VERSION "dbc-export 1 2026.26.6.5"

NS_ :

BS_:

BU_: APB APP APS DAS EPAS3S ESP GTW IBST PARK RADC RCM RCM2 RCM3 TPMS TRCM USM

BO_ 882 TRCM_alertMatrix: 8 TRCM
 SG_ TRCM_matrixIndex M : 0|4@1+ (1,0) [0|15] "" Vector__XXX
 SG_ TRCM_a001_airbagsDisabled m0 : 4|1@1+ (1,0) [0|1] "" Vector__XXX
 SG_ TRCM_a002_systemDisabled m0 : 5|1@1+ (1,0) [0|1] "" Vector__XXX
 SG_ TRCM_a003_SWAssertion m0 : 6|1@1+ (1,0) [0|1] "" Vector__XXX
 SG_ TRCM_a004_internalFailure m0 : 7|1@1+ (1,0) [0|1] "" Vector__XXX
 SG_ TRCM_a005_CANTXError m0 : 8|1@1+ (1,0) [0|1] "" Vector__XXX
 SG_ TRCM_a006_CANTX_cyclicError m0 : 9|1@1+ (1,0) [0|1] "" Vector__XXX
 SG_ TRCM_a007_chassisChecksumError m0 : 10|1@1+ (1,0) [0|1] "" Vector__XXX
 SG_ TRCM_a008_chassisCounterError m0 : 11|1@1+ (1,0) [0|1] "" Vector__XXX
 SG_ TRCM_a009_partyChecksumError m0 : 12|1@1+ (1,0) [0|1] "" Vector__XXX
 SG_ TRCM_a010_partyCounterError m0 : 13|1@1+ (1,0) [0|1] "" Vector__XXX
 SG_ TRCM_a011_edrDataLocked m0 : 14|1@1+ (1,0) [0|1] "" Vector__XXX
 SG_ TRCM_a012_asm5TemperatureOutside m0 : 15|1@1+ (1,0) [0|1] "" Vector__XXX
 SG_ TRCM_a013_AlertManagerFault m0 : 16|1@1+ (1,0) [0|1] "" Vector__XXX
 SG_ TRCM_a014_asm3TemperatureOutside m0 : 17|1@1+ (1,0) [0|1] "" Vector__XXX
 SG_ TRCM_a015_NVMMError m0 : 18|1@1+ (1,0) [0|1] "" Vector__XXX
 SG_ TRCM_a016_NVMMRecordError m0 : 19|1@1+ (1,0) [0|1] "" Vector__XXX
 SG_ TRCM_a017_asm5TemperatureOutside m0 : 20|1@1+ (1,0) [0|1] "" Vector__XXX
 SG_ TRCM_a018_asm3TemperatureOutside m0 : 21|1@1+ (1,0) [0|1] "" Vector__XXX
 SG_ TRCM_a019_Task500usError m0 : 22|1@1+ (1,0) [0|1] "" Vector__XXX
 SG_ TRCM_a020_asm3ComStatusError m0 : 23|1@1+ (1,0) [0|1] "" Vector__XXX
 SG_ TRCM_a021_TaskSchedulerError m0 : 24|1@1+ (1,0) [0|1] "" Vector__XXX
 SG_ TRCM_a022_TaskInitError m0 : 25|1@1+ (1,0) [0|1] "" Vector__XXX
 SG_ TRCM_a023_asm3ArsStatusXError m0 : 26|1@1+ (1,0) [0|1] "" Vector__XXX
 SG_ TRCM_a024_asm3AccStatusError m0 : 27|1@1+ (1,0) [0|1] "" Vector__XXX
 SG_ TRCM_a025_CHCANBusFaults m0 : 28|1@1+ (1,0) [0|1] "" Vector__XXX
 SG_ TRCM_a026_airbagAsicDiagnosticFa m0 : 29|1@1+ (1,0) [0|1] "" Vector__XXX
 SG_ TRCM_a027_airbagAsicDeploymentDi m0 : 30|1@1+ (1,0) [0|1] "" Vector__XXX
 SG_ TRCM_a028_chassisLengthError m0 : 31|1@1+ (1,0) [0|1] "" Vector__XXX
 SG_ TRCM_a030_ECULogUploadRequest m0 : 33|1@1+ (1,0) [0|1] "" Vector__XXX
 SG_ TRCM_a031_UDSActive m0 : 34|1@1+ (1,0) [0|1] "" Vector__XXX
 SG_ TRCM_a032_ScrollCreated m0 : 35|1@1+ (1,0) [0|1] "" Vector__XXX
 SG_ TRCM_a033_HercLogCreated m0 : 36|1@1+ (1,0) [0|1] "" Vector__XXX
 SG_ TRCM_a034_apClipTrigger m0 : 37|1@1+ (1,0) [0|1] "" Vector__XXX
 SG_ TRCM_a035_hvDisconnectCommanded m0 : 38|1@1+ (1,0) [0|1] "" Vector__XXX
 SG_ TRCM_a036_crashDetected m0 : 39|1@1+ (1,0) [0|1] "" Vector__XXX
 SG_ TRCM_a037_nearDeploy m0 : 40|1@1+ (1,0) [0|1] "" Vector__XXX
 SG_ TRCM_a038_ens1Degraded m0 : 41|1@1+ (1,0) [0|1] "" Vector__XXX
 SG_ TRCM_a039_ens2Degraded m0 : 42|1@1+ (1,0) [0|1] "" Vector__XXX
 SG_ TRCM_a040_task500usOverrunDebug m0 : 43|1@1+ (1,0) [0|1] "" Vector__XXX
 SG_ TRCM_a041_HighCPULoad m0 : 44|1@1+ (1,0) [0|1] "" Vector__XXX
 SG_ TRCM_a042_HighStackUsage m0 : 45|1@1+ (1,0) [0|1] "" Vector__XXX
 SG_ TRCM_a043_Task1msError m0 : 46|1@1+ (1,0) [0|1] "" Vector__XXX
 SG_ TRCM_a044_Task10msError m0 : 47|1@1+ (1,0) [0|1] "" Vector__XXX
 SG_ TRCM_a045_Task100msError m0 : 48|1@1+ (1,0) [0|1] "" Vector__XXX
 SG_ TRCM_a046_Task1000msError m0 : 49|1@1+ (1,0) [0|1] "" Vector__XXX
 SG_ TRCM_a047_vinNotLearned m0 : 50|1@1+ (1,0) [0|1] "" Vector__XXX
 SG_ TRCM_a048_vinMismatch m0 : 51|1@1+ (1,0) [0|1] "" Vector__XXX
 SG_ TRCM_a049_nvmDebugInfo m0 : 52|1@1+ (1,0) [0|1] "" Vector__XXX
 SG_ TRCM_a050_partyLengthError m0 : 53|1@1+ (1,0) [0|1] "" Vector__XXX
 SG_ TRCM_a051_systemSelfTestTimeout m0 : 54|1@1+ (1,0) [0|1] "" Vector__XXX
 SG_ TRCM_a057_HVP_MIA m0 : 60|1@1+ (1,0) [0|1] "" Vector__XXX
 SG_ TRCM_a058_inputRHighSyncDebug m0 : 61|1@1+ (1,0) [0|1] "" Vector__XXX
 SG_ TRCM_a059_inputResistanceHigh m0 : 62|1@1+ (1,0) [0|1] "" Vector__XXX
 SG_ TRCM_a060_engineeringBuild m0 : 63|1@1+ (1,0) [0|1] "" Vector__XXX
 SG_ TRCM_a061_XCPConnected m1 : 4|1@1+ (1,0) [0|1] "" Vector__XXX
 SG_ TRCM_a062_XCPWasConnected m1 : 5|1@1+ (1,0) [0|1] "" Vector__XXX
 SG_ TRCM_a063_SwitchFault m1 : 6|1@1+ (1,0) [0|1] "" Vector__XXX
 SG_ TRCM_a064_busSleepReqTimeout m1 : 7|1@1+ (1,0) [0|1] "" Vector__XXX
 SG_ TRCM_a065_vSafingFetUnderVoltage m1 : 8|1@1+ (1,0) [0|1] "" Vector__XXX
 SG_ TRCM_a066_leftPowerIssue m1 : 9|1@1+ (1,0) [0|1] "" Vector__XXX
 SG_ TRCM_a067_rightPowerIssue m1 : 10|1@1+ (1,0) [0|1] "" Vector__XXX
 SG_ TRCM_a068_vBusCUnderVoltage m1 : 11|1@1+ (1,0) [0|1] "" Vector__XXX
 SG_ TRCM_a069_swAppBoot m1 : 12|1@1+ (1,0) [0|1] "" Vector__XXX
 SG_ TRCM_a070_asm3StatusError m1 : 13|1@1+ (1,0) [0|1] "" Vector__XXX
 SG_ TRCM_a071_asm3DeviceFaulted m1 : 14|1@1+ (1,0) [0|1] "" Vector__XXX
 SG_ TRCM_a072_ais2120StatusError m1 : 15|1@1+ (1,0) [0|1] "" Vector__XXX
 SG_ TRCM_a073_ais2120DeviceFaulted m1 : 16|1@1+ (1,0) [0|1] "" Vector__XXX
 SG_ TRCM_a074_ais2120SelfTestXPositi m1 : 17|1@1+ (1,0) [0|1] "" Vector__XXX
 SG_ TRCM_a075_ais2120SelfTestXNegati m1 : 18|1@1+ (1,0) [0|1] "" Vector__XXX
 SG_ TRCM_a076_ais2120SelfTestYPositi m1 : 19|1@1+ (1,0) [0|1] "" Vector__XXX
 SG_ TRCM_a077_ais2120SelfTestYNegati m1 : 20|1@1+ (1,0) [0|1] "" Vector__XXX
 SG_ TRCM_a078_imuSensorSignalMonitor m1 : 21|1@1+ (1,0) [0|1] "" Vector__XXX
 SG_ TRCM_a081_powerLossDetected m1 : 24|1@1+ (1,0) [0|1] "" Vector__XXX
 SG_ TRCM_a082_VCRIGHT_IPC_MIA m1 : 25|1@1+ (1,0) [0|1] "" Vector__XXX
 SG_ TRCM_a083_VCLEFT_IPC_MIA m1 : 26|1@1+ (1,0) [0|1] "" Vector__XXX
 SG_ TRCM_a084_TPMS_MIA m1 : 27|1@1+ (1,0) [0|1] "" Vector__XXX
 SG_ TRCM_a085_CCCM_MIA m1 : 28|1@1+ (1,0) [0|1] "" Vector__XXX
 SG_ TRCM_a086_VCBATT_MIA m1 : 29|1@1+ (1,0) [0|1] "" Vector__XXX
 SG_ TRCM_a087_DIREL_MIA m1 : 30|1@1+ (1,0) [0|1] "" Vector__XXX
 SG_ TRCM_a088_DIRER_MIA m1 : 31|1@1+ (1,0) [0|1] "" Vector__XXX
 SG_ TRCM_a089_IBST_MIA m1 : 32|1@1+ (1,0) [0|1] "" Vector__XXX
 SG_ TRCM_a090_APS_MIA m1 : 33|1@1+ (1,0) [0|1] "" Vector__XXX
 SG_ TRCM_a091_CMPD_MIA m1 : 34|1@1+ (1,0) [0|1] "" Vector__XXX
 SG_ TRCM_a092_VCSEATD_MIA m1 : 35|1@1+ (1,0) [0|1] "" Vector__XXX
 SG_ TRCM_a093_VCSEATP_MIA m1 : 36|1@1+ (1,0) [0|1] "" Vector__XXX
 SG_ TRCM_a094_EPAS3P_MIA m1 : 37|1@1+ (1,0) [0|1] "" Vector__XXX
 SG_ TRCM_a095_CHG_MIA m1 : 38|1@1+ (1,0) [0|1] "" Vector__XXX
 SG_ TRCM_a096_OCS1P_MIA m1 : 39|1@1+ (1,0) [0|1] "" Vector__XXX
 SG_ TRCM_a097_CMP_MIA m1 : 40|1@1+ (1,0) [0|1] "" Vector__XXX
 SG_ TRCM_a098_DIR_MIA m1 : 41|1@1+ (1,0) [0|1] "" Vector__XXX
 SG_ TRCM_a099_PARK_MIA m1 : 42|1@1+ (1,0) [0|1] "" Vector__XXX
 SG_ TRCM_a100_CANbus_MIA m1 : 43|1@1+ (1,0) [0|1] "" Vector__XXX
 SG_ TRCM_a101_PM_MIA m1 : 44|1@1+ (1,0) [0|1] "" Vector__XXX
 SG_ TRCM_a102_PTC_MIA m1 : 45|1@1+ (1,0) [0|1] "" Vector__XXX
 SG_ TRCM_a103_CP_MIA m1 : 46|1@1+ (1,0) [0|1] "" Vector__XXX
 SG_ TRCM_a104_DAS_MIA m1 : 47|1@1+ (1,0) [0|1] "" Vector__XXX
 SG_ TRCM_a105_TAS_MIA m1 : 48|1@1+ (1,0) [0|1] "" Vector__XXX
 SG_ TRCM_a106_PCS_MIA m1 : 49|1@1+ (1,0) [0|1] "" Vector__XXX
 SG_ TRCM_a107_BMS_MIA m1 : 50|1@1+ (1,0) [0|1] "" Vector__XXX
 SG_ TRCM_a108_DIF_MIA m1 : 51|1@1+ (1,0) [0|1] "" Vector__XXX
 SG_ TRCM_a109_RCM_MIA m1 : 52|1@1+ (1,0) [0|1] "" Vector__XXX
 SG_ TRCM_a110_GTW_MIA m1 : 53|1@1+ (1,0) [0|1] "" Vector__XXX
 SG_ TRCM_a111_EPBR_MIA m1 : 54|1@1+ (1,0) [0|1] "" Vector__XXX
 SG_ TRCM_a112_EPBL_MIA m1 : 55|1@1+ (1,0) [0|1] "" Vector__XXX
 SG_ TRCM_a113_UI_MIA m1 : 56|1@1+ (1,0) [0|1] "" Vector__XXX
 SG_ TRCM_a114_ESP_MIA m1 : 57|1@1+ (1,0) [0|1] "" Vector__XXX
 SG_ TRCM_a115_VCSEC_MIA m1 : 58|1@1+ (1,0) [0|1] "" Vector__XXX
 SG_ TRCM_a116_VCRIGHT_MIA m1 : 59|1@1+ (1,0) [0|1] "" Vector__XXX
 SG_ TRCM_a117_VCLEFT_MIA m1 : 60|1@1+ (1,0) [0|1] "" Vector__XXX
 SG_ TRCM_a118_VCFRONT_MIA m1 : 61|1@1+ (1,0) [0|1] "" Vector__XXX
 SG_ TRCM_a119_SCCM_MIA m1 : 62|1@1+ (1,0) [0|1] "" Vector__XXX
 SG_ TRCM_a120_DI_DRIVE_MIA m1 : 63|1@1+ (1,0) [0|1] "" Vector__XXX
 SG_ TRCM_a121_buckleStatusFrontLeftS m2 : 4|1@1+ (1,0) [0|1] "" Vector__XXX
 SG_ TRCM_a122_buckleStatusFrontRight m2 : 5|1@1+ (1,0) [0|1] "" Vector__XXX
 SG_ TRCM_a123_buckleStatusRearLeftSi m2 : 6|1@1+ (1,0) [0|1] "" Vector__XXX
 SG_ TRCM_a124_buckleStatusRearRightS m2 : 7|1@1+ (1,0) [0|1] "" Vector__XXX
 SG_ TRCM_a125_occupantClassification m2 : 8|1@1+ (1,0) [0|1] "" Vector__XXX
 SG_ TRCM_a126_seatTrackPositionLeftS m2 : 9|1@1+ (1,0) [0|1] "" Vector__XXX
 SG_ TRCM_a127_seatTrackPositionRight m2 : 10|1@1+ (1,0) [0|1] "" Vector__XXX
 SG_ TRCM_a135_asm5StatusError m2 : 18|1@1+ (1,0) [0|1] "" Vector__XXX
 SG_ TRCM_a136_asm5DeviceFaulted m2 : 19|1@1+ (1,0) [0|1] "" Vector__XXX
 SG_ TRCM_a137_ext1AsicSnoopTestFaile m2 : 20|1@1+ (1,0) [0|1] "" Vector__XXX
 SG_ TRCM_a138_ext2AsicSnoopTestFaile m2 : 21|1@1+ (1,0) [0|1] "" Vector__XXX
 SG_ TRCM_a145_frontCenterAccelReport m2 : 28|1@1+ (1,0) [0|1] "" Vector__XXX
 SG_ TRCM_a146_frontCenterAccelGenera m2 : 29|1@1+ (1,0) [0|1] "" Vector__XXX
 SG_ TRCM_a147_frontCenterAccelElectr m2 : 30|1@1+ (1,0) [0|1] "" Vector__XXX
 SG_ TRCM_a148_frontCenterAccelConfig m2 : 31|1@1+ (1,0) [0|1] "" Vector__XXX
 SG_ TRCM_a149_frontCenterAccelSignal m2 : 32|1@1+ (1,0) [0|1] "" Vector__XXX
 SG_ TRCM_a150_frontLeftAccelReported m2 : 33|1@1+ (1,0) [0|1] "" Vector__XXX
 SG_ TRCM_a151_frontLeftAccelGeneralI m2 : 34|1@1+ (1,0) [0|1] "" Vector__XXX
 SG_ TRCM_a152_frontLeftAccelElectric m2 : 35|1@1+ (1,0) [0|1] "" Vector__XXX
 SG_ TRCM_a153_frontLeftAccelConfigEr m2 : 36|1@1+ (1,0) [0|1] "" Vector__XXX
 SG_ TRCM_a154_frontLeftAccelSignalMo m2 : 37|1@1+ (1,0) [0|1] "" Vector__XXX
 SG_ TRCM_a155_frontLeftDoorPressureR m2 : 38|1@1+ (1,0) [0|1] "" Vector__XXX
 SG_ TRCM_a156_frontLeftDoorPressureG m2 : 39|1@1+ (1,0) [0|1] "" Vector__XXX
 SG_ TRCM_a157_frontLeftDoorPressureE m2 : 40|1@1+ (1,0) [0|1] "" Vector__XXX
 SG_ TRCM_a158_frontLeftDoorPressureC m2 : 41|1@1+ (1,0) [0|1] "" Vector__XXX
 SG_ TRCM_a159_frontLeftDoorPressureS m2 : 42|1@1+ (1,0) [0|1] "" Vector__XXX
 SG_ TRCM_a160_frontRightAccelReporte m2 : 43|1@1+ (1,0) [0|1] "" Vector__XXX
 SG_ TRCM_a161_frontRightAccelGeneral m2 : 44|1@1+ (1,0) [0|1] "" Vector__XXX
 SG_ TRCM_a162_frontRightAccelElectri m2 : 45|1@1+ (1,0) [0|1] "" Vector__XXX
 SG_ TRCM_a163_frontRightAccelConfigE m2 : 46|1@1+ (1,0) [0|1] "" Vector__XXX
 SG_ TRCM_a164_frontRightAccelSignalM m2 : 47|1@1+ (1,0) [0|1] "" Vector__XXX
 SG_ TRCM_a165_frontRightDoorPressure m2 : 48|1@1+ (1,0) [0|1] "" Vector__XXX
 SG_ TRCM_a166_frontRightDoorPressure m2 : 49|1@1+ (1,0) [0|1] "" Vector__XXX
 SG_ TRCM_a167_frontRightDoorPressure m2 : 50|1@1+ (1,0) [0|1] "" Vector__XXX
 SG_ TRCM_a168_frontRightDoorPressure m2 : 51|1@1+ (1,0) [0|1] "" Vector__XXX
 SG_ TRCM_a169_frontRightDoorPressure m2 : 52|1@1+ (1,0) [0|1] "" Vector__XXX
 SG_ TRCM_a170_leftBPillarAccelReport m2 : 53|1@1+ (1,0) [0|1] "" Vector__XXX
 SG_ TRCM_a171_leftBPillarAccelGenera m2 : 54|1@1+ (1,0) [0|1] "" Vector__XXX
 SG_ TRCM_a172_leftBPillarAccelElectr m2 : 55|1@1+ (1,0) [0|1] "" Vector__XXX
 SG_ TRCM_a173_leftBPillarAccelConfig m2 : 56|1@1+ (1,0) [0|1] "" Vector__XXX
 SG_ TRCM_a174_leftBPillarAccelSignal m2 : 57|1@1+ (1,0) [0|1] "" Vector__XXX
 SG_ TRCM_a175_leftCPillarAccelReport m2 : 58|1@1+ (1,0) [0|1] "" Vector__XXX
 SG_ TRCM_a176_leftCPillarAccelGenera m2 : 59|1@1+ (1,0) [0|1] "" Vector__XXX
 SG_ TRCM_a177_leftCPillarAccelElectr m2 : 60|1@1+ (1,0) [0|1] "" Vector__XXX
 SG_ TRCM_a178_leftCPillarAccelConfig m2 : 61|1@1+ (1,0) [0|1] "" Vector__XXX
 SG_ TRCM_a179_leftCPillarAccelSignal m2 : 62|1@1+ (1,0) [0|1] "" Vector__XXX
 SG_ TRCM_a190_rearLeftDoorPressureRe m3 : 13|1@1+ (1,0) [0|1] "" Vector__XXX
 SG_ TRCM_a191_rearLeftDoorPressureGe m3 : 14|1@1+ (1,0) [0|1] "" Vector__XXX
 SG_ TRCM_a192_rearLeftDoorPressureEl m3 : 15|1@1+ (1,0) [0|1] "" Vector__XXX
 SG_ TRCM_a193_rearLeftDoorPressureCo m3 : 16|1@1+ (1,0) [0|1] "" Vector__XXX
 SG_ TRCM_a194_rearLeftDoorPressureSi m3 : 17|1@1+ (1,0) [0|1] "" Vector__XXX
 SG_ TRCM_a195_rearRightDoorPressureR m3 : 18|1@1+ (1,0) [0|1] "" Vector__XXX
 SG_ TRCM_a196_rearRightDoorPressureG m3 : 19|1@1+ (1,0) [0|1] "" Vector__XXX
 SG_ TRCM_a197_rearRightDoorPressureE m3 : 20|1@1+ (1,0) [0|1] "" Vector__XXX
 SG_ TRCM_a198_rearRightDoorPressureC m3 : 21|1@1+ (1,0) [0|1] "" Vector__XXX
 SG_ TRCM_a199_rearRightDoorPressureS m3 : 22|1@1+ (1,0) [0|1] "" Vector__XXX
 SG_ TRCM_a200_rightBPillarAccelRepor m3 : 23|1@1+ (1,0) [0|1] "" Vector__XXX
 SG_ TRCM_a201_rightBPillarAccelGener m3 : 24|1@1+ (1,0) [0|1] "" Vector__XXX
 SG_ TRCM_a202_rightBPillarAccelElect m3 : 25|1@1+ (1,0) [0|1] "" Vector__XXX
 SG_ TRCM_a203_rightBPillarAccelConfi m3 : 26|1@1+ (1,0) [0|1] "" Vector__XXX
 SG_ TRCM_a204_rightBPillarAccelSigna m3 : 27|1@1+ (1,0) [0|1] "" Vector__XXX
 SG_ TRCM_a205_rightCPillarAccelRepor m3 : 28|1@1+ (1,0) [0|1] "" Vector__XXX
 SG_ TRCM_a206_rightCPillarAccelGener m3 : 29|1@1+ (1,0) [0|1] "" Vector__XXX
 SG_ TRCM_a207_rightCPillarAccelElect m3 : 30|1@1+ (1,0) [0|1] "" Vector__XXX
 SG_ TRCM_a208_rightCPillarAccelConfi m3 : 31|1@1+ (1,0) [0|1] "" Vector__XXX
 SG_ TRCM_a209_rightCPillarAccelSigna m3 : 32|1@1+ (1,0) [0|1] "" Vector__XXX
 SG_ TRCM_a272_asm5ComStatusError m4 : 35|1@1+ (1,0) [0|1] "" Vector__XXX
 SG_ TRCM_a273_asm5ArsStatusXError m4 : 36|1@1+ (1,0) [0|1] "" Vector__XXX
 SG_ TRCM_a274_asm5ArsStatusZError m4 : 37|1@1+ (1,0) [0|1] "" Vector__XXX
 SG_ TRCM_a275_asm5AccStatusError m4 : 38|1@1+ (1,0) [0|1] "" Vector__XXX
 SG_ TRCM_a276_watchdogStatus m4 : 39|1@1+ (1,0) [0|1] "" Vector__XXX
 SG_ TRCM_a278_safingEngine0Armed m4 : 41|1@1+ (1,0) [0|1] "" Vector__XXX
 SG_ TRCM_a279_safingEngine1Armed m4 : 42|1@1+ (1,0) [0|1] "" Vector__XXX
 SG_ TRCM_a280_safingEngine2Armed m4 : 43|1@1+ (1,0) [0|1] "" Vector__XXX
 SG_ TRCM_a281_safingEngine3Armed m4 : 44|1@1+ (1,0) [0|1] "" Vector__XXX
 SG_ TRCM_a282_safingEngine4Armed m4 : 45|1@1+ (1,0) [0|1] "" Vector__XXX
 SG_ TRCM_a283_safingEngine5Armed m4 : 46|1@1+ (1,0) [0|1] "" Vector__XXX
 SG_ TRCM_a284_safingEngine6Armed m4 : 47|1@1+ (1,0) [0|1] "" Vector__XXX
 SG_ TRCM_a285_safingEngine7Armed m4 : 48|1@1+ (1,0) [0|1] "" Vector__XXX
 SG_ TRCM_a286_safingEngine8Armed m4 : 49|1@1+ (1,0) [0|1] "" Vector__XXX
 SG_ TRCM_a287_safingEngine9Armed m4 : 50|1@1+ (1,0) [0|1] "" Vector__XXX
 SG_ TRCM_a288_safingEngine10Armed m4 : 51|1@1+ (1,0) [0|1] "" Vector__XXX
 SG_ TRCM_a289_safingEngine11Armed m4 : 52|1@1+ (1,0) [0|1] "" Vector__XXX
 SG_ TRCM_a290_safingEngine12Armed m4 : 53|1@1+ (1,0) [0|1] "" Vector__XXX
 SG_ TRCM_a291_safingEngine13Armed m4 : 54|1@1+ (1,0) [0|1] "" Vector__XXX
 SG_ TRCM_a292_safingEngine14Armed m4 : 55|1@1+ (1,0) [0|1] "" Vector__XXX
 SG_ TRCM_a293_safingEngine15Armed m4 : 56|1@1+ (1,0) [0|1] "" Vector__XXX
 SG_ TRCM_a294_safingEngine16Armed m4 : 57|1@1+ (1,0) [0|1] "" Vector__XXX
 SG_ TRCM_a295_safingEngine17Armed m4 : 58|1@1+ (1,0) [0|1] "" Vector__XXX
 SG_ TRCM_a296_safingEngine18Armed m4 : 59|1@1+ (1,0) [0|1] "" Vector__XXX
 SG_ TRCM_a297_safingEngine19Armed m4 : 60|1@1+ (1,0) [0|1] "" Vector__XXX
 SG_ TRCM_a298_safingEngine20Armed m4 : 61|1@1+ (1,0) [0|1] "" Vector__XXX
 SG_ TRCM_a299_safingEngine21Armed m4 : 62|1@1+ (1,0) [0|1] "" Vector__XXX
 SG_ TRCM_a300_driverAirbagStage1Supp m4 : 63|1@1+ (1,0) [0|1] "" Vector__XXX
 SG_ TRCM_a301_passengerAirbagStage1S m5 : 4|1@1+ (1,0) [0|1] "" Vector__XXX
 SG_ TRCM_a302_driverAirbagStage2Supp m5 : 5|1@1+ (1,0) [0|1] "" Vector__XXX
 SG_ TRCM_a303_driverAirbagActiveVent m5 : 6|1@1+ (1,0) [0|1] "" Vector__XXX
 SG_ TRCM_a304_passengerAirbagStage2S m5 : 7|1@1+ (1,0) [0|1] "" Vector__XXX
 SG_ TRCM_a305_passengerAirbagActiveV m5 : 8|1@1+ (1,0) [0|1] "" Vector__XXX
 SG_ TRCM_a306_inboardSeatAirbagSuppr m5 : 9|1@1+ (1,0) [0|1] "" Vector__XXX
 SG_ TRCM_a308_kneeAirbagLeftSuppress m5 : 11|1@1+ (1,0) [0|1] "" Vector__XXX
 SG_ TRCM_a309_kneeAirbagRightSuppres m5 : 12|1@1+ (1,0) [0|1] "" Vector__XXX
 SG_ TRCM_a310_curtainAirbagLeftSuppr m5 : 13|1@1+ (1,0) [0|1] "" Vector__XXX
 SG_ TRCM_a311_curtainAirbagRightSupp m5 : 14|1@1+ (1,0) [0|1] "" Vector__XXX
 SG_ TRCM_a312_seatbeltLoadLimiterFro m5 : 15|1@1+ (1,0) [0|1] "" Vector__XXX
 SG_ TRCM_a313_seatbeltLoadLimiterFro m5 : 16|1@1+ (1,0) [0|1] "" Vector__XXX
 SG_ TRCM_a314_seatbeltShoulderPreten m5 : 17|1@1+ (1,0) [0|1] "" Vector__XXX
 SG_ TRCM_a315_seatbeltShoulderPreten m5 : 18|1@1+ (1,0) [0|1] "" Vector__XXX
 SG_ TRCM_a316_seatbeltLapPretensione m5 : 19|1@1+ (1,0) [0|1] "" Vector__XXX
 SG_ TRCM_a317_seatbeltLapPretensione m5 : 20|1@1+ (1,0) [0|1] "" Vector__XXX
 SG_ TRCM_a318_outboardSeatAirbagLeft m5 : 21|1@1+ (1,0) [0|1] "" Vector__XXX
 SG_ TRCM_a319_outboardSeatAirbagRigh m5 : 22|1@1+ (1,0) [0|1] "" Vector__XXX
 SG_ TRCM_a320_hoodLifterLeftSuppress m5 : 23|1@1+ (1,0) [0|1] "" Vector__XXX
 SG_ TRCM_a321_hoodLifterRightSuppres m5 : 24|1@1+ (1,0) [0|1] "" Vector__XXX
 SG_ TRCM_a322_seatbeltShoulderPreten m5 : 25|1@1+ (1,0) [0|1] "" Vector__XXX
 SG_ TRCM_a323_seatbeltShoulderPreten m5 : 26|1@1+ (1,0) [0|1] "" Vector__XXX
 SG_ TRCM_a332_driverAirbagStage1Depl m5 : 35|1@1+ (1,0) [0|1] "" Vector__XXX
 SG_ TRCM_a333_passengerAirbagStage1D m5 : 36|1@1+ (1,0) [0|1] "" Vector__XXX
 SG_ TRCM_a334_driverAirbagStage2Depl m5 : 37|1@1+ (1,0) [0|1] "" Vector__XXX
 SG_ TRCM_a335_driverAirbagActiveVent m5 : 38|1@1+ (1,0) [0|1] "" Vector__XXX
 SG_ TRCM_a336_passengerAirbagStage2D m5 : 39|1@1+ (1,0) [0|1] "" Vector__XXX
 SG_ TRCM_a337_passengerAirbagActiveV m5 : 40|1@1+ (1,0) [0|1] "" Vector__XXX
 SG_ TRCM_a338_inboardSeatAirbagDeplo m5 : 41|1@1+ (1,0) [0|1] "" Vector__XXX
 SG_ TRCM_a340_kneeAirbagLeftDeployed m5 : 43|1@1+ (1,0) [0|1] "" Vector__XXX
 SG_ TRCM_a341_kneeAirbagRightDeploye m5 : 44|1@1+ (1,0) [0|1] "" Vector__XXX
 SG_ TRCM_a342_curtainAirbagLeftDeplo m5 : 45|1@1+ (1,0) [0|1] "" Vector__XXX
 SG_ TRCM_a343_curtainAirbagRightDepl m5 : 46|1@1+ (1,0) [0|1] "" Vector__XXX
 SG_ TRCM_a344_seatbeltLoadLimiterFro m5 : 47|1@1+ (1,0) [0|1] "" Vector__XXX
 SG_ TRCM_a345_seatbeltLoadLimiterFro m5 : 48|1@1+ (1,0) [0|1] "" Vector__XXX
 SG_ TRCM_a346_seatbeltShoulderPreten m5 : 49|1@1+ (1,0) [0|1] "" Vector__XXX
 SG_ TRCM_a347_seatbeltShoulderPreten m5 : 50|1@1+ (1,0) [0|1] "" Vector__XXX
 SG_ TRCM_a348_seatbeltLapPretensione m5 : 51|1@1+ (1,0) [0|1] "" Vector__XXX
 SG_ TRCM_a349_seatbeltLapPretensione m5 : 52|1@1+ (1,0) [0|1] "" Vector__XXX
 SG_ TRCM_a350_outboardSeatAirbagLeft m5 : 53|1@1+ (1,0) [0|1] "" Vector__XXX
 SG_ TRCM_a351_outboardSeatAirbagRigh m5 : 54|1@1+ (1,0) [0|1] "" Vector__XXX
 SG_ TRCM_a352_hoodLifterLeftDeployed m5 : 55|1@1+ (1,0) [0|1] "" Vector__XXX
 SG_ TRCM_a353_hoodLifterRightDeploye m5 : 56|1@1+ (1,0) [0|1] "" Vector__XXX
 SG_ TRCM_a354_seatbeltShoulderPreten m5 : 57|1@1+ (1,0) [0|1] "" Vector__XXX
 SG_ TRCM_a355_seatbeltShoulderPreten m5 : 58|1@1+ (1,0) [0|1] "" Vector__XXX
 SG_ TRCM_a364_safingEngine0NoValidDa m6 : 7|1@1+ (1,0) [0|1] "" Vector__XXX
 SG_ TRCM_a365_safingEngine1NoValidDa m6 : 8|1@1+ (1,0) [0|1] "" Vector__XXX
 SG_ TRCM_a366_safingEngine2NoValidDa m6 : 9|1@1+ (1,0) [0|1] "" Vector__XXX
 SG_ TRCM_a367_safingEngine3NoValidDa m6 : 10|1@1+ (1,0) [0|1] "" Vector__XXX
 SG_ TRCM_a368_safingEngine4NoValidDa m6 : 11|1@1+ (1,0) [0|1] "" Vector__XXX
 SG_ TRCM_a369_safingEngine5NoValidDa m6 : 12|1@1+ (1,0) [0|1] "" Vector__XXX
 SG_ TRCM_a370_safingEngine6NoValidDa m6 : 13|1@1+ (1,0) [0|1] "" Vector__XXX
 SG_ TRCM_a371_safingEngine7NoValidDa m6 : 14|1@1+ (1,0) [0|1] "" Vector__XXX
 SG_ TRCM_a372_safingEngine8NoValidDa m6 : 15|1@1+ (1,0) [0|1] "" Vector__XXX
 SG_ TRCM_a373_safingEngine9NoValidDa m6 : 16|1@1+ (1,0) [0|1] "" Vector__XXX
 SG_ TRCM_a374_safingEngine10NoValidD m6 : 17|1@1+ (1,0) [0|1] "" Vector__XXX
 SG_ TRCM_a375_safingEngine11NoValidD m6 : 18|1@1+ (1,0) [0|1] "" Vector__XXX
 SG_ TRCM_a376_safingEngine12NoValidD m6 : 19|1@1+ (1,0) [0|1] "" Vector__XXX
 SG_ TRCM_a377_safingEngine13NoValidD m6 : 20|1@1+ (1,0) [0|1] "" Vector__XXX
 SG_ TRCM_a378_safingEngine14NoValidD m6 : 21|1@1+ (1,0) [0|1] "" Vector__XXX
 SG_ TRCM_a379_safingEngine15NoValidD m6 : 22|1@1+ (1,0) [0|1] "" Vector__XXX
 SG_ TRCM_a380_safingEngine16NoValidD m6 : 23|1@1+ (1,0) [0|1] "" Vector__XXX
 SG_ TRCM_a381_safingEngine17NoValidD m6 : 24|1@1+ (1,0) [0|1] "" Vector__XXX
 SG_ TRCM_a382_safingEngine18NoValidD m6 : 25|1@1+ (1,0) [0|1] "" Vector__XXX
 SG_ TRCM_a383_safingEngine19NoValidD m6 : 26|1@1+ (1,0) [0|1] "" Vector__XXX
 SG_ TRCM_a384_safingEngine20NoValidD m6 : 27|1@1+ (1,0) [0|1] "" Vector__XXX
 SG_ TRCM_a385_safingEngine21NoValidD m6 : 28|1@1+ (1,0) [0|1] "" Vector__XXX
 SG_ TRCM_a387_primaryAsicResetSource m6 : 30|1@1+ (1,0) [0|1] "" Vector__XXX
 SG_ TRCM_a388_cpuLoadHigh m6 : 31|1@1+ (1,0) [0|1] "" Vector__XXX
 SG_ TRCM_a389_asicPwrStatusError m6 : 32|1@1+ (1,0) [0|1] "" Vector__XXX
 SG_ TRCM_a390_systemAsicClockOrOpera m6 : 33|1@1+ (1,0) [0|1] "" Vector__XXX
 SG_ TRCM_a391_extAsic1ClockOrOperati m6 : 34|1@1+ (1,0) [0|1] "" Vector__XXX
 SG_ TRCM_a392_extAsic2ClockOrOperati m6 : 35|1@1+ (1,0) [0|1] "" Vector__XXX
 SG_ TRCM_a393_depAdcConvertRatioErro m6 : 36|1@1+ (1,0) [0|1] "" Vector__XXX
 SG_ TRCM_a394_gspiGlobalStatusWordEr m6 : 37|1@1+ (1,0) [0|1] "" Vector__XXX
 SG_ TRCM_a395_imuUncalibrated m6 : 38|1@1+ (1,0) [0|1] "" Vector__XXX
 SG_ TRCM_a396_spiCommunicationProgra m6 : 39|1@1+ (1,0) [0|1] "" Vector__XXX
 SG_ TRCM_a397_safingMonitorError m6 : 40|1@1+ (1,0) [0|1] "" Vector__XXX
 SG_ TRCM_a398_asicNvmReprogrammed m6 : 41|1@1+ (1,0) [0|1] "" Vector__XXX
 SG_ TRCM_a399_imuCalibrationComplete m6 : 42|1@1+ (1,0) [0|1] "" Vector__XXX
 SG_ TRCM_a400_driverAirbagStage1Issu m6 : 43|1@1+ (1,0) [0|1] "" Vector__XXX
 SG_ TRCM_a401_passengerAirbagStage1I m6 : 44|1@1+ (1,0) [0|1] "" Vector__XXX
 SG_ TRCM_a402_driverAirbagStage2Issu m6 : 45|1@1+ (1,0) [0|1] "" Vector__XXX
 SG_ TRCM_a403_driverAirbagActiveVent m6 : 46|1@1+ (1,0) [0|1] "" Vector__XXX
 SG_ TRCM_a404_passengerAirbagStage2I m6 : 47|1@1+ (1,0) [0|1] "" Vector__XXX
 SG_ TRCM_a405_passengerAirbagActiveV m6 : 48|1@1+ (1,0) [0|1] "" Vector__XXX
 SG_ TRCM_a406_inboardSeatAirbagIssue m6 : 49|1@1+ (1,0) [0|1] "" Vector__XXX
 SG_ TRCM_a408_kneeAirbagLeftIssue m6 : 51|1@1+ (1,0) [0|1] "" Vector__XXX
 SG_ TRCM_a409_kneeAirbagRightIssue m6 : 52|1@1+ (1,0) [0|1] "" Vector__XXX
 SG_ TRCM_a410_curtainAirbagLeftIssue m6 : 53|1@1+ (1,0) [0|1] "" Vector__XXX
 SG_ TRCM_a411_curtainAirbagRightIssu m6 : 54|1@1+ (1,0) [0|1] "" Vector__XXX
 SG_ TRCM_a412_seatbeltLoadLimiterFro m6 : 55|1@1+ (1,0) [0|1] "" Vector__XXX
 SG_ TRCM_a413_seatbeltLoadLimiterFro m6 : 56|1@1+ (1,0) [0|1] "" Vector__XXX
 SG_ TRCM_a414_seatbeltShoulderPreten m6 : 57|1@1+ (1,0) [0|1] "" Vector__XXX
 SG_ TRCM_a415_seatbeltShoulderPreten m6 : 58|1@1+ (1,0) [0|1] "" Vector__XXX
 SG_ TRCM_a416_seatbeltLapPretensione m6 : 59|1@1+ (1,0) [0|1] "" Vector__XXX
 SG_ TRCM_a417_seatbeltLapPretensione m6 : 60|1@1+ (1,0) [0|1] "" Vector__XXX
 SG_ TRCM_a418_outboardSeatAirbagLeft m6 : 61|1@1+ (1,0) [0|1] "" Vector__XXX
 SG_ TRCM_a419_outboardSeatAirbagRigh m6 : 62|1@1+ (1,0) [0|1] "" Vector__XXX
 SG_ TRCM_a420_hoodLifterLeftIssue m6 : 63|1@1+ (1,0) [0|1] "" Vector__XXX
 SG_ TRCM_a421_hoodLifterRightIssue m7 : 4|1@1+ (1,0) [0|1] "" Vector__XXX
 SG_ TRCM_a422_seatbeltShoulderPreten m7 : 5|1@1+ (1,0) [0|1] "" Vector__XXX
 SG_ TRCM_a423_seatbeltShoulderPreten m7 : 6|1@1+ (1,0) [0|1] "" Vector__XXX
 SG_ TRCM_a432_driverAirbagStage1Conf m7 : 15|1@1+ (1,0) [0|1] "" Vector__XXX
 SG_ TRCM_a433_passengerAirbagStage1C m7 : 16|1@1+ (1,0) [0|1] "" Vector__XXX
 SG_ TRCM_a434_driverAirbagStage2Conf m7 : 17|1@1+ (1,0) [0|1] "" Vector__XXX
 SG_ TRCM_a435_driverAirbagActiveVent m7 : 18|1@1+ (1,0) [0|1] "" Vector__XXX
 SG_ TRCM_a436_passengerAirbagStage2C m7 : 19|1@1+ (1,0) [0|1] "" Vector__XXX
 SG_ TRCM_a437_passengerAirbagActiveV m7 : 20|1@1+ (1,0) [0|1] "" Vector__XXX
 SG_ TRCM_a438_inboardSeatAirbagConfi m7 : 21|1@1+ (1,0) [0|1] "" Vector__XXX
 SG_ TRCM_a440_kneeAirbagLeftConfigEr m7 : 23|1@1+ (1,0) [0|1] "" Vector__XXX
 SG_ TRCM_a441_kneeAirbagRightConfigE m7 : 24|1@1+ (1,0) [0|1] "" Vector__XXX
 SG_ TRCM_a442_curtainAirbagLeftConfi m7 : 25|1@1+ (1,0) [0|1] "" Vector__XXX
 SG_ TRCM_a443_curtainAirbagRightConf m7 : 26|1@1+ (1,0) [0|1] "" Vector__XXX
 SG_ TRCM_a444_seatbeltLoadLimiterFro m7 : 27|1@1+ (1,0) [0|1] "" Vector__XXX
 SG_ TRCM_a445_seatbeltLoadLimiterFro m7 : 28|1@1+ (1,0) [0|1] "" Vector__XXX
 SG_ TRCM_a446_seatbeltShoulderPreten m7 : 29|1@1+ (1,0) [0|1] "" Vector__XXX
 SG_ TRCM_a447_seatbeltShoulderPreten m7 : 30|1@1+ (1,0) [0|1] "" Vector__XXX
 SG_ TRCM_a448_seatbeltLapPretensione m7 : 31|1@1+ (1,0) [0|1] "" Vector__XXX
 SG_ TRCM_a449_seatbeltLapPretensione m7 : 32|1@1+ (1,0) [0|1] "" Vector__XXX
 SG_ TRCM_a450_outboardSeatAirbagLeft m7 : 33|1@1+ (1,0) [0|1] "" Vector__XXX
 SG_ TRCM_a451_outboardSeatAirbagRigh m7 : 34|1@1+ (1,0) [0|1] "" Vector__XXX
 SG_ TRCM_a452_hoodLifterLeftConfigEr m7 : 35|1@1+ (1,0) [0|1] "" Vector__XXX
 SG_ TRCM_a453_hoodLifterRightConfigE m7 : 36|1@1+ (1,0) [0|1] "" Vector__XXX
 SG_ TRCM_a454_seatbeltShoulderPreten m7 : 37|1@1+ (1,0) [0|1] "" Vector__XXX
 SG_ TRCM_a455_seatbeltShoulderPreten m7 : 38|1@1+ (1,0) [0|1] "" Vector__XXX
 SG_ TRCM_a544_erCapDiagnosticsFailed m9 : 7|1@1+ (1,0) [0|1] "" Vector__XXX
 SG_ TRCM_a545_erCapBelowAutarkyThres m9 : 8|1@1+ (1,0) [0|1] "" Vector__XXX
 SG_ TRCM_a546_sensorValuesFaultedByS m9 : 9|1@1+ (1,0) [0|1] "" Vector__XXX
 SG_ TRCM_a550_AlgoWake_RCM_WAKE_FRON m9 : 13|1@1+ (1,0) [0|1] "" Vector__XXX
 SG_ TRCM_a551_AlgoWake_RCM_WAKE_REAR m9 : 14|1@1+ (1,0) [0|1] "" Vector__XXX
 SG_ TRCM_a552_AlgoWake_RCM_WAKE_LEFT m9 : 15|1@1+ (1,0) [0|1] "" Vector__XXX
 SG_ TRCM_a553_AlgoWake_RCM_WAKE_RIGH m9 : 16|1@1+ (1,0) [0|1] "" Vector__XXX
 SG_ TRCM_a554_AlgoWake_PAS_LH_PLAUSI m9 : 17|1@1+ (1,0) [0|1] "" Vector__XXX
 SG_ TRCM_a555_AlgoWake_PAS_LH_PLAUSI m9 : 18|1@1+ (1,0) [0|1] "" Vector__XXX
 SG_ TRCM_a557_AlgoWake_PAS_RH_PLAUSI m9 : 20|1@1+ (1,0) [0|1] "" Vector__XXX
 SG_ TRCM_a558_AlgoWake_PAS_RH_PLAUSI m9 : 21|1@1+ (1,0) [0|1] "" Vector__XXX
 SG_ TRCM_a560_AlgoWake_RCM_WAKE_ROLL m9 : 23|1@1+ (1,0) [0|1] "" Vector__XXX
 SG_ TRCM_a561_AlgoWake_RCM_WAKE_ROLL m9 : 24|1@1+ (1,0) [0|1] "" Vector__XXX
 SG_ TRCM_a562_AlgoWake_RCM_AWAKE_FRO m9 : 25|1@1+ (1,0) [0|1] "" Vector__XXX
 SG_ TRCM_a563_AlgoWake_RCM_AWAKE_REA m9 : 26|1@1+ (1,0) [0|1] "" Vector__XXX
 SG_ TRCM_a564_AlgoWake_RCM_AWAKE_LEF m9 : 27|1@1+ (1,0) [0|1] "" Vector__XXX
 SG_ TRCM_a565_AlgoWake_RCM_AWAKE_RIG m9 : 28|1@1+ (1,0) [0|1] "" Vector__XXX
 SG_ TRCM_a566_AlgoWake_RCM_AWAKE_ROL m9 : 29|1@1+ (1,0) [0|1] "" Vector__XXX
 SG_ TRCM_a567_AlgoWake_RCM_AWAKE_X m9 : 30|1@1+ (1,0) [0|1] "" Vector__XXX
 SG_ TRCM_a568_AlgoWake_RCM_AWAKE_Y m9 : 31|1@1+ (1,0) [0|1] "" Vector__XXX
 SG_ TRCM_a569_AlgoWake_PAS_WAKE_LEFT m9 : 32|1@1+ (1,0) [0|1] "" Vector__XXX
 SG_ TRCM_a570_AlgoWake_PAS_WAKE_RIGH m9 : 33|1@1+ (1,0) [0|1] "" Vector__XXX
 SG_ TRCM_a576_AlgoWake_IMPACT_FINISH m9 : 39|1@1+ (1,0) [0|1] "" Vector__XXX
 SG_ TRCM_a577_AlgoWake_IMPACT_FINISH m9 : 40|1@1+ (1,0) [0|1] "" Vector__XXX
 SG_ TRCM_a578_AlgoWake_IMPACT_FINISH m9 : 41|1@1+ (1,0) [0|1] "" Vector__XXX
 SG_ TRCM_a579_AlgoWake_RCM_ENABLED_X m9 : 42|1@1+ (1,0) [0|1] "" Vector__XXX
 SG_ TRCM_a580_AlgoWake_RCM_ENABLED_Y m9 : 43|1@1+ (1,0) [0|1] "" Vector__XXX
 SG_ TRCM_a581_AlgoWake_RCM_ENABLED_R m9 : 44|1@1+ (1,0) [0|1] "" Vector__XXX
 SG_ TRCM_a582_AlgoWake_RCM_AWAKE m9 : 45|1@1+ (1,0) [0|1] "" Vector__XXX
 SG_ TRCM_a588_yawRateOffsetPosLimit m9 : 51|1@1+ (1,0) [0|1] "" Vector__XXX
 SG_ TRCM_a589_yawRateOffsetNegLimit m9 : 52|1@1+ (1,0) [0|1] "" Vector__XXX
 SG_ TRCM_a590_pitchRateOffsetPosLimi m9 : 53|1@1+ (1,0) [0|1] "" Vector__XXX
 SG_ TRCM_a591_pitchRateOffsetNegLimi m9 : 54|1@1+ (1,0) [0|1] "" Vector__XXX
 SG_ TRCM_a592_rollRateOffsetPosLimit m9 : 55|1@1+ (1,0) [0|1] "" Vector__XXX
 SG_ TRCM_a593_rollRateOffsetNegLimit m9 : 56|1@1+ (1,0) [0|1] "" Vector__XXX
 SG_ TRCM_a594_longitudinalAccelOffse m9 : 57|1@1+ (1,0) [0|1] "" Vector__XXX
 SG_ TRCM_a595_longitudinalAccelOffse m9 : 58|1@1+ (1,0) [0|1] "" Vector__XXX
 SG_ TRCM_a596_lateralAccelOffsetPosL m9 : 59|1@1+ (1,0) [0|1] "" Vector__XXX
 SG_ TRCM_a597_lateralAccelOffsetNegL m9 : 60|1@1+ (1,0) [0|1] "" Vector__XXX
 SG_ TRCM_a598_verticalAccelOffsetPos m9 : 61|1@1+ (1,0) [0|1] "" Vector__XXX
 SG_ TRCM_a599_verticalAccelOffsetNeg m9 : 62|1@1+ (1,0) [0|1] "" Vector__XXX
 SG_ TRCM_a600_airbagAsicStartupFailu m9 : 63|1@1+ (1,0) [0|1] "" Vector__XXX
 SG_ TRCM_a601_loop0AsicStartupDiagno m10 : 4|1@1+ (1,0) [0|1] "" Vector__XXX
 SG_ TRCM_a602_loop1AsicStartupDiagno m10 : 5|1@1+ (1,0) [0|1] "" Vector__XXX
 SG_ TRCM_a603_loop2AsicStartupDiagno m10 : 6|1@1+ (1,0) [0|1] "" Vector__XXX
 SG_ TRCM_a604_loop3AsicStartupDiagno m10 : 7|1@1+ (1,0) [0|1] "" Vector__XXX
 SG_ TRCM_a605_loop4AsicStartupDiagno m10 : 8|1@1+ (1,0) [0|1] "" Vector__XXX
 SG_ TRCM_a606_loop5AsicStartupDiagno m10 : 9|1@1+ (1,0) [0|1] "" Vector__XXX
 SG_ TRCM_a607_loop6AsicStartupDiagno m10 : 10|1@1+ (1,0) [0|1] "" Vector__XXX
 SG_ TRCM_a608_loop7AsicStartupDiagno m10 : 11|1@1+ (1,0) [0|1] "" Vector__XXX
 SG_ TRCM_a609_loop8AsicStartupDiagno m10 : 12|1@1+ (1,0) [0|1] "" Vector__XXX
 SG_ TRCM_a610_loop9AsicStartupDiagno m10 : 13|1@1+ (1,0) [0|1] "" Vector__XXX
 SG_ TRCM_a611_loop10AsicStartupDiagn m10 : 14|1@1+ (1,0) [0|1] "" Vector__XXX
 SG_ TRCM_a612_loop11AsicStartupDiagn m10 : 15|1@1+ (1,0) [0|1] "" Vector__XXX
 SG_ TRCM_a613_loop12AsicStartupDiagn m10 : 16|1@1+ (1,0) [0|1] "" Vector__XXX
 SG_ TRCM_a614_loop13AsicStartupDiagn m10 : 17|1@1+ (1,0) [0|1] "" Vector__XXX
 SG_ TRCM_a615_loop14AsicStartupDiagn m10 : 18|1@1+ (1,0) [0|1] "" Vector__XXX
 SG_ TRCM_a616_loop15AsicStartupDiagn m10 : 19|1@1+ (1,0) [0|1] "" Vector__XXX
 SG_ TRCM_a617_loop16AsicStartupDiagn m10 : 20|1@1+ (1,0) [0|1] "" Vector__XXX
 SG_ TRCM_a618_loop17AsicStartupDiagn m10 : 21|1@1+ (1,0) [0|1] "" Vector__XXX
 SG_ TRCM_a619_loop18AsicStartupDiagn m10 : 22|1@1+ (1,0) [0|1] "" Vector__XXX
 SG_ TRCM_a620_loop19AsicStartupDiagn m10 : 23|1@1+ (1,0) [0|1] "" Vector__XXX
 SG_ TRCM_a621_loop20AsicStartupDiagn m10 : 24|1@1+ (1,0) [0|1] "" Vector__XXX
 SG_ TRCM_a622_loop21AsicStartupDiagn m10 : 25|1@1+ (1,0) [0|1] "" Vector__XXX
 SG_ TRCM_a623_loop22AsicStartupDiagn m10 : 26|1@1+ (1,0) [0|1] "" Vector__XXX
 SG_ TRCM_a624_loop23AsicStartupDiagn m10 : 27|1@1+ (1,0) [0|1] "" Vector__XXX
 SG_ TRCM_a625_loop24AsicStartupDiagn m10 : 28|1@1+ (1,0) [0|1] "" Vector__XXX
 SG_ TRCM_a626_loop25AsicStartupDiagn m10 : 29|1@1+ (1,0) [0|1] "" Vector__XXX
 SG_ TRCM_a627_loop26AsicStartupDiagn m10 : 30|1@1+ (1,0) [0|1] "" Vector__XXX
 SG_ TRCM_a628_loop27AsicStartupDiagn m10 : 31|1@1+ (1,0) [0|1] "" Vector__XXX
 SG_ TRCM_a629_loop28AsicStartupDiagn m10 : 32|1@1+ (1,0) [0|1] "" Vector__XXX
 SG_ TRCM_a630_loop29AsicStartupDiagn m10 : 33|1@1+ (1,0) [0|1] "" Vector__XXX
 SG_ TRCM_a631_loop30AsicStartupDiagn m10 : 34|1@1+ (1,0) [0|1] "" Vector__XXX
 SG_ TRCM_a632_loop31AsicStartupDiagn m10 : 35|1@1+ (1,0) [0|1] "" Vector__XXX
 SG_ TRCM_a633_glacierInitialStatusFa m10 : 36|1@1+ (1,0) [0|1] "" Vector__XXX
 SG_ TRCM_a634_glacierTraceabilityRea m10 : 37|1@1+ (1,0) [0|1] "" Vector__XXX
 SG_ TRCM_a635_glacierTraceabilityRea m10 : 38|1@1+ (1,0) [0|1] "" Vector__XXX
 SG_ TRCM_a636_glacierRegisterPattern m10 : 39|1@1+ (1,0) [0|1] "" Vector__XXX
 SG_ TRCM_a637_glacierFixedPatternSel m10 : 40|1@1+ (1,0) [0|1] "" Vector__XXX
 SG_ TRCM_a638_glacierSelfTestEFailur m10 : 41|1@1+ (1,0) [0|1] "" Vector__XXX
 SG_ TRCM_a639_glacierSelfTestFFailur m10 : 42|1@1+ (1,0) [0|1] "" Vector__XXX
 SG_ TRCM_a640_glacierAnalogSelfTestF m10 : 43|1@1+ (1,0) [0|1] "" Vector__XXX
 SG_ TRCM_a641_glacierOscillatorVerif m10 : 44|1@1+ (1,0) [0|1] "" Vector__XXX
 SG_ TRCM_a642_glacierFinalStatusFail m10 : 45|1@1+ (1,0) [0|1] "" Vector__XXX
 SG_ TRCM_a643_glacierOffsetVerificat m10 : 46|1@1+ (1,0) [0|1] "" Vector__XXX
 SG_ TRCM_a644_glacierNormalOperation m10 : 47|1@1+ (1,0) [0|1] "" Vector__XXX
 SG_ TRCM_a645_glacierDeviceReset m10 : 48|1@1+ (1,0) [0|1] "" Vector__XXX
 SG_ TRCM_a646_glacierDeviceFaulted m10 : 49|1@1+ (1,0) [0|1] "" Vector__XXX

BO_ 850 TRCM_info: 8 TRCM
 SG_ TRCM_infoIndex M : 0|8@1+ (1,0) [0|255] "" Vector__XXX
 SG_ TRCM_infoBuildType m10 : 8|8@1+ (1,0) [0|255] "" Vector__XXX
 SG_ TRCM_infoBuildConfigId m10 : 16|16@1+ (1,0) [0|65535] "" Vector__XXX
 SG_ TRCM_infoHardwareId m10 : 32|16@1+ (1,0) [0|65535] "" Vector__XXX
 SG_ TRCM_infoComponentId m10 : 48|16@1+ (1,0) [0|65535] "" Vector__XXX
 SG_ TRCM_infoPcbaId m11 : 8|8@1+ (1,0) [0|255] "" Vector__XXX
 SG_ TRCM_infoAssemblyId m11 : 16|8@1+ (1,0) [0|254] "" Vector__XXX
 SG_ TRCM_infoUsageId m11 : 24|16@1+ (1,0) [0|65535] "" Vector__XXX
 SG_ TRCM_infoSubUsageId m11 : 40|16@1+ (1,0) [0|65535] "" Vector__XXX
 SG_ TRCM_infoAppCrc m13 : 8|32@1+ (1,0) [0|4294967295] "" Vector__XXX
 SG_ TRCM_infoAppGitHash m17 : 8|56@1+ (1,0) [0|7.20575940379e+16] "" Vector__XXX
 SG_ TRCM_infoBootGitHash m18 : 8|56@1+ (1,0) [0|7.20575940379e+16] "" Vector__XXX
 SG_ TRCM_infoBootUdsProtoVersion m20 : 8|8@1+ (1,0) [0|255] "" Vector__XXX
 SG_ TRCM_infoBootCrc m20 : 24|32@1+ (1,0) [0|4294967295] "" Vector__XXX

BO_ 1021 UI_autopilotControl: 8 GTW
 SG_ UI_autopilotControlIndex M : 0|3@1+ (1,0) [0|7] "" Vector__XXX
 SG_ UI_hovEnabled m0 : 3|1@1+ (1,0) [0|1] "" Vector__XXX
 SG_ UI_donDisableAutoWiperDuration m0 : 4|3@1+ (1,0) [0|7] "" Vector__XXX
 SG_ UI_donDisableOnAutoWiperSpeed m0 : 7|4@1+ (1,0) [0|15] "" Vector__XXX
 SG_ UI_blindspotMinSpeed m0 : 11|4@1+ (1,0) [0|15] "" Vector__XXX
 SG_ UI_blindspotDistance m0 : 15|3@1+ (1,0) [0|7] "" Vector__XXX
 SG_ UI_blindspotTTC m0 : 18|3@1+ (1,0) [0|7] "" Vector__XXX
 SG_ UI_donStopEndOfRampBuffer m0 : 21|3@1+ (1,0) [0|7] "" Vector__XXX
 SG_ UI_donDisableCutin m0 : 24|1@1+ (1,0) [0|1] "" Vector__XXX
 SG_ UI_smartSetSpeedOffset m0 : 25|6@1+ (1,-30) [-30|33] "%" Vector__XXX
 SG_ UI_smartSetSpeedOffsetType m0 : 31|1@1+ (1,0) [0|1] "" Vector__XXX
 SG_ UI_autopilotMonarchBackup m0 : 32|1@1+ (1,0) [0|1] "" Vector__XXX
 SG_ UI_fsdVisualizationEnabled m0 : 37|1@1+ (1,0) [0|1] "" Vector__XXX
 SG_ UI_fsdStopsControlEnabled m0 : 38|1@1+ (1,0) [0|1] "" Vector__XXX
 SG_ UI_fsdContinueOnGreenWithCIPV m0 : 39|1@1+ (1,0) [0|1] "" Vector__XXX
 SG_ UI_smartSetSpeed m0 : 40|1@1+ (1,0) [0|1] "" Vector__XXX
 SG_ UI_automaticSetSpeedOffset m0 : 41|1@1+ (1,0) [0|1] "" Vector__XXX
 SG_ UI_apply2021_1958_ISA m0 : 42|1@1+ (1,0) [0|1] "" Vector__XXX
 SG_ UI_apply2021_646_ELKS m0 : 43|1@1+ (1,0) [0|1] "" Vector__XXX
 SG_ UI_apply2021_1341_DDAW m0 : 44|1@1+ (1,0) [0|1] "" Vector__XXX
 SG_ UI_homelinkNearby m0 : 45|1@1+ (1,0) [0|1] "" Vector__XXX
 SG_ UI_enableFullSelfDriving m0 : 46|1@1+ (1,0) [0|1] "" Vector__XXX
 SG_ UI_hasFullSelfDriving m0 : 47|1@1+ (1,0) [0|1] "" Vector__XXX
 SG_ UI_autosteerActivation m0 : 48|1@1+ (1,0) [0|1] "" Vector__XXX
 SG_ UI_fsdBetaRequest m0 : 51|1@1+ (1,0) [0|1] "" Vector__XXX
 SG_ UI_fullSelfDrivingSuspended m0 : 52|1@1+ (1,0) [0|1] "" Vector__XXX
 SG_ UI_disableOptionalLaneChanges m0 : 53|1@1+ (1,0) [0|1] "" Vector__XXX
 SG_ UI_applyR152_AEBS m0 : 59|1@1+ (1,0) [0|1] "" Vector__XXX
 SG_ UI_applyDCASBehavior m0 : 60|1@1+ (1,0) [0|1] "" Vector__XXX
 SG_ UI_applyDCASBehaviorLegacy m0 : 61|1@1+ (1,0) [0|1] "" Vector__XXX
 SG_ UI_applyADDWWarnings m0 : 62|1@1+ (1,0) [0|1] "" Vector__XXX
 SG_ UI_autopilotControlMux0Valid m0 : 63|1@1+ (1,0) [0|1] "" Vector__XXX
 SG_ UI_selectableCameraRequest m1 : 8|4@1+ (1,0) [0|14] "" Vector__XXX
 SG_ UI_overrideSleepWithSuspend m1 : 16|1@1+ (1,0) [0|1] "" Vector__XXX
 SG_ UI_driverMonitorConfirmation m1 : 17|1@1+ (1,0) [0|1] "" Vector__XXX
 SG_ UI_parkAssistUseVision m1 : 18|1@1+ (1,0) [0|1] "" Vector__XXX
 SG_ UI_applyEceR79 m1 : 19|1@1+ (1,0) [0|1] "" Vector__XXX
 SG_ UI_enableMapStops m1 : 20|1@1+ (1,0) [0|1] "" Vector__XXX
 SG_ UI_disableMain m1 : 23|1@1+ (1,0) [0|1] "" Vector__XXX
 SG_ UI_disableNarrow m1 : 24|1@1+ (1,0) [0|1] "" Vector__XXX
 SG_ UI_disableFisheye m1 : 25|1@1+ (1,0) [0|1] "" Vector__XXX
 SG_ UI_disableLeftPillar m1 : 26|1@1+ (1,0) [0|1] "" Vector__XXX
 SG_ UI_disableRightPillar m1 : 27|1@1+ (1,0) [0|1] "" Vector__XXX
 SG_ UI_disableLeftRepeater m1 : 28|1@1+ (1,0) [0|1] "" Vector__XXX
 SG_ UI_disableRightRepeater m1 : 29|1@1+ (1,0) [0|1] "" Vector__XXX
 SG_ UI_disableBackup m1 : 30|1@1+ (1,0) [0|1] "" Vector__XXX
 SG_ UI_disableRadar m1 : 31|1@1+ (1,0) [0|1] "" Vector__XXX
 SG_ UI_noStalkConfirmAlertHaptic m1 : 32|1@1+ (1,0) [0|1] "" Vector__XXX
 SG_ UI_regulatoryLKA m1 : 33|1@1+ (1,0) [0|1] "" Vector__XXX
 SG_ UI_regulatoryLaneAssistLevel m1 : 34|1@1+ (1,0) [0|1] "" Vector__XXX
 SG_ UI_ulcSnooze m1 : 36|1@1+ (1,0) [0|1] "" Vector__XXX
 SG_ UI_noStalkConfirmAlertChime m1 : 37|1@1+ (1,0) [0|1] "" Vector__XXX
 SG_ UI_factorySummonEnable m1 : 39|1@1+ (1,0) [0|1] "" Vector__XXX
 SG_ UI_apmv3Branch m1 : 40|3@1+ (1,0) [0|7] "" Vector__XXX
 SG_ UI_enableCabinCamera m1 : 43|1@1+ (1,0) [0|1] "" Vector__XXX
 SG_ UI_enableAutopilotStopWarning m1 : 44|1@1+ (1,0) [0|1] "" Vector__XXX
 SG_ UI_showLaneGraph m1 : 45|1@1+ (1,0) [0|1] "" Vector__XXX
 SG_ UI_showTrackLabels m1 : 46|1@1+ (1,0) [0|1] "" Vector__XXX
 SG_ UI_hardCoreSummon m1 : 47|1@1+ (1,0) [0|1] "" Vector__XXX
 SG_ UI_enableCabinCameraTelemetry m1 : 48|1@1+ (1,0) [0|1] "" Vector__XXX
 SG_ UI_enableVisionSpeedControl m1 : 49|1@1+ (1,0) [0|1] "" Vector__XXX
 SG_ UI_autopilotTelemetryInChina m1 : 50|1@1+ (1,0) [0|1] "" Vector__XXX
 SG_ UI_enableTeslaAutopark m1 : 51|1@1+ (1,0) [0|1] "" Vector__XXX
 SG_ UI_autoTurnSignalMode m1 : 52|1@1+ (1,0) [0|1] "" Vector__XXX
 SG_ UI_enableCautionLightControl m1 : 54|1@1+ (1,0) [0|1] "" Vector__XXX
 SG_ UI_applyEceR79SmartSummonOnly m1 : 55|1@1+ (1,0) [0|1] "" Vector__XXX
 SG_ UI_autopilotMonarchEnabled m1 : 56|1@1+ (1,0) [0|1] "" Vector__XXX
 SG_ UI_autopilotEphemerisEnabled m1 : 57|1@1+ (1,0) [0|1] "" Vector__XXX
 SG_ UI_enableCabinAudioRecording m1 : 59|1@1+ (1,0) [0|1] "" Vector__XXX
 SG_ UI_autopilotControlMux1Valid m1 : 63|1@1+ (1,0) [0|1] "" Vector__XXX
 SG_ UI_enableApproachingEmergencyVeh m2 : 5|1@1+ (1,0) [0|1] "" Vector__XXX
 SG_ UI_enableStartFsdFromParkBrakeCo m2 : 6|1@1+ (1,0) [0|1] "" Vector__XXX
 SG_ UI_enableStartFsdFromPark m2 : 7|1@1+ (1,0) [0|1] "" Vector__XXX
 SG_ UI_fsdMaxSpeedOffsetPercentage m2 : 8|6@1+ (1,0) [0|63] "%" Vector__XXX
 SG_ UI_calibrationReadyInFactory m2 : 15|1@1+ (1,0) [0|1] "" Vector__XXX
 SG_ UI_coldStartMonarchInFactory m2 : 16|1@1+ (1,0) [0|1] "" Vector__XXX
 SG_ UI_navMinutesToArrival m2 : 17|10@1+ (1,0) [0|1023] "minutes" Vector__XXX
 SG_ UI_fsdQuizRequired m2 : 27|1@1+ (1,0) [0|1] "" Vector__XXX
 SG_ UI_fsdQuizPassed m2 : 28|1@1+ (1,0) [0|1] "" Vector__XXX
 SG_ UI_fsdAllowedInLocalizedRegion m2 : 29|1@1+ (1,0) [0|1] "" Vector__XXX
 SG_ UI_autopilotDrivingProfile m2 : 60|3@1+ (1,0) [0|7] "" Vector__XXX
 SG_ UI_autopilotControlMux2Valid m2 : 63|1@1+ (1,0) [0|1] "" Vector__XXX

BO_ 659 UI_chassisControl: 8 GTW
 SG_ UI_steeringTuneRequest : 0|2@1+ (1,0) [0|3] "" Vector__XXX
 SG_ UI_tractionControlMode : 2|3@1+ (1,0) [0|7] "" Vector__XXX
 SG_ UI_parkBrakeRequest : 5|2@1+ (1,0) [0|2] "" Vector__XXX
 SG_ UI_narrowGarages : 7|1@1+ (1,0) [0|1] "" Vector__XXX
 SG_ UI_winchModeRequest : 8|2@1+ (1,0) [0|3] "" Vector__XXX
 SG_ UI_zeroSpeedConfirmed : 10|2@1+ (1,0) [0|2] "" Vector__XXX
 SG_ UI_trailerMode : 12|1@1+ (1,0) [0|1] "" Vector__XXX
 SG_ UI_distanceUnits : 13|1@1+ (1,0) [0|1] "" Vector__XXX
 SG_ UI_dasDebugEnable : 14|1@1+ (1,0) [0|1] "" Vector__XXX
 SG_ UI_accOvertakeEnable : 16|2@1+ (1,0) [0|2] "" Vector__XXX
 SG_ UI_aebEnable : 18|2@1+ (1,0) [0|2] "" Vector__XXX
 SG_ UI_aesEnable : 20|2@1+ (1,0) [0|2] "" Vector__XXX
 SG_ UI_ahlbEnable : 22|2@1+ (1,0) [0|2] "" Vector__XXX
 SG_ UI_autoLaneChangeEnable : 24|2@1+ (1,0) [0|2] "" Vector__XXX
 SG_ UI_winchProxUserOverride : 26|1@1+ (1,0) [0|1] "" Vector__XXX
 SG_ UI_rebootAutopilot : 27|1@1+ (1,0) [0|1] "" Vector__XXX
 SG_ UI_autoParkRequest : 28|4@1+ (1,0) [0|14] "" Vector__XXX
 SG_ UI_bsdEnable : 32|2@1+ (1,0) [0|2] "" Vector__XXX
 SG_ UI_fcwEnable : 34|2@1+ (1,0) [0|2] "" Vector__XXX
 SG_ UI_fcwSensitivity : 36|2@1+ (1,0) [0|2] "" Vector__XXX
 SG_ UI_latControlEnable : 38|2@1+ (1,0) [0|2] "" Vector__XXX
 SG_ UI_ldwEnable : 40|2@1+ (1,0) [0|2] "" Vector__XXX
 SG_ UI_pedalSafetyEnable : 42|2@1+ (1,0) [0|2] "" Vector__XXX
 SG_ UI_pedalMap_epas : 44|2@1+ (1,0) [0|3] "" Vector__XXX
 SG_ UI_redLightStopSignEnable : 46|2@1+ (1,0) [0|2] "" Vector__XXX
 SG_ UI_selfParkTune : 48|4@1+ (1,0) [0|14] "" Vector__XXX
 SG_ UI_chassisControlCounter : 52|4@1+ (1,0) [0|15] "" Vector__XXX
 SG_ UI_chassisControlChecksum : 56|8@1+ (1,0) [0|255] "" Vector__XXX

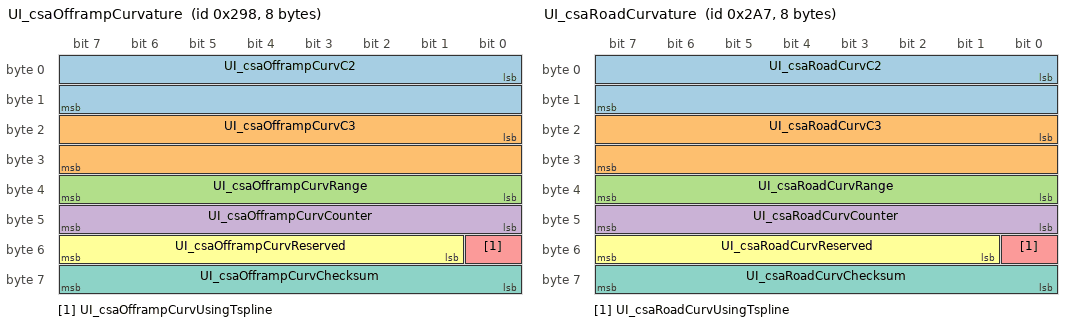
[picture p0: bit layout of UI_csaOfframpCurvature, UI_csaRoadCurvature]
BO_ 664 UI_csaOfframpCurvature: 8 GTW
 SG_ UI_csaOfframpCurvC2 : 0|16@1- (1.0e-06,0) [-0.032768|0.032767] "1/m" Vector__XXX
 SG_ UI_csaOfframpCurvC3 : 16|16@1- (4.0e-09,0) [-0.000131072|0.000131068] "1/m2" Vector__XXX
 SG_ UI_csaOfframpCurvRange : 32|8@1+ (2,0) [0|510] "m" Vector__XXX
 SG_ UI_csaOfframpCurvCounter : 40|8@1+ (1,0) [0|255] "" Vector__XXX
 SG_ UI_csaOfframpCurvUsingTspline : 48|1@1+ (1,0) [0|1] "" Vector__XXX
 SG_ UI_csaOfframpCurvReserved : 49|7@1+ (1,0) [0|127] "" Vector__XXX
 SG_ UI_csaOfframpCurvChecksum : 56|8@1+ (1,0) [0|255] "" Vector__XXX

BO_ 679 UI_csaRoadCurvature: 8 GTW
 SG_ UI_csaRoadCurvC2 : 0|16@1- (1.0e-06,0) [-0.032768|0.032767] "1/m" Vector__XXX
 SG_ UI_csaRoadCurvC3 : 16|16@1- (4.0e-09,0) [-0.000131072|0.000131068] "1/m2" Vector__XXX
 SG_ UI_csaRoadCurvRange : 32|8@1+ (2,0) [0|510] "m" Vector__XXX
 SG_ UI_csaRoadCurvCounter : 40|8@1+ (1,0) [0|255] "" Vector__XXX
 SG_ UI_csaRoadCurvUsingTspline : 48|1@1+ (1,0) [0|1] "" Vector__XXX
 SG_ UI_csaRoadCurvReserved : 49|7@1+ (1,0) [0|127] "" Vector__XXX
 SG_ UI_csaRoadCurvChecksum : 56|8@1+ (1,0) [0|255] "" Vector__XXX

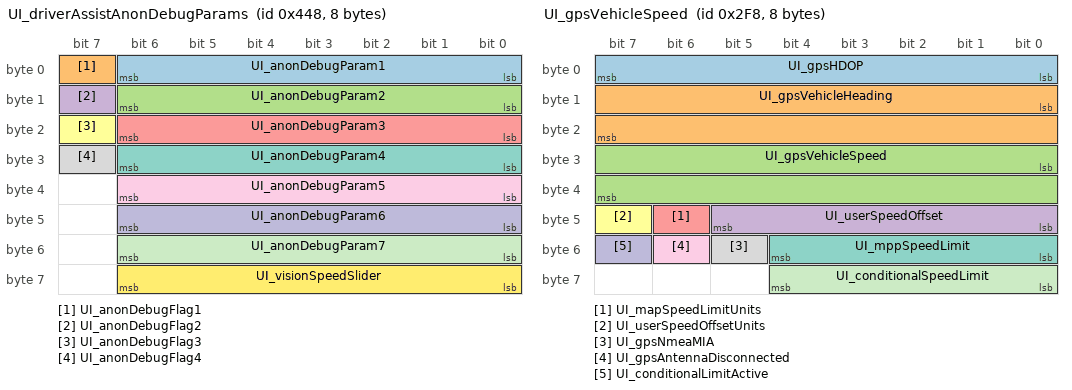
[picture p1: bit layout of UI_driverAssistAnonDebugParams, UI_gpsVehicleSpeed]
BO_ 1096 UI_driverAssistAnonDebugParams: 8 GTW
 SG_ UI_anonDebugParam1 : 0|7@1+ (1,0) [0|127] "" Vector__XXX
 SG_ UI_anonDebugFlag1 : 7|1@1+ (1,0) [0|1] "" Vector__XXX
 SG_ UI_anonDebugParam2 : 8|7@1+ (1,0) [0|127] "" Vector__XXX
 SG_ UI_anonDebugFlag2 : 15|1@1+ (1,0) [0|1] "" Vector__XXX
 SG_ UI_anonDebugParam3 : 16|7@1+ (1,0) [0|127] "" Vector__XXX
 SG_ UI_anonDebugFlag3 : 23|1@1+ (1,0) [0|1] "" Vector__XXX
 SG_ UI_anonDebugParam4 : 24|7@1+ (1,0) [0|127] "" Vector__XXX
 SG_ UI_anonDebugFlag4 : 31|1@1+ (1,0) [0|1] "" Vector__XXX
 SG_ UI_anonDebugParam5 : 32|7@1+ (1,0) [0|127] "" Vector__XXX
 SG_ UI_anonDebugParam6 : 40|7@1+ (1,0) [0|127] "" Vector__XXX
 SG_ UI_anonDebugParam7 : 48|7@1+ (1,0) [0|127] "" Vector__XXX
 SG_ UI_visionSpeedSlider : 56|7@1+ (1,0) [0|127] "" Vector__XXX

BO_ 1016 UI_driverAssistControl: 8 GTW
 SG_ UI_autopilotControlRequest : 0|1@1+ (1,0) [0|1] "" Vector__XXX
 SG_ UI_ulcStalkConfirm : 1|1@1+ (1,0) [0|1] "" Vector__XXX
 SG_ UI_summonHeartbeat : 2|2@1+ (1,0) [0|3] "" Vector__XXX
 SG_ UI_curvSpeedAdaptDisable : 4|1@1+ (1,0) [0|1] "" Vector__XXX
 SG_ UI_dasDeveloper : 5|1@1+ (1,0) [0|1] "" Vector__XXX
 SG_ UI_enableVinAssociation : 6|1@1+ (1,0) [0|1] "" Vector__XXX
 SG_ UI_lssLkaEnabled : 7|1@1+ (1,0) [0|1] "" Vector__XXX
 SG_ UI_lssLdwEnabled : 8|1@1+ (1,0) [0|1] "" Vector__XXX
 SG_ UI_coastToCoast : 9|1@1+ (1,0) [0|1] "" Vector__XXX
 SG_ UI_autoSummonEnable : 10|1@1+ (1,0) [0|1] "" Vector__XXX
 SG_ UI_exceptionListEnable : 11|1@1+ (1,0) [0|1] "" Vector__XXX
 SG_ UI_roadCheckDisable : 12|1@1+ (1,0) [0|1] "" Vector__XXX
 SG_ UI_driveOnMapsEnable : 13|1@1+ (1,0) [0|1] "" Vector__XXX
 SG_ UI_handsOnRequirementDisable : 14|1@1+ (1,0) [0|1] "" Vector__XXX
 SG_ UI_ulcOffHighway : 15|1@1+ (1,0) [0|1] "" Vector__XXX
 SG_ UI_fuseLanesDisable : 16|1@1+ (1,0) [0|1] "" Vector__XXX
 SG_ UI_fuseHPPDisable : 17|1@1+ (1,0) [0|1] "" Vector__XXX
 SG_ UI_fuseVehiclesDisable : 18|1@1+ (1,0) [0|1] "" Vector__XXX
 SG_ UI_enableClipParkedTelemetry : 19|1@1+ (1,0) [0|1] "" Vector__XXX
 SG_ UI_visionSpeedType : 20|2@1+ (1,0) [0|3] "" Vector__XXX
 SG_ UI_curvatureDatabaseOnly : 22|1@1+ (1,0) [0|1] "" Vector__XXX
 SG_ UI_lssElkEnabled : 23|1@1+ (1,0) [0|1] "" Vector__XXX
 SG_ UI_summonExitType : 24|2@1+ (1,0) [0|2] "" Vector__XXX
 SG_ UI_summonEntryType : 26|2@1+ (1,0) [0|2] "" Vector__XXX
 SG_ UI_selfParkRequest : 28|4@1+ (1,0) [0|14] "" Vector__XXX
 SG_ UI_summonReverseDist : 32|6@1+ (1,0) [0|62] "" Vector__XXX
 SG_ UI_undertakeAssistEnable : 38|1@1+ (1,0) [0|1] "" Vector__XXX
 SG_ UI_adaptiveSetSpeedEnable : 39|1@1+ (1,0) [0|1] "" Vector__XXX
 SG_ UI_drivingSide : 40|2@1+ (1,0) [0|3] "" Vector__XXX
 SG_ UI_enableClipTelemetry : 42|1@1+ (1,0) [0|1] "" Vector__XXX
 SG_ UI_enableTripTelemetry : 43|1@1+ (1,0) [0|1] "" Vector__XXX
 SG_ UI_enableRoadSegmentTelemetry : 44|1@1+ (1,0) [0|1] "" Vector__XXX
 SG_ UI_accFollowDistanceSetting : 45|3@1+ (1,0) [0|6] "" Vector__XXX
 SG_ UI_hasDriveOnNav : 48|1@1+ (1,0) [0|1] "" Vector__XXX
 SG_ UI_followNavRouteEnable : 49|1@1+ (1,0) [0|1] "" Vector__XXX
 SG_ UI_ulcSpeedConfig : 50|2@1+ (1,0) [0|3] "" Vector__XXX
 SG_ UI_ulcBlindSpotConfig : 52|2@1+ (1,0) [0|3] "" Vector__XXX
 SG_ UI_suppressExitPassingLane : 54|1@1+ (1,0) [0|1] "" Vector__XXX
 SG_ UI_enableClipStartStopTelemetry : 55|1@1+ (1,0) [0|1] "" Vector__XXX
 SG_ UI_alcOffHighwayEnable : 56|1@1+ (1,0) [0|1] "" Vector__XXX
 SG_ UI_validationLoop : 57|1@1+ (1,0) [0|1] "" Vector__XXX
 SG_ UI_smartSummonType : 58|2@1+ (1,0) [0|3] "" Vector__XXX
 SG_ UI_enableVisionOnlyStops : 60|1@1+ (1,0) [0|1] "" Vector__XXX
 SG_ UI_source3D : 61|2@1+ (1,0) [0|3] "" Vector__XXX
 SG_ UI_isaSpeedingChimeMuted : 63|1@1+ (1,0) [0|1] "" Vector__XXX

BO_ 568 UI_driverAssistMapData: 8 GTW
 SG_ UI_mapSpeedLimitDependency : 0|3@1+ (1,0) [0|6] "" Vector__XXX
 SG_ UI_roadClass : 3|3@1+ (1,0) [1|7] "" Vector__XXX
 SG_ UI_inSuperchargerGeofence : 6|1@1+ (1,0) [0|1] "" Vector__XXX
 SG_ UI_mapSpeedUnits : 7|1@1+ (1,0) [0|1] "" Vector__XXX
 SG_ UI_mapSpeedLimit : 8|5@1+ (1,0) [0|30] "" Vector__XXX
 SG_ UI_mapSpeedLimitType : 13|3@1+ (1,0) [0|6] "" Vector__XXX
 SG_ UI_countryCode : 16|10@1+ (1,0) [0|1022] "" Vector__XXX
 SG_ UI_streetCount : 26|2@1+ (1,0) [0|3] "" Vector__XXX
 SG_ UI_gpsRoadMatch : 28|1@1+ (1,0) [0|1] "" Vector__XXX
 SG_ UI_navRouteActive : 29|1@1+ (1,0) [0|1] "" Vector__XXX
 SG_ UI_parallelAutoparkEnabled : 30|1@1+ (1,0) [0|1] "" Vector__XXX
 SG_ UI_perpendicularAutoparkEnabled : 31|1@1+ (1,0) [0|1] "" Vector__XXX
 SG_ UI_nextBranchDist : 32|5@1+ (10,0) [0|300] "m" Vector__XXX
 SG_ UI_controlledAccess : 37|1@1+ (1,0) [0|1] "" Vector__XXX
 SG_ UI_nextBranchLeftOffRamp : 38|1@1+ (1,0) [0|1] "" Vector__XXX
 SG_ UI_nextBranchRightOffRamp : 39|1@1+ (1,0) [0|1] "" Vector__XXX
 SG_ UI_rejectLeftLane : 40|1@1+ (1,0) [0|1] "" Vector__XXX
 SG_ UI_rejectRightLane : 41|1@1+ (1,0) [0|1] "" Vector__XXX
 SG_ UI_rejectHPP : 42|1@1+ (1,0) [0|1] "" Vector__XXX
 SG_ UI_rejectNav : 43|1@1+ (1,0) [0|1] "" Vector__XXX
 SG_ UI_rejectLeftFreeSpace : 44|1@1+ (1,0) [0|1] "" Vector__XXX
 SG_ UI_rejectRightFreeSpace : 45|1@1+ (1,0) [0|1] "" Vector__XXX
 SG_ UI_rejectAutosteer : 46|1@1+ (1,0) [0|1] "" Vector__XXX
 SG_ UI_rejectHandsOn : 47|1@1+ (1,0) [0|1] "" Vector__XXX
 SG_ UI_acceptBottsDots : 48|1@1+ (1,0) [0|1] "" Vector__XXX
 SG_ UI_autosteerRestricted : 49|1@1+ (1,0) [0|1] "" Vector__XXX
 SG_ UI_pmmEnabled : 50|1@1+ (1,0) [0|1] "" Vector__XXX
 SG_ UI_scaEnabled : 51|1@1+ (1,0) [0|1] "" Vector__XXX
 SG_ UI_mapDataCounter : 52|4@1+ (1,0) [0|15] "" Vector__XXX
 SG_ UI_mapDataChecksum : 56|8@1+ (1,0) [0|255] "" Vector__XXX

BO_ 536 UI_driverAssistRoadSign: 8 GTW
 SG_ UI_roadSign M : 0|8@1+ (1,0) [0|254] "" Vector__XXX
 SG_ UI_splineLocConfidence : 40|7@1+ (1,0) [1|127] "1" Vector__XXX
 SG_ UI_splineID : 48|4@1+ (1,0) [0|15] "" Vector__XXX
 SG_ UI_roadSignCounter : 52|4@1+ (1,0) [0|15] "" Vector__XXX
 SG_ UI_roadSignChecksum : 56|8@1+ (1,0) [0|255] "" Vector__XXX
 SG_ UI_dummyData m0 : 8|1@1+ (1,0) [0|1] "" Vector__XXX
 SG_ UI_stopSignStopLineDist m1 : 8|10@1+ (0.25,-8) [-8|247.5] "m" Vector__XXX
 SG_ UI_stopSignStopLineConf m1 : 18|7@1+ (1,0) [1|127] "1" Vector__XXX
 SG_ UI_trafficLightStopLineDist m2 : 8|10@1+ (0.25,-8) [-8|247.5] "m" Vector__XXX
 SG_ UI_trafficLightStopLineConf m2 : 18|7@1+ (1,0) [1|127] "1" Vector__XXX
 SG_ UI_baseMapSpeedLimitMPS m3 : 8|8@1+ (0.25,0) [0|63.5] "m/s" Vector__XXX
 SG_ UI_bottomQrtlFleetSpeedMPS m3 : 16|8@1+ (0.25,0) [0|63.5] "m/s" Vector__XXX
 SG_ UI_topQrtlFleetSpeedMPS m3 : 24|8@1+ (0.25,0) [0|63.5] "m/s" Vector__XXX
 SG_ UI_meanFleetSplineSpeedMPS m4 : 8|8@1+ (0.25,0) [0|63.5] "m/s" Vector__XXX
 SG_ UI_medianFleetSpeedMPS m4 : 16|8@1+ (0.25,0) [0|63.5] "m/s" Vector__XXX
 SG_ UI_meanFleetSplineAccelMPS2 m4 : 24|8@1+ (0.05,-6.35) [-6.35|6.35] "m/s^2" Vector__XXX
 SG_ UI_rampType m4 : 32|3@1+ (1,0) [1|7] "" Vector__XXX
 SG_ UI_valhallaRamp m4 : 35|2@1+ (1,0) [1|3] "" Vector__XXX
 SG_ UI_overrideACMFleetSpeed m4 : 38|1@1+ (1,0) [0|1] "" Vector__XXX
 SG_ UI_currSplineIdFull m5 : 8|32@1+ (1,0) [1|4294967295] "1" Vector__XXX

BO_ 1971 UI_dynamicTriggersCampaignFired: 8 GTW
 SG_ UI_campaignFired : 0|64@1+ (1,0) [0|1.84467440737e+19] "" Vector__XXX

BO_ 760 UI_gpsVehicleSpeed: 8 GTW
 SG_ UI_gpsHDOP : 0|8@1+ (0.1,0) [0|25.5] "1" Vector__XXX
 SG_ UI_gpsVehicleHeading : 8|16@1+ (0.0078125,0) [0|511.9921875] "deg" Vector__XXX
 SG_ UI_gpsVehicleSpeed : 24|16@1+ (0.00390625,0) [0|255.99609375] "km/hr" Vector__XXX
 SG_ UI_userSpeedOffset : 40|6@1+ (1,-30) [-30|33] "kph/mph" Vector__XXX
 SG_ UI_mapSpeedLimitUnits : 46|1@1+ (1,0) [0|1] "" Vector__XXX
 SG_ UI_userSpeedOffsetUnits : 47|1@1+ (1,0) [0|1] "" Vector__XXX
 SG_ UI_mppSpeedLimit : 48|5@1+ (5,0) [0|155] "kph/mph" Vector__XXX
 SG_ UI_gpsNmeaMIA : 53|1@1+ (1,0) [0|1] "" Vector__XXX
 SG_ UI_gpsAntennaDisconnected : 54|1@1+ (1,0) [0|1] "" Vector__XXX
 SG_ UI_conditionalLimitActive : 55|1@1+ (1,0) [0|1] "" Vector__XXX
 SG_ UI_conditionalSpeedLimit : 56|5@1+ (5,0) [0|150] "kph/mph" Vector__XXX

BO_ 985 UI_locationOffset: 8 GTW
 SG_ UI_latitudeOffset : 0|28@1- (1.0e-06,0) [-134.217728|134.217727] "deg" Vector__XXX
 SG_ UI_longitudeOffset : 28|29@1- (1.0e-06,0) [-268.435456|268.435455] "deg" Vector__XXX

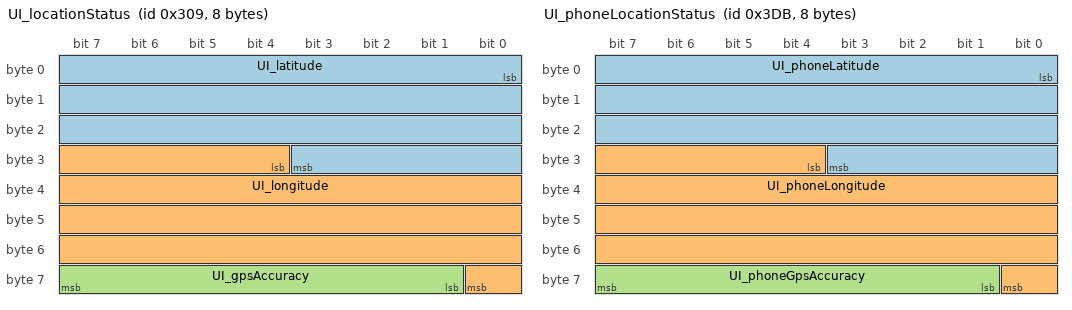
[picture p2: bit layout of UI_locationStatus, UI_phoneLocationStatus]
BO_ 777 UI_locationStatus: 8 GTW
 SG_ UI_latitude : 0|28@1- (1.0e-06,0) [-134.217728|134.217727] "deg" Vector__XXX
 SG_ UI_longitude : 28|29@1- (1.0e-06,0) [-268.435456|268.435455] "deg" Vector__XXX
 SG_ UI_gpsAccuracy : 57|7@1+ (0.2,0) [0|25.2] "m" Vector__XXX

BO_ 1011 UI_odo: 3 GTW
 SG_ UI_odometer : 0|24@1+ (0.1,0) [0|1677721.4] "km" Vector__XXX

BO_ 987 UI_phoneLocationStatus: 8 GTW
 SG_ UI_phoneLatitude : 0|28@1- (1.0e-06,0) [-134.217728|134.217727] "deg" Vector__XXX
 SG_ UI_phoneLongitude : 28|29@1- (1.0e-06,0) [-268.435456|268.435455] "deg" Vector__XXX
 SG_ UI_phoneGpsAccuracy : 57|7@1+ (0.5,0) [0|63] "m" Vector__XXX

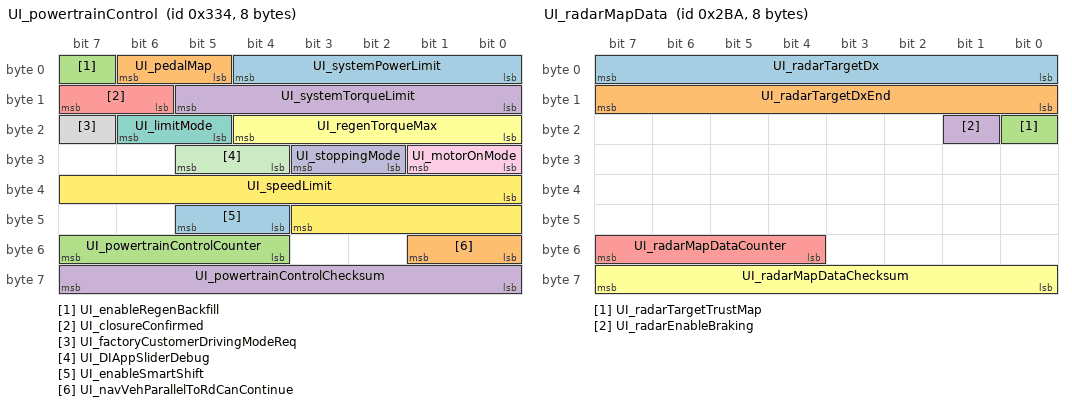
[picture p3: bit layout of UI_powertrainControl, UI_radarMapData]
BO_ 820 UI_powertrainControl: 8 GTW
 SG_ UI_systemPowerLimit : 0|5@1+ (20,20) [20|620] "kW" Vector__XXX
 SG_ UI_pedalMap : 5|2@1+ (1,0) [0|3] "" Vector__XXX
 SG_ UI_enableRegenBackfill : 7|1@1+ (1,0) [0|1] "" Vector__XXX
 SG_ UI_systemTorqueLimit : 8|6@1+ (150,1000) [1000|10300] "Nm" Vector__XXX
 SG_ UI_closureConfirmed : 14|2@1+ (1,0) [0|3] "" Vector__XXX
 SG_ UI_regenTorqueMax : 16|5@1+ (5,0) [0|100] "%" Vector__XXX
 SG_ UI_limitMode : 21|2@1+ (1,0) [0|3] "" Vector__XXX
 SG_ UI_factoryCustomerDrivingModeReq : 23|1@1+ (1,0) [0|1] "" Vector__XXX
 SG_ UI_motorOnMode : 24|2@1+ (1,0) [0|3] "" Vector__XXX
 SG_ UI_stoppingMode : 26|2@1+ (1,0) [0|3] "" Vector__XXX
 SG_ UI_DIAppSliderDebug : 28|2@1+ (1,0) [0|3] "" Vector__XXX
 SG_ UI_speedLimit : 32|12@1+ (0.1,0) [0|335] "kph" Vector__XXX
 SG_ UI_enableSmartShift : 44|2@1+ (1,0) [0|3] "" Vector__XXX
 SG_ UI_navVehParallelToRdCanContinue : 48|2@1+ (1,0) [1|3] "" Vector__XXX
 SG_ UI_powertrainControlCounter : 52|4@1+ (1,0) [0|15] "" Vector__XXX
 SG_ UI_powertrainControlChecksum : 56|8@1+ (1,0) [0|255] "" Vector__XXX

BO_ 698 UI_radarMapData: 8 GTW
 SG_ UI_radarTargetDx : 0|8@1+ (1,-95) [-95|160] "m" Vector__XXX
 SG_ UI_radarTargetDxEnd : 8|8@1+ (1,0) [0|255] "m" Vector__XXX
 SG_ UI_radarTargetTrustMap : 16|1@1+ (1,0) [0|1] "" Vector__XXX
 SG_ UI_radarEnableBraking : 17|1@1+ (1,0) [0|1] "" Vector__XXX
 SG_ UI_radarMapDataCounter : 52|4@1+ (1,0) [0|15] "" Vector__XXX
 SG_ UI_radarMapDataChecksum : 56|8@1+ (1,0) [0|255] "" Vector__XXX

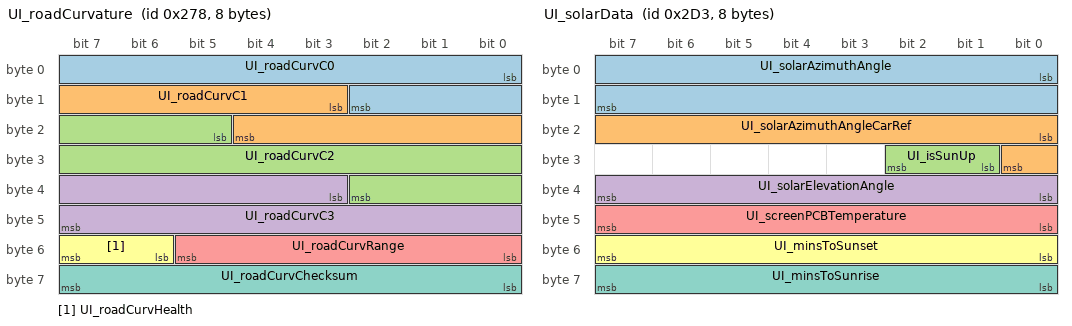
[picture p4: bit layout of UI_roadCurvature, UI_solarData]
BO_ 632 UI_roadCurvature: 8 GTW
 SG_ UI_roadCurvC0 : 0|11@1- (0.02,0) [-20.48|20.46] "m" Vector__XXX
 SG_ UI_roadCurvC1 : 11|10@1- (0.00075,0) [-0.384|0.38325] "1" Vector__XXX
 SG_ UI_roadCurvC2 : 21|14@1- (7.5e-06,0) [-0.06144|0.0614325] "1/m" Vector__XXX
 SG_ UI_roadCurvC3 : 35|13@1- (3.0e-08,0) [-0.00012288|0.00012285] "1/m2" Vector__XXX
 SG_ UI_roadCurvRange : 48|6@1+ (4,0) [0|252] "m" Vector__XXX
 SG_ UI_roadCurvHealth : 54|2@1+ (1,0) [0|3] "" Vector__XXX
 SG_ UI_roadCurvChecksum : 56|8@1+ (1,0) [0|255] "" Vector__XXX

BO_ 723 UI_solarData: 8 GTW
 SG_ UI_solarAzimuthAngle : 0|16@1- (1,0) [-32768|32767] "degrees" Vector__XXX
 SG_ UI_solarAzimuthAngleCarRef : 16|9@1- (1,0) [-256|254] "degrees" Vector__XXX
 SG_ UI_isSunUp : 25|2@1+ (1,0) [0|2] "" Vector__XXX
 SG_ UI_solarElevationAngle : 32|8@1- (1,0) [-128|126] "degrees" Vector__XXX
 SG_ UI_screenPCBTemperature : 40|8@1- (0.5,40) [-20|100] "degC" Vector__XXX
 SG_ UI_minsToSunset : 48|8@1+ (10,0) [0|2550] "min" Vector__XXX
 SG_ UI_minsToSunrise : 56|8@1+ (10,0) [0|2550] "min" Vector__XXX

BO_ 851 UI_status: 8 GTW
 SG_ UI_touchActive : 0|1@1+ (1,0) [0|1] "" Vector__XXX
 SG_ UI_audioActive : 1|1@1+ (1,0) [0|1] "" Vector__XXX
 SG_ UI_bluetoothActive : 2|1@1+ (1,0) [0|1] "" Vector__XXX
 SG_ UI_cellActive : 3|1@1+ (1,0) [0|1] "" Vector__XXX
 SG_ UI_displayReady : 4|1@1+ (1,0) [0|1] "" Vector__XXX
 SG_ UI_displayOn : 5|1@1+ (1,0) [0|1] "" Vector__XXX
 SG_ UI_wifiActive : 6|1@1+ (1,0) [0|1] "" Vector__XXX
 SG_ UI_wifiConnected : 7|1@1+ (1,0) [0|1] "" Vector__XXX
 SG_ UI_systemActive : 8|1@1+ (1,0) [0|1] "" Vector__XXX
 SG_ UI_readyForDrive : 9|1@1+ (1,0) [0|1] "" Vector__XXX
 SG_ UI_cellConnected : 10|1@1+ (1,0) [0|1] "" Vector__XXX
 SG_ UI_vpnActive : 11|1@1+ (1,0) [0|1] "" Vector__XXX
 SG_ UI_autopilotTrial : 12|2@1+ (1,0) [0|3] "" Vector__XXX
 SG_ UI_factoryReset : 14|2@1+ (1,0) [1|3] "" Vector__XXX
 SG_ UI_gpsActive : 16|1@1+ (1,0) [0|1] "" Vector__XXX
 SG_ UI_screenshotActive : 17|1@1+ (1,0) [0|1] "" Vector__XXX
 SG_ UI_radioActive : 18|1@1+ (1,0) [0|1] "" Vector__XXX
 SG_ UI_cellNetworkTechnology : 19|4@1+ (1,0) [0|14] "" Vector__XXX
 SG_ UI_cellReceiverPower : 24|8@1+ (1,-128) [-128|127] "dB" Vector__XXX
 SG_ UI_falseTouchCounter : 32|8@1+ (1,0) [0|255] "1" Vector__XXX
 SG_ UI_developmentCar : 40|1@1+ (1,0) [0|1] "" Vector__XXX
 SG_ UI_cameraActive : 41|1@1+ (1,0) [0|1] "" Vector__XXX
 SG_ UI_cellSignalBars : 42|3@1+ (1,0) [0|6] "" Vector__XXX
 SG_ UI_trailerModeTelltale : 45|2@1+ (1,0) [0|3] "" Vector__XXX
 SG_ UI_pcbTemperature : 48|8@1- (1,40) [-20|100] "degC" Vector__XXX
 SG_ UI_cpuTemperature : 56|8@1- (1,40) [-20|100] "degC" Vector__XXX

BO_ 991 UI_status2: 8 GTW
 SG_ UI_mobileAppStepCount : 0|16@1+ (1,0) [0|65535] "" Vector__XXX
 SG_ UI_userRequestSnapshot : 16|1@1+ (1,0) [0|1] "" Vector__XXX
 SG_ UI_touchDetected : 17|1@1+ (1,0) [0|1] "" Vector__XXX
 SG_ UI_validDeviceForEUSummon : 18|1@1+ (1,0) [0|1] "" Vector__XXX
 SG_ UI_locatedAtHome : 19|1@1+ (1,0) [0|1] "" Vector__XXX
 SG_ UI_locatedAtWork : 20|1@1+ (1,0) [0|1] "" Vector__XXX
 SG_ UI_locatedAtFavorite : 21|1@1+ (1,0) [0|1] "" Vector__XXX
 SG_ UI_displayInDarkMode : 22|1@1+ (1,0) [0|1] "" Vector__XXX
 SG_ UI_userActivity : 23|1@1+ (1,0) [0|1] "" Vector__XXX
 SG_ UI_activeTouchPoints : 24|8@1+ (1,0) [0|255] "1" Vector__XXX
 SG_ UI_linkState : 32|2@1+ (1,0) [0|3] "" Vector__XXX
 SG_ UI_sentryModeState : 34|3@1+ (1,0) [0|7] "" Vector__XXX
 SG_ UI_autopilotSentryRequest : 37|1@1+ (1,0) [0|1] "" Vector__XXX
 SG_ UI_mobileAppConnected : 38|1@1+ (1,0) [0|1] "" Vector__XXX
 SG_ UI_phoneLeftInCabin : 39|1@1+ (1,0) [0|1] "" Vector__XXX
 SG_ UI_autoshiftDRState : 40|3@1+ (1,0) [0|7] "" Vector__XXX
 SG_ UI_wifiBtModuleType : 43|3@1+ (1,0) [0|7] "" Vector__XXX
 SG_ UI_sohHealthStatus : 46|2@1+ (1,0) [0|3] "" Vector__XXX
 SG_ UI_selfParkState : 48|8@1+ (1,0) [0|254] "" Vector__XXX
 SG_ UI_summonDeviceIndex : 56|2@1+ (1,0) [0|3] "" Vector__XXX
 SG_ UI_fullScreenMode : 58|1@1+ (1,0) [0|1] "" Vector__XXX
 SG_ UI_sentryModeCameraDetection : 59|1@1+ (1,0) [0|1] "" Vector__XXX
 SG_ UI_wakeOnIPActive : 60|1@1+ (1,0) [0|1] "" Vector__XXX
 SG_ UI_sapActive : 61|1@1+ (1,0) [0|1] "" Vector__XXX
 SG_ UI_sapClients : 62|1@1+ (1,0) [0|1] "" Vector__XXX
 SG_ UI_connectivityStandbyActive : 63|1@1+ (1,0) [0|1] "" Vector__XXX

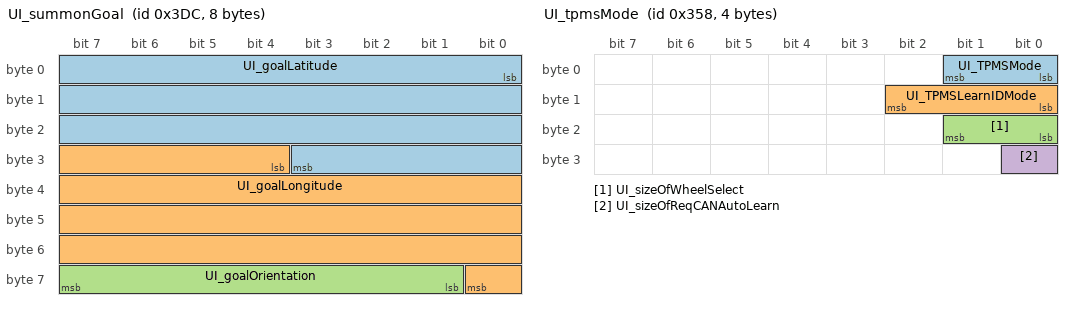
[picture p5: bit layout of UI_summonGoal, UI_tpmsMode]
BO_ 988 UI_summonGoal: 8 GTW
 SG_ UI_goalLatitude : 0|28@1- (1.0e-06,0) [-134.217728|134.217727] "deg" Vector__XXX
 SG_ UI_goalLongitude : 28|29@1- (1.0e-06,0) [-268.435456|268.435455] "deg" Vector__XXX
 SG_ UI_goalOrientation : 57|7@1+ (2.8125,0) [0|357.1875] "deg" Vector__XXX

BO_ 1064 UI_telemetryControl: 8 GTW
 SG_ UI_TCR_enable : 0|1@1+ (1,0) [0|1] "" Vector__XXX
 SG_ UI_TCR_moveStateStanding : 1|1@1+ (1,0) [0|1] "" Vector__XXX
 SG_ UI_TCR_moveStateStopped : 2|1@1+ (1,0) [0|1] "" Vector__XXX
 SG_ UI_TCR_moveStateMoving : 3|1@1+ (1,0) [0|1] "" Vector__XXX
 SG_ UI_TCR_moveStateIndeterm : 4|1@1+ (1,0) [0|1] "" Vector__XXX
 SG_ UI_TCR_classConstElem : 5|1@1+ (1,0) [0|1] "" Vector__XXX
 SG_ UI_TCR_classMovingPed : 6|1@1+ (1,0) [0|1] "" Vector__XXX
 SG_ UI_TCR_classMovingTwoWheel : 7|1@1+ (1,0) [0|1] "" Vector__XXX
 SG_ UI_TCR_classMovingFourWheel : 8|1@1+ (1,0) [0|1] "" Vector__XXX
 SG_ UI_TCR_classUnknown : 9|1@1+ (1,0) [0|1] "" Vector__XXX
 SG_ UI_TCR_downSampleFactor : 10|4@1+ (1,0) [0|15] "" Vector__XXX
 SG_ UI_TCR_wExist : 24|5@1+ (1,0) [0|31] "" Vector__XXX
 SG_ UI_TCR_vehSpeed : 32|8@1+ (1,0) [0|255] "" Vector__XXX
 SG_ UI_TCR_minRCS : 40|8@1+ (0.25,-14) [-14|49.75] "dB" Vector__XXX
 SG_ UI_TCR_maxDy : 48|5@1+ (0.5,0) [0|15.5] "m" Vector__XXX
 SG_ UI_TCR_maxObjects : 56|5@1+ (1,0) [0|31] "" Vector__XXX
 SG_ UI_TCR_maxRoadClass : 61|3@1+ (1,0) [0|7] "" Vector__XXX

BO_ 856 UI_tpmsMode: 4 GTW
 SG_ UI_TPMSMode : 0|2@1+ (1,0) [0|3] "" Vector__XXX
 SG_ UI_TPMSLearnIDMode : 8|3@1+ (1,0) [0|7] "" Vector__XXX
 SG_ UI_sizeOfWheelSelect : 16|2@1+ (1,0) [0|3] "" Vector__XXX
 SG_ UI_sizeOfReqCANAutoLearn : 24|1@1+ (1,0) [0|1] "" Vector__XXX

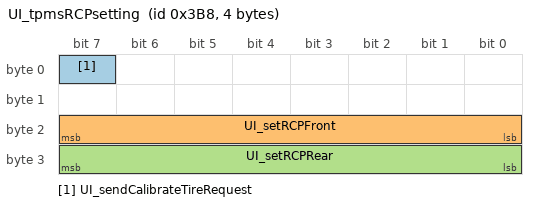
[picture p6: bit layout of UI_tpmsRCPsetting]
BO_ 952 UI_tpmsRCPsetting: 4 GTW
 SG_ UI_sendCalibrateTireRequest : 7|1@1+ (1,0) [0|1] "" Vector__XXX
 SG_ UI_setRCPFront : 16|8@1+ (0.025,0) [0|6.375] "bar" Vector__XXX
 SG_ UI_setRCPRear : 24|8@1+ (0.025,0) [0|6.375] "bar" Vector__XXX

BO_TX_BU_ 882 : TRCM;
BO_TX_BU_ 850 : TRCM;
BO_TX_BU_ 1021 : GTW;
BO_TX_BU_ 659 : GTW;
BO_TX_BU_ 664 : GTW;
BO_TX_BU_ 679 : GTW;
BO_TX_BU_ 1096 : GTW;
BO_TX_BU_ 1016 : GTW;
BO_TX_BU_ 568 : GTW;
BO_TX_BU_ 536 : GTW;
BO_TX_BU_ 1971 : GTW;
BO_TX_BU_ 760 : GTW;
BO_TX_BU_ 985 : GTW;
BO_TX_BU_ 777 : GTW;
BO_TX_BU_ 1011 : GTW;
BO_TX_BU_ 987 : GTW;
BO_TX_BU_ 820 : GTW;
BO_TX_BU_ 698 : GTW;
BO_TX_BU_ 632 : GTW;
BO_TX_BU_ 723 : GTW;
BO_TX_BU_ 851 : GTW;
BO_TX_BU_ 991 : GTW;
BO_TX_BU_ 988 : GTW;
BO_TX_BU_ 1064 : GTW;
BO_TX_BU_ 856 : GTW;
BO_TX_BU_ 952 : GTW;
CM_ BO_ 882 "TRCM ECU message: alert matrix";
CM_ SG_ 882 TRCM_matrixIndex "TRCM ECU: matrix index";
CM_ SG_ 882 TRCM_a001_airbagsDisabled "TRCM ECU: a001 airbags disabled";
CM_ SG_ 882 TRCM_a002_systemDisabled "TRCM ECU: a002 system disabled";
CM_ SG_ 882 TRCM_a003_SWAssertion "TRCM ECU: a003 SW assertion";
CM_ SG_ 882 TRCM_a004_internalFailure "TRCM ECU: a004 internal failure";
CM_ SG_ 882 TRCM_a005_CANTXError "TRCM ECU: a005 CANTX error";
CM_ SG_ 882 TRCM_a006_CANTX_cyclicError "TRCM ECU: a006 CANTX cyclic error";
CM_ SG_ 882 TRCM_a007_chassisChecksumError "TRCM ECU: a007 chassis checksum error";
CM_ SG_ 882 TRCM_a008_chassisCounterError "TRCM ECU: a008 chassis counter error";
CM_ SG_ 882 TRCM_a009_partyChecksumError "TRCM ECU: a009 party checksum error";
CM_ SG_ 882 TRCM_a010_partyCounterError "TRCM ECU: a010 party counter error";
CM_ SG_ 882 TRCM_a011_edrDataLocked "TRCM ECU: a011 edr data locked";
CM_ SG_ 882 TRCM_a012_asm5TemperatureOutside "TRCM ECU: a012 asm5 temperature outside signal range";
CM_ SG_ 882 TRCM_a013_AlertManagerFault "TRCM ECU: a013 alert manager fault";
CM_ SG_ 882 TRCM_a014_asm3TemperatureOutside "TRCM ECU: a014 asm3 temperature outside signal range";
CM_ SG_ 882 TRCM_a015_NVMMError "TRCM ECU: a015 NVMM error";
CM_ SG_ 882 TRCM_a016_NVMMRecordError "TRCM ECU: a016 NVMM record error";
CM_ SG_ 882 TRCM_a017_asm5TemperatureOutside "TRCM ECU: a017 asm5 temperature outside operating range";
CM_ SG_ 882 TRCM_a018_asm3TemperatureOutside "TRCM ECU: a018 asm3 temperature outside operating range";
CM_ SG_ 882 TRCM_a019_Task500usError "TRCM ECU: a019 task500us error";
CM_ SG_ 882 TRCM_a020_asm3ComStatusError "TRCM ECU: a020 asm3 com status error";
CM_ SG_ 882 TRCM_a021_TaskSchedulerError "TRCM ECU: a021 task scheduler error";
CM_ SG_ 882 TRCM_a022_TaskInitError "TRCM ECU: a022 task init error";
CM_ SG_ 882 TRCM_a023_asm3ArsStatusXError "TRCM ECU: a023 asm3 ars status x error";
CM_ SG_ 882 TRCM_a024_asm3AccStatusError "TRCM ECU: a024 asm3 acc status error";
CM_ SG_ 882 TRCM_a025_CHCANBusFaults "TRCM ECU: a025 CHCAN bus faults";
CM_ SG_ 882 TRCM_a026_airbagAsicDiagnosticFa "TRCM ECU: a026 airbag asic diagnostic fault";
CM_ SG_ 882 TRCM_a027_airbagAsicDeploymentDi "TRCM ECU: a027 airbag asic deployment diagnostic fault";
CM_ SG_ 882 TRCM_a028_chassisLengthError "TRCM ECU: a028 chassis length error";
CM_ SG_ 882 TRCM_a030_ECULogUploadRequest "TRCM ECU: a030 ECU log upload request";
CM_ SG_ 882 TRCM_a031_UDSActive "TRCM ECU: a031 UDS active";
CM_ SG_ 882 TRCM_a032_ScrollCreated "TRCM ECU: a032 scroll created";
CM_ SG_ 882 TRCM_a033_HercLogCreated "TRCM ECU: a033 herc log created";
CM_ SG_ 882 TRCM_a034_apClipTrigger "TRCM ECU: a034 ap clip trigger";
CM_ SG_ 882 TRCM_a035_hvDisconnectCommanded "TRCM ECU: a035 hv disconnect commanded";
CM_ SG_ 882 TRCM_a036_crashDetected "TRCM ECU: a036 crash detected";
CM_ SG_ 882 TRCM_a037_nearDeploy "TRCM ECU: a037 near deploy";
CM_ SG_ 882 TRCM_a038_ens1Degraded "TRCM ECU: a038 ens1 degraded";
CM_ SG_ 882 TRCM_a039_ens2Degraded "TRCM ECU: a039 ens2 degraded";
CM_ SG_ 882 TRCM_a040_task500usOverrunDebug "TRCM ECU: a040 task500us overrun debug";
CM_ SG_ 882 TRCM_a041_HighCPULoad "TRCM ECU: a041 high CPU load";
CM_ SG_ 882 TRCM_a042_HighStackUsage "TRCM ECU: a042 high stack usage";
CM_ SG_ 882 TRCM_a043_Task1msError "TRCM ECU: a043 task1ms error";
CM_ SG_ 882 TRCM_a044_Task10msError "TRCM ECU: a044 task10ms error";
CM_ SG_ 882 TRCM_a045_Task100msError "TRCM ECU: a045 task100ms error";
CM_ SG_ 882 TRCM_a046_Task1000msError "TRCM ECU: a046 task1000ms error";
CM_ SG_ 882 TRCM_a047_vinNotLearned "TRCM ECU: a047 vin not learned";
CM_ SG_ 882 TRCM_a048_vinMismatch "TRCM ECU: a048 vin mismatch";
CM_ SG_ 882 TRCM_a049_nvmDebugInfo "TRCM ECU: a049 nvm debug info";
CM_ SG_ 882 TRCM_a050_partyLengthError "TRCM ECU: a050 party length error";
CM_ SG_ 882 TRCM_a051_systemSelfTestTimeout "TRCM ECU: a051 system self test timeout";
CM_ SG_ 882 TRCM_a057_HVP_MIA "TRCM ECU: a057 HVP MIA";
CM_ SG_ 882 TRCM_a058_inputRHighSyncDebug "TRCM ECU: a058 input r high sync debug";
CM_ SG_ 882 TRCM_a059_inputResistanceHigh "TRCM ECU: a059 input resistance high";
CM_ SG_ 882 TRCM_a060_engineeringBuild "TRCM ECU: a060 engineering build";
CM_ SG_ 882 TRCM_a061_XCPConnected "TRCM ECU: a061 XCP connected";
CM_ SG_ 882 TRCM_a062_XCPWasConnected "TRCM ECU: a062 XCP was connected";
CM_ SG_ 882 TRCM_a063_SwitchFault "TRCM ECU: a063 switch fault";
CM_ SG_ 882 TRCM_a064_busSleepReqTimeout "TRCM ECU: a064 bus sleep req timeout";
CM_ SG_ 882 TRCM_a065_vSafingFetUnderVoltage "TRCM ECU: a065 v safing fet under voltage";
CM_ SG_ 882 TRCM_a066_leftPowerIssue "TRCM ECU: a066 left power issue";
CM_ SG_ 882 TRCM_a067_rightPowerIssue "TRCM ECU: a067 right power issue";
CM_ SG_ 882 TRCM_a068_vBusCUnderVoltage "TRCM ECU: a068 v bus c under voltage";
CM_ SG_ 882 TRCM_a069_swAppBoot "TRCM ECU: a069 sw app boot";
CM_ SG_ 882 TRCM_a070_asm3StatusError "TRCM ECU: a070 asm3 status error";
CM_ SG_ 882 TRCM_a071_asm3DeviceFaulted "TRCM ECU: a071 asm3 device faulted";
CM_ SG_ 882 TRCM_a072_ais2120StatusError "TRCM ECU: a072 ais2120 status error";
CM_ SG_ 882 TRCM_a073_ais2120DeviceFaulted "TRCM ECU: a073 ais2120 device faulted";
CM_ SG_ 882 TRCM_a074_ais2120SelfTestXPositi "TRCM ECU: a074 ais2120 self test x positive failed";
CM_ SG_ 882 TRCM_a075_ais2120SelfTestXNegati "TRCM ECU: a075 ais2120 self test x negative failed";
CM_ SG_ 882 TRCM_a076_ais2120SelfTestYPositi "TRCM ECU: a076 ais2120 self test y positive failed";
CM_ SG_ 882 TRCM_a077_ais2120SelfTestYNegati "TRCM ECU: a077 ais2120 self test y negative failed";
CM_ SG_ 882 TRCM_a078_imuSensorSignalMonitor "TRCM ECU: a078 imu sensor signal monitor";
CM_ SG_ 882 TRCM_a081_powerLossDetected "TRCM ECU: a081 power loss detected";
CM_ SG_ 882 TRCM_a082_VCRIGHT_IPC_MIA "TRCM ECU: a082 VCRIGHT IPC MIA";
CM_ SG_ 882 TRCM_a083_VCLEFT_IPC_MIA "TRCM ECU: a083 VCLEFT IPC MIA";
CM_ SG_ 882 TRCM_a084_TPMS_MIA "TRCM ECU: a084 TPMS MIA";
CM_ SG_ 882 TRCM_a085_CCCM_MIA "TRCM ECU: a085 CCCM MIA";
CM_ SG_ 882 TRCM_a086_VCBATT_MIA "TRCM ECU: a086 VCBATT MIA";
CM_ SG_ 882 TRCM_a087_DIREL_MIA "TRCM ECU: a087 DIREL MIA";
CM_ SG_ 882 TRCM_a088_DIRER_MIA "TRCM ECU: a088 DIRER MIA";
CM_ SG_ 882 TRCM_a089_IBST_MIA "TRCM ECU: a089 IBST MIA";
CM_ SG_ 882 TRCM_a090_APS_MIA "TRCM ECU: a090 APS MIA";
CM_ SG_ 882 TRCM_a091_CMPD_MIA "TRCM ECU: a091 CMPD MIA";
CM_ SG_ 882 TRCM_a092_VCSEATD_MIA "TRCM ECU: a092 VCSEATD MIA";
CM_ SG_ 882 TRCM_a093_VCSEATP_MIA "TRCM ECU: a093 VCSEATP MIA";
CM_ SG_ 882 TRCM_a094_EPAS3P_MIA "TRCM ECU: a094 EPAS3 p MIA";
CM_ SG_ 882 TRCM_a095_CHG_MIA "TRCM ECU: a095 CHG MIA";
CM_ SG_ 882 TRCM_a096_OCS1P_MIA "TRCM ECU: a096 OCS1 p MIA";
CM_ SG_ 882 TRCM_a097_CMP_MIA "TRCM ECU: a097 CMP MIA";
CM_ SG_ 882 TRCM_a098_DIR_MIA "TRCM ECU: a098 DIR MIA";
CM_ SG_ 882 TRCM_a099_PARK_MIA "TRCM ECU: a099 PARK MIA";
CM_ SG_ 882 TRCM_a100_CANbus_MIA "TRCM ECU: a100 CA nbus MIA";
CM_ SG_ 882 TRCM_a101_PM_MIA "TRCM ECU: a101 PM MIA";
CM_ SG_ 882 TRCM_a102_PTC_MIA "TRCM ECU: a102 PTC MIA";
CM_ SG_ 882 TRCM_a103_CP_MIA "TRCM ECU: a103 CP MIA";
CM_ SG_ 882 TRCM_a104_DAS_MIA "TRCM ECU: a104 DAS MIA";
CM_ SG_ 882 TRCM_a105_TAS_MIA "TRCM ECU: a105 TAS MIA";
CM_ SG_ 882 TRCM_a106_PCS_MIA "TRCM ECU: a106 PCS MIA";
CM_ SG_ 882 TRCM_a107_BMS_MIA "TRCM ECU: a107 BMS MIA";
CM_ SG_ 882 TRCM_a108_DIF_MIA "TRCM ECU: a108 DIF MIA";
CM_ SG_ 882 TRCM_a109_RCM_MIA "TRCM ECU: a109 RCM MIA";
CM_ SG_ 882 TRCM_a110_GTW_MIA "TRCM ECU: a110 GTW MIA";
CM_ SG_ 882 TRCM_a111_EPBR_MIA "TRCM ECU: a111 EPBR MIA";
CM_ SG_ 882 TRCM_a112_EPBL_MIA "TRCM ECU: a112 EPBL MIA";
CM_ SG_ 882 TRCM_a113_UI_MIA "TRCM ECU: a113 UI MIA";
CM_ SG_ 882 TRCM_a114_ESP_MIA "TRCM ECU: a114 ESP MIA";
CM_ SG_ 882 TRCM_a115_VCSEC_MIA "TRCM ECU: a115 VCSEC MIA";
CM_ SG_ 882 TRCM_a116_VCRIGHT_MIA "TRCM ECU: a116 VCRIGHT MIA";
CM_ SG_ 882 TRCM_a117_VCLEFT_MIA "TRCM ECU: a117 VCLEFT MIA";
CM_ SG_ 882 TRCM_a118_VCFRONT_MIA "TRCM ECU: a118 VCFRONT MIA";
CM_ SG_ 882 TRCM_a119_SCCM_MIA "TRCM ECU: a119 SCCM MIA";
CM_ SG_ 882 TRCM_a120_DI_DRIVE_MIA "TRCM ECU: a120 DI DRIVE MIA";
CM_ SG_ 882 TRCM_a121_buckleStatusFrontLeftS "TRCM ECU: a121 buckle status front left signal not okay";
CM_ SG_ 882 TRCM_a122_buckleStatusFrontRight "TRCM ECU: a122 buckle status front right signal not okay";
CM_ SG_ 882 TRCM_a123_buckleStatusRearLeftSi "TRCM ECU: a123 buckle status rear left signal not okay";
CM_ SG_ 882 TRCM_a124_buckleStatusRearRightS "TRCM ECU: a124 buckle status rear right signal not okay";
CM_ SG_ 882 TRCM_a125_occupantClassification "TRCM ECU: a125 occupant classification signal not okay";
CM_ SG_ 882 TRCM_a126_seatTrackPositionLeftS "TRCM ECU: a126 seat track position left signal not okay";
CM_ SG_ 882 TRCM_a127_seatTrackPositionRight "TRCM ECU: a127 seat track position right signal not okay";
CM_ SG_ 882 TRCM_a135_asm5StatusError "TRCM ECU: a135 asm5 status error";
CM_ SG_ 882 TRCM_a136_asm5DeviceFaulted "TRCM ECU: a136 asm5 device faulted";
CM_ SG_ 882 TRCM_a137_ext1AsicSnoopTestFaile "TRCM ECU: a137 ext1 asic snoop test failed";
CM_ SG_ 882 TRCM_a138_ext2AsicSnoopTestFaile "TRCM ECU: a138 ext2 asic snoop test failed";
CM_ SG_ 882 TRCM_a145_frontCenterAccelReport "TRCM ECU: a145 front center accel reported error";
CM_ SG_ 882 TRCM_a146_frontCenterAccelGenera "TRCM ECU: a146 front center accel general issue";
CM_ SG_ 882 TRCM_a147_frontCenterAccelElectr "TRCM ECU: a147 front center accel electrical issue";
CM_ SG_ 882 TRCM_a148_frontCenterAccelConfig "TRCM ECU: a148 front center accel config error";
CM_ SG_ 882 TRCM_a149_frontCenterAccelSignal "TRCM ECU: a149 front center accel signal monitor";
CM_ SG_ 882 TRCM_a150_frontLeftAccelReported "TRCM ECU: a150 front left accel reported error";
CM_ SG_ 882 TRCM_a151_frontLeftAccelGeneralI "TRCM ECU: a151 front left accel general issue";
CM_ SG_ 882 TRCM_a152_frontLeftAccelElectric "TRCM ECU: a152 front left accel electrical issue";
CM_ SG_ 882 TRCM_a153_frontLeftAccelConfigEr "TRCM ECU: a153 front left accel config error";
CM_ SG_ 882 TRCM_a154_frontLeftAccelSignalMo "TRCM ECU: a154 front left accel signal monitor";
CM_ SG_ 882 TRCM_a155_frontLeftDoorPressureR "TRCM ECU: a155 front left door pressure reported error";
CM_ SG_ 882 TRCM_a156_frontLeftDoorPressureG "TRCM ECU: a156 front left door pressure general issue";
CM_ SG_ 882 TRCM_a157_frontLeftDoorPressureE "TRCM ECU: a157 front left door pressure electrical issue";
CM_ SG_ 882 TRCM_a158_frontLeftDoorPressureC "TRCM ECU: a158 front left door pressure config error";
CM_ SG_ 882 TRCM_a159_frontLeftDoorPressureS "TRCM ECU: a159 front left door pressure signal monitor";
CM_ SG_ 882 TRCM_a160_frontRightAccelReporte "TRCM ECU: a160 front right accel reported error";
CM_ SG_ 882 TRCM_a161_frontRightAccelGeneral "TRCM ECU: a161 front right accel general issue";
CM_ SG_ 882 TRCM_a162_frontRightAccelElectri "TRCM ECU: a162 front right accel electrical issue";
CM_ SG_ 882 TRCM_a163_frontRightAccelConfigE "TRCM ECU: a163 front right accel config error";
CM_ SG_ 882 TRCM_a164_frontRightAccelSignalM "TRCM ECU: a164 front right accel signal monitor";
CM_ SG_ 882 TRCM_a165_frontRightDoorPressure "TRCM ECU: a165 front right door pressure reported error";
CM_ SG_ 882 TRCM_a166_frontRightDoorPressure "TRCM ECU: a166 front right door pressure general issue";
CM_ SG_ 882 TRCM_a167_frontRightDoorPressure "TRCM ECU: a167 front right door pressure electrical issue";
CM_ SG_ 882 TRCM_a168_frontRightDoorPressure "TRCM ECU: a168 front right door pressure config error";
CM_ SG_ 882 TRCM_a169_frontRightDoorPressure "TRCM ECU: a169 front right door pressure signal monitor";
CM_ SG_ 882 TRCM_a170_leftBPillarAccelReport "TRCM ECU: a170 left b pillar accel reported error";
CM_ SG_ 882 TRCM_a171_leftBPillarAccelGenera "TRCM ECU: a171 left b pillar accel general issue";
CM_ SG_ 882 TRCM_a172_leftBPillarAccelElectr "TRCM ECU: a172 left b pillar accel electrical issue";
CM_ SG_ 882 TRCM_a173_leftBPillarAccelConfig "TRCM ECU: a173 left b pillar accel config error";
CM_ SG_ 882 TRCM_a174_leftBPillarAccelSignal "TRCM ECU: a174 left b pillar accel signal monitor";
CM_ SG_ 882 TRCM_a175_leftCPillarAccelReport "TRCM ECU: a175 left c pillar accel reported error";
CM_ SG_ 882 TRCM_a176_leftCPillarAccelGenera "TRCM ECU: a176 left c pillar accel general issue";
CM_ SG_ 882 TRCM_a177_leftCPillarAccelElectr "TRCM ECU: a177 left c pillar accel electrical issue";
CM_ SG_ 882 TRCM_a178_leftCPillarAccelConfig "TRCM ECU: a178 left c pillar accel config error";
CM_ SG_ 882 TRCM_a179_leftCPillarAccelSignal "TRCM ECU: a179 left c pillar accel signal monitor";
CM_ SG_ 882 TRCM_a190_rearLeftDoorPressureRe "TRCM ECU: a190 rear left door pressure reported error";
CM_ SG_ 882 TRCM_a191_rearLeftDoorPressureGe "TRCM ECU: a191 rear left door pressure general issue";
CM_ SG_ 882 TRCM_a192_rearLeftDoorPressureEl "TRCM ECU: a192 rear left door pressure electrical issue";
CM_ SG_ 882 TRCM_a193_rearLeftDoorPressureCo "TRCM ECU: a193 rear left door pressure config error";
CM_ SG_ 882 TRCM_a194_rearLeftDoorPressureSi "TRCM ECU: a194 rear left door pressure signal monitor";
CM_ SG_ 882 TRCM_a195_rearRightDoorPressureR "TRCM ECU: a195 rear right door pressure reported error";
CM_ SG_ 882 TRCM_a196_rearRightDoorPressureG "TRCM ECU: a196 rear right door pressure general issue";
CM_ SG_ 882 TRCM_a197_rearRightDoorPressureE "TRCM ECU: a197 rear right door pressure electrical issue";
CM_ SG_ 882 TRCM_a198_rearRightDoorPressureC "TRCM ECU: a198 rear right door pressure config error";
CM_ SG_ 882 TRCM_a199_rearRightDoorPressureS "TRCM ECU: a199 rear right door pressure signal monitor";
CM_ SG_ 882 TRCM_a200_rightBPillarAccelRepor "TRCM ECU: a200 right b pillar accel reported error";
CM_ SG_ 882 TRCM_a201_rightBPillarAccelGener "TRCM ECU: a201 right b pillar accel general issue";
CM_ SG_ 882 TRCM_a202_rightBPillarAccelElect "TRCM ECU: a202 right b pillar accel electrical issue";
CM_ SG_ 882 TRCM_a203_rightBPillarAccelConfi "TRCM ECU: a203 right b pillar accel config error";
CM_ SG_ 882 TRCM_a204_rightBPillarAccelSigna "TRCM ECU: a204 right b pillar accel signal monitor";
CM_ SG_ 882 TRCM_a205_rightCPillarAccelRepor "TRCM ECU: a205 right c pillar accel reported error";
CM_ SG_ 882 TRCM_a206_rightCPillarAccelGener "TRCM ECU: a206 right c pillar accel general issue";
CM_ SG_ 882 TRCM_a207_rightCPillarAccelElect "TRCM ECU: a207 right c pillar accel electrical issue";
CM_ SG_ 882 TRCM_a208_rightCPillarAccelConfi "TRCM ECU: a208 right c pillar accel config error";
CM_ SG_ 882 TRCM_a209_rightCPillarAccelSigna "TRCM ECU: a209 right c pillar accel signal monitor";
CM_ SG_ 882 TRCM_a272_asm5ComStatusError "TRCM ECU: a272 asm5 com status error";
CM_ SG_ 882 TRCM_a273_asm5ArsStatusXError "TRCM ECU: a273 asm5 ars status x error";
CM_ SG_ 882 TRCM_a274_asm5ArsStatusZError "TRCM ECU: a274 asm5 ars status z error";
CM_ SG_ 882 TRCM_a275_asm5AccStatusError "TRCM ECU: a275 asm5 acc status error";
CM_ SG_ 882 TRCM_a276_watchdogStatus "TRCM ECU: a276 watchdog status";
CM_ SG_ 882 TRCM_a278_safingEngine0Armed "TRCM ECU: a278 safing engine0 armed";
CM_ SG_ 882 TRCM_a279_safingEngine1Armed "TRCM ECU: a279 safing engine1 armed";
CM_ SG_ 882 TRCM_a280_safingEngine2Armed "TRCM ECU: a280 safing engine2 armed";
CM_ SG_ 882 TRCM_a281_safingEngine3Armed "TRCM ECU: a281 safing engine3 armed";
CM_ SG_ 882 TRCM_a282_safingEngine4Armed "TRCM ECU: a282 safing engine4 armed";
CM_ SG_ 882 TRCM_a283_safingEngine5Armed "TRCM ECU: a283 safing engine5 armed";
CM_ SG_ 882 TRCM_a284_safingEngine6Armed "TRCM ECU: a284 safing engine6 armed";
CM_ SG_ 882 TRCM_a285_safingEngine7Armed "TRCM ECU: a285 safing engine7 armed";
CM_ SG_ 882 TRCM_a286_safingEngine8Armed "TRCM ECU: a286 safing engine8 armed";
CM_ SG_ 882 TRCM_a287_safingEngine9Armed "TRCM ECU: a287 safing engine9 armed";
CM_ SG_ 882 TRCM_a288_safingEngine10Armed "TRCM ECU: a288 safing engine10 armed";
CM_ SG_ 882 TRCM_a289_safingEngine11Armed "TRCM ECU: a289 safing engine11 armed";
CM_ SG_ 882 TRCM_a290_safingEngine12Armed "TRCM ECU: a290 safing engine12 armed";
CM_ SG_ 882 TRCM_a291_safingEngine13Armed "TRCM ECU: a291 safing engine13 armed";
CM_ SG_ 882 TRCM_a292_safingEngine14Armed "TRCM ECU: a292 safing engine14 armed";
CM_ SG_ 882 TRCM_a293_safingEngine15Armed "TRCM ECU: a293 safing engine15 armed";
CM_ SG_ 882 TRCM_a294_safingEngine16Armed "TRCM ECU: a294 safing engine16 armed";
CM_ SG_ 882 TRCM_a295_safingEngine17Armed "TRCM ECU: a295 safing engine17 armed";
CM_ SG_ 882 TRCM_a296_safingEngine18Armed "TRCM ECU: a296 safing engine18 armed";
CM_ SG_ 882 TRCM_a297_safingEngine19Armed "TRCM ECU: a297 safing engine19 armed";
CM_ SG_ 882 TRCM_a298_safingEngine20Armed "TRCM ECU: a298 safing engine20 armed";
CM_ SG_ 882 TRCM_a299_safingEngine21Armed "TRCM ECU: a299 safing engine21 armed";
CM_ SG_ 882 TRCM_a300_driverAirbagStage1Supp "TRCM ECU: a300 driver airbag stage1 suppressed";
CM_ SG_ 882 TRCM_a301_passengerAirbagStage1S "TRCM ECU: a301 passenger airbag stage1 suppressed";
CM_ SG_ 882 TRCM_a302_driverAirbagStage2Supp "TRCM ECU: a302 driver airbag stage2 suppressed";
CM_ SG_ 882 TRCM_a303_driverAirbagActiveVent "TRCM ECU: a303 driver airbag active vent suppressed";
CM_ SG_ 882 TRCM_a304_passengerAirbagStage2S "TRCM ECU: a304 passenger airbag stage2 suppressed";
CM_ SG_ 882 TRCM_a305_passengerAirbagActiveV "TRCM ECU: a305 passenger airbag active vent suppressed";
CM_ SG_ 882 TRCM_a306_inboardSeatAirbagSuppr "TRCM ECU: a306 inboard seat airbag suppressed";
CM_ SG_ 882 TRCM_a308_kneeAirbagLeftSuppress "TRCM ECU: a308 knee airbag left suppressed";
CM_ SG_ 882 TRCM_a309_kneeAirbagRightSuppres "TRCM ECU: a309 knee airbag right suppressed";
CM_ SG_ 882 TRCM_a310_curtainAirbagLeftSuppr "TRCM ECU: a310 curtain airbag left suppressed";
CM_ SG_ 882 TRCM_a311_curtainAirbagRightSupp "TRCM ECU: a311 curtain airbag right suppressed";
CM_ SG_ 882 TRCM_a312_seatbeltLoadLimiterFro "TRCM ECU: a312 seatbelt load limiter front left suppressed";
CM_ SG_ 882 TRCM_a313_seatbeltLoadLimiterFro "TRCM ECU: a313 seatbelt load limiter front right suppressed";
CM_ SG_ 882 TRCM_a314_seatbeltShoulderPreten "TRCM ECU: a314 seatbelt shoulder pretensioner front left suppressed";
CM_ SG_ 882 TRCM_a315_seatbeltShoulderPreten "TRCM ECU: a315 seatbelt shoulder pretensioner front right suppressed";
CM_ SG_ 882 TRCM_a316_seatbeltLapPretensione "TRCM ECU: a316 seatbelt lap pretensioner front left suppressed";
CM_ SG_ 882 TRCM_a317_seatbeltLapPretensione "TRCM ECU: a317 seatbelt lap pretensioner front right suppressed";
CM_ SG_ 882 TRCM_a318_outboardSeatAirbagLeft "TRCM ECU: a318 outboard seat airbag left suppressed";
CM_ SG_ 882 TRCM_a319_outboardSeatAirbagRigh "TRCM ECU: a319 outboard seat airbag right suppressed";
CM_ SG_ 882 TRCM_a320_hoodLifterLeftSuppress "TRCM ECU: a320 hood lifter left suppressed";
CM_ SG_ 882 TRCM_a321_hoodLifterRightSuppres "TRCM ECU: a321 hood lifter right suppressed";
CM_ SG_ 882 TRCM_a322_seatbeltShoulderPreten "TRCM ECU: a322 seatbelt shoulder pretensioner rear left suppressed";
CM_ SG_ 882 TRCM_a323_seatbeltShoulderPreten "TRCM ECU: a323 seatbelt shoulder pretensioner rear right suppressed";
CM_ SG_ 882 TRCM_a332_driverAirbagStage1Depl "TRCM ECU: a332 driver airbag stage1 deployed";
CM_ SG_ 882 TRCM_a333_passengerAirbagStage1D "TRCM ECU: a333 passenger airbag stage1 deployed";
CM_ SG_ 882 TRCM_a334_driverAirbagStage2Depl "TRCM ECU: a334 driver airbag stage2 deployed";
CM_ SG_ 882 TRCM_a335_driverAirbagActiveVent "TRCM ECU: a335 driver airbag active vent deployed";
CM_ SG_ 882 TRCM_a336_passengerAirbagStage2D "TRCM ECU: a336 passenger airbag stage2 deployed";
CM_ SG_ 882 TRCM_a337_passengerAirbagActiveV "TRCM ECU: a337 passenger airbag active vent deployed";
CM_ SG_ 882 TRCM_a338_inboardSeatAirbagDeplo "TRCM ECU: a338 inboard seat airbag deployed";
CM_ SG_ 882 TRCM_a340_kneeAirbagLeftDeployed "TRCM ECU: a340 knee airbag left deployed";
CM_ SG_ 882 TRCM_a341_kneeAirbagRightDeploye "TRCM ECU: a341 knee airbag right deployed";
CM_ SG_ 882 TRCM_a342_curtainAirbagLeftDeplo "TRCM ECU: a342 curtain airbag left deployed";
CM_ SG_ 882 TRCM_a343_curtainAirbagRightDepl "TRCM ECU: a343 curtain airbag right deployed";
CM_ SG_ 882 TRCM_a344_seatbeltLoadLimiterFro "TRCM ECU: a344 seatbelt load limiter front left deployed";
CM_ SG_ 882 TRCM_a345_seatbeltLoadLimiterFro "TRCM ECU: a345 seatbelt load limiter front right deployed";
CM_ SG_ 882 TRCM_a346_seatbeltShoulderPreten "TRCM ECU: a346 seatbelt shoulder pretensioner front left deployed";
CM_ SG_ 882 TRCM_a347_seatbeltShoulderPreten "TRCM ECU: a347 seatbelt shoulder pretensioner front right deployed";
CM_ SG_ 882 TRCM_a348_seatbeltLapPretensione "TRCM ECU: a348 seatbelt lap pretensioner front left deployed";
CM_ SG_ 882 TRCM_a349_seatbeltLapPretensione "TRCM ECU: a349 seatbelt lap pretensioner front right deployed";
CM_ SG_ 882 TRCM_a350_outboardSeatAirbagLeft "TRCM ECU: a350 outboard seat airbag left deployed";
CM_ SG_ 882 TRCM_a351_outboardSeatAirbagRigh "TRCM ECU: a351 outboard seat airbag right deployed";
CM_ SG_ 882 TRCM_a352_hoodLifterLeftDeployed "TRCM ECU: a352 hood lifter left deployed";
CM_ SG_ 882 TRCM_a353_hoodLifterRightDeploye "TRCM ECU: a353 hood lifter right deployed";
CM_ SG_ 882 TRCM_a354_seatbeltShoulderPreten "TRCM ECU: a354 seatbelt shoulder pretensioner rear left deployed";
CM_ SG_ 882 TRCM_a355_seatbeltShoulderPreten "TRCM ECU: a355 seatbelt shoulder pretensioner rear right deployed";
CM_ SG_ 882 TRCM_a364_safingEngine0NoValidDa "TRCM ECU: a364 safing engine0 no valid data";
CM_ SG_ 882 TRCM_a365_safingEngine1NoValidDa "TRCM ECU: a365 safing engine1 no valid data";
CM_ SG_ 882 TRCM_a366_safingEngine2NoValidDa "TRCM ECU: a366 safing engine2 no valid data";
CM_ SG_ 882 TRCM_a367_safingEngine3NoValidDa "TRCM ECU: a367 safing engine3 no valid data";
CM_ SG_ 882 TRCM_a368_safingEngine4NoValidDa "TRCM ECU: a368 safing engine4 no valid data";
CM_ SG_ 882 TRCM_a369_safingEngine5NoValidDa "TRCM ECU: a369 safing engine5 no valid data";
CM_ SG_ 882 TRCM_a370_safingEngine6NoValidDa "TRCM ECU: a370 safing engine6 no valid data";
CM_ SG_ 882 TRCM_a371_safingEngine7NoValidDa "TRCM ECU: a371 safing engine7 no valid data";
CM_ SG_ 882 TRCM_a372_safingEngine8NoValidDa "TRCM ECU: a372 safing engine8 no valid data";
CM_ SG_ 882 TRCM_a373_safingEngine9NoValidDa "TRCM ECU: a373 safing engine9 no valid data";
CM_ SG_ 882 TRCM_a374_safingEngine10NoValidD "TRCM ECU: a374 safing engine10 no valid data";
CM_ SG_ 882 TRCM_a375_safingEngine11NoValidD "TRCM ECU: a375 safing engine11 no valid data";
CM_ SG_ 882 TRCM_a376_safingEngine12NoValidD "TRCM ECU: a376 safing engine12 no valid data";
CM_ SG_ 882 TRCM_a377_safingEngine13NoValidD "TRCM ECU: a377 safing engine13 no valid data";
CM_ SG_ 882 TRCM_a378_safingEngine14NoValidD "TRCM ECU: a378 safing engine14 no valid data";
CM_ SG_ 882 TRCM_a379_safingEngine15NoValidD "TRCM ECU: a379 safing engine15 no valid data";
CM_ SG_ 882 TRCM_a380_safingEngine16NoValidD "TRCM ECU: a380 safing engine16 no valid data";
CM_ SG_ 882 TRCM_a381_safingEngine17NoValidD "TRCM ECU: a381 safing engine17 no valid data";
CM_ SG_ 882 TRCM_a382_safingEngine18NoValidD "TRCM ECU: a382 safing engine18 no valid data";
CM_ SG_ 882 TRCM_a383_safingEngine19NoValidD "TRCM ECU: a383 safing engine19 no valid data";
CM_ SG_ 882 TRCM_a384_safingEngine20NoValidD "TRCM ECU: a384 safing engine20 no valid data";
CM_ SG_ 882 TRCM_a385_safingEngine21NoValidD "TRCM ECU: a385 safing engine21 no valid data";
CM_ SG_ 882 TRCM_a387_primaryAsicResetSource "TRCM ECU: a387 primary asic reset source";
CM_ SG_ 882 TRCM_a388_cpuLoadHigh "TRCM ECU: a388 cpu load high";
CM_ SG_ 882 TRCM_a389_asicPwrStatusError "TRCM ECU: a389 asic pwr status error";
CM_ SG_ 882 TRCM_a390_systemAsicClockOrOpera "TRCM ECU: a390 system asic clock or operating state error";
CM_ SG_ 882 TRCM_a391_extAsic1ClockOrOperati "TRCM ECU: a391 ext asic1 clock or operating state error";
CM_ SG_ 882 TRCM_a392_extAsic2ClockOrOperati "TRCM ECU: a392 ext asic2 clock or operating state error";
CM_ SG_ 882 TRCM_a393_depAdcConvertRatioErro "TRCM ECU: a393 dep adc convert ratio error";
CM_ SG_ 882 TRCM_a394_gspiGlobalStatusWordEr "TRCM ECU: a394 gspi global status word error";
CM_ SG_ 882 TRCM_a395_imuUncalibrated "TRCM ECU: a395 imu uncalibrated";
CM_ SG_ 882 TRCM_a396_spiCommunicationProgra "TRCM ECU: a396 spi communication program error";
CM_ SG_ 882 TRCM_a397_safingMonitorError "TRCM ECU: a397 safing monitor error";
CM_ SG_ 882 TRCM_a398_asicNvmReprogrammed "TRCM ECU: a398 asic nvm reprogrammed";
CM_ SG_ 882 TRCM_a399_imuCalibrationComplete "TRCM ECU: a399 imu calibration complete";
CM_ SG_ 882 TRCM_a400_driverAirbagStage1Issu "TRCM ECU: a400 driver airbag stage1 issue";
CM_ SG_ 882 TRCM_a401_passengerAirbagStage1I "TRCM ECU: a401 passenger airbag stage1 issue";
CM_ SG_ 882 TRCM_a402_driverAirbagStage2Issu "TRCM ECU: a402 driver airbag stage2 issue";
CM_ SG_ 882 TRCM_a403_driverAirbagActiveVent "TRCM ECU: a403 driver airbag active vent issue";
CM_ SG_ 882 TRCM_a404_passengerAirbagStage2I "TRCM ECU: a404 passenger airbag stage2 issue";
CM_ SG_ 882 TRCM_a405_passengerAirbagActiveV "TRCM ECU: a405 passenger airbag active vent issue";
CM_ SG_ 882 TRCM_a406_inboardSeatAirbagIssue "TRCM ECU: a406 inboard seat airbag issue";
CM_ SG_ 882 TRCM_a408_kneeAirbagLeftIssue "TRCM ECU: a408 knee airbag left issue";
CM_ SG_ 882 TRCM_a409_kneeAirbagRightIssue "TRCM ECU: a409 knee airbag right issue";
CM_ SG_ 882 TRCM_a410_curtainAirbagLeftIssue "TRCM ECU: a410 curtain airbag left issue";
CM_ SG_ 882 TRCM_a411_curtainAirbagRightIssu "TRCM ECU: a411 curtain airbag right issue";
CM_ SG_ 882 TRCM_a412_seatbeltLoadLimiterFro "TRCM ECU: a412 seatbelt load limiter front left issue";
CM_ SG_ 882 TRCM_a413_seatbeltLoadLimiterFro "TRCM ECU: a413 seatbelt load limiter front right issue";
CM_ SG_ 882 TRCM_a414_seatbeltShoulderPreten "TRCM ECU: a414 seatbelt shoulder pretensioner front left issue";
CM_ SG_ 882 TRCM_a415_seatbeltShoulderPreten "TRCM ECU: a415 seatbelt shoulder pretensioner front right issue";
CM_ SG_ 882 TRCM_a416_seatbeltLapPretensione "TRCM ECU: a416 seatbelt lap pretensioner front left issue";
CM_ SG_ 882 TRCM_a417_seatbeltLapPretensione "TRCM ECU: a417 seatbelt lap pretensioner front right issue";
CM_ SG_ 882 TRCM_a418_outboardSeatAirbagLeft "TRCM ECU: a418 outboard seat airbag left issue";
CM_ SG_ 882 TRCM_a419_outboardSeatAirbagRigh "TRCM ECU: a419 outboard seat airbag right issue";
CM_ SG_ 882 TRCM_a420_hoodLifterLeftIssue "TRCM ECU: a420 hood lifter left issue";
CM_ SG_ 882 TRCM_a421_hoodLifterRightIssue "TRCM ECU: a421 hood lifter right issue";
CM_ SG_ 882 TRCM_a422_seatbeltShoulderPreten "TRCM ECU: a422 seatbelt shoulder pretensioner rear left issue";
CM_ SG_ 882 TRCM_a423_seatbeltShoulderPreten "TRCM ECU: a423 seatbelt shoulder pretensioner rear right issue";
CM_ SG_ 882 TRCM_a432_driverAirbagStage1Conf "TRCM ECU: a432 driver airbag stage1 config error";
CM_ SG_ 882 TRCM_a433_passengerAirbagStage1C "TRCM ECU: a433 passenger airbag stage1 config error";
CM_ SG_ 882 TRCM_a434_driverAirbagStage2Conf "TRCM ECU: a434 driver airbag stage2 config error";
CM_ SG_ 882 TRCM_a435_driverAirbagActiveVent "TRCM ECU: a435 driver airbag active vent config error";
CM_ SG_ 882 TRCM_a436_passengerAirbagStage2C "TRCM ECU: a436 passenger airbag stage2 config error";
CM_ SG_ 882 TRCM_a437_passengerAirbagActiveV "TRCM ECU: a437 passenger airbag active vent config error";
CM_ SG_ 882 TRCM_a438_inboardSeatAirbagConfi "TRCM ECU: a438 inboard seat airbag config error";
CM_ SG_ 882 TRCM_a440_kneeAirbagLeftConfigEr "TRCM ECU: a440 knee airbag left config error";
CM_ SG_ 882 TRCM_a441_kneeAirbagRightConfigE "TRCM ECU: a441 knee airbag right config error";
CM_ SG_ 882 TRCM_a442_curtainAirbagLeftConfi "TRCM ECU: a442 curtain airbag left config error";
CM_ SG_ 882 TRCM_a443_curtainAirbagRightConf "TRCM ECU: a443 curtain airbag right config error";
CM_ SG_ 882 TRCM_a444_seatbeltLoadLimiterFro "TRCM ECU: a444 seatbelt load limiter front left config error";
CM_ SG_ 882 TRCM_a445_seatbeltLoadLimiterFro "TRCM ECU: a445 seatbelt load limiter front right config error";
CM_ SG_ 882 TRCM_a446_seatbeltShoulderPreten "TRCM ECU: a446 seatbelt shoulder pretensioner front left config error";
CM_ SG_ 882 TRCM_a447_seatbeltShoulderPreten "TRCM ECU: a447 seatbelt shoulder pretensioner front right config error";
CM_ SG_ 882 TRCM_a448_seatbeltLapPretensione "TRCM ECU: a448 seatbelt lap pretensioner front left config error";
CM_ SG_ 882 TRCM_a449_seatbeltLapPretensione "TRCM ECU: a449 seatbelt lap pretensioner front right config error";
CM_ SG_ 882 TRCM_a450_outboardSeatAirbagLeft "TRCM ECU: a450 outboard seat airbag left config error";
CM_ SG_ 882 TRCM_a451_outboardSeatAirbagRigh "TRCM ECU: a451 outboard seat airbag right config error";
CM_ SG_ 882 TRCM_a452_hoodLifterLeftConfigEr "TRCM ECU: a452 hood lifter left config error";
CM_ SG_ 882 TRCM_a453_hoodLifterRightConfigE "TRCM ECU: a453 hood lifter right config error";
CM_ SG_ 882 TRCM_a454_seatbeltShoulderPreten "TRCM ECU: a454 seatbelt shoulder pretensioner rear left config error";
CM_ SG_ 882 TRCM_a455_seatbeltShoulderPreten "TRCM ECU: a455 seatbelt shoulder pretensioner rear right config error";
CM_ SG_ 882 TRCM_a544_erCapDiagnosticsFailed "TRCM ECU: a544 er cap diagnostics failed";
CM_ SG_ 882 TRCM_a545_erCapBelowAutarkyThres "TRCM ECU: a545 er cap below autarky threshold";
CM_ SG_ 882 TRCM_a546_sensorValuesFaultedByS "TRCM ECU: a546 sensor values faulted by smart";
CM_ SG_ 882 TRCM_a550_AlgoWake_RCM_WAKE_FRON "TRCM ECU: a550 algo wake RCM WAKE FRONT";
CM_ SG_ 882 TRCM_a551_AlgoWake_RCM_WAKE_REAR "TRCM ECU: a551 algo wake RCM WAKE REAR";
CM_ SG_ 882 TRCM_a552_AlgoWake_RCM_WAKE_LEFT "TRCM ECU: a552 algo wake RCM WAKE LEFT";
CM_ SG_ 882 TRCM_a553_AlgoWake_RCM_WAKE_RIGH "TRCM ECU: a553 algo wake RCM WAKE RIGHT";
CM_ SG_ 882 TRCM_a554_AlgoWake_PAS_LH_PLAUSI "TRCM ECU: a554 algo wake PAS LH PLAUSI FRONT";
CM_ SG_ 882 TRCM_a555_AlgoWake_PAS_LH_PLAUSI "TRCM ECU: a555 algo wake PAS LH PLAUSI REAR";
CM_ SG_ 882 TRCM_a557_AlgoWake_PAS_RH_PLAUSI "TRCM ECU: a557 algo wake PAS RH PLAUSI FRONT";
CM_ SG_ 882 TRCM_a558_AlgoWake_PAS_RH_PLAUSI "TRCM ECU: a558 algo wake PAS RH PLAUSI REAR";
CM_ SG_ 882 TRCM_a560_AlgoWake_RCM_WAKE_ROLL "TRCM ECU: a560 algo wake RCM WAKE ROLL LEFT";
CM_ SG_ 882 TRCM_a561_AlgoWake_RCM_WAKE_ROLL "TRCM ECU: a561 algo wake RCM WAKE ROLL RIGHT";
CM_ SG_ 882 TRCM_a562_AlgoWake_RCM_AWAKE_FRO "TRCM ECU: a562 algo wake RCM AWAKE FRONT";
CM_ SG_ 882 TRCM_a563_AlgoWake_RCM_AWAKE_REA "TRCM ECU: a563 algo wake RCM AWAKE REAR";
CM_ SG_ 882 TRCM_a564_AlgoWake_RCM_AWAKE_LEF "TRCM ECU: a564 algo wake RCM AWAKE LEFT";
CM_ SG_ 882 TRCM_a565_AlgoWake_RCM_AWAKE_RIG "TRCM ECU: a565 algo wake RCM AWAKE RIGHT";
CM_ SG_ 882 TRCM_a566_AlgoWake_RCM_AWAKE_ROL "TRCM ECU: a566 algo wake RCM AWAKE ROLL";
CM_ SG_ 882 TRCM_a567_AlgoWake_RCM_AWAKE_X "TRCM ECU: a567 algo wake RCM AWAKE x";
CM_ SG_ 882 TRCM_a568_AlgoWake_RCM_AWAKE_Y "TRCM ECU: a568 algo wake RCM AWAKE y";
CM_ SG_ 882 TRCM_a569_AlgoWake_PAS_WAKE_LEFT "TRCM ECU: a569 algo wake PAS WAKE LEFT";
CM_ SG_ 882 TRCM_a570_AlgoWake_PAS_WAKE_RIGH "TRCM ECU: a570 algo wake PAS WAKE RIGHT";
CM_ SG_ 882 TRCM_a576_AlgoWake_IMPACT_FINISH "TRCM ECU: a576 algo wake IMPACT FINISH x";
CM_ SG_ 882 TRCM_a577_AlgoWake_IMPACT_FINISH "TRCM ECU: a577 algo wake IMPACT FINISH y";
CM_ SG_ 882 TRCM_a578_AlgoWake_IMPACT_FINISH "TRCM ECU: a578 algo wake IMPACT FINISH ROLL";
CM_ SG_ 882 TRCM_a579_AlgoWake_RCM_ENABLED_X "TRCM ECU: a579 algo wake RCM ENABLED x";
CM_ SG_ 882 TRCM_a580_AlgoWake_RCM_ENABLED_Y "TRCM ECU: a580 algo wake RCM ENABLED y";
CM_ SG_ 882 TRCM_a581_AlgoWake_RCM_ENABLED_R "TRCM ECU: a581 algo wake RCM ENABLED ROLL";
CM_ SG_ 882 TRCM_a582_AlgoWake_RCM_AWAKE "TRCM ECU: a582 algo wake RCM AWAKE";
CM_ SG_ 882 TRCM_a588_yawRateOffsetPosLimit "TRCM ECU: a588 yaw rate offset pos limit";
CM_ SG_ 882 TRCM_a589_yawRateOffsetNegLimit "TRCM ECU: a589 yaw rate offset neg limit";
CM_ SG_ 882 TRCM_a590_pitchRateOffsetPosLimi "TRCM ECU: a590 pitch rate offset pos limit";
CM_ SG_ 882 TRCM_a591_pitchRateOffsetNegLimi "TRCM ECU: a591 pitch rate offset neg limit";
CM_ SG_ 882 TRCM_a592_rollRateOffsetPosLimit "TRCM ECU: a592 roll rate offset pos limit";
CM_ SG_ 882 TRCM_a593_rollRateOffsetNegLimit "TRCM ECU: a593 roll rate offset neg limit";
CM_ SG_ 882 TRCM_a594_longitudinalAccelOffse "TRCM ECU: a594 longitudinal accel offset pos limit";
CM_ SG_ 882 TRCM_a595_longitudinalAccelOffse "TRCM ECU: a595 longitudinal accel offset neg limit";
CM_ SG_ 882 TRCM_a596_lateralAccelOffsetPosL "TRCM ECU: a596 lateral accel offset pos limit";
CM_ SG_ 882 TRCM_a597_lateralAccelOffsetNegL "TRCM ECU: a597 lateral accel offset neg limit";
CM_ SG_ 882 TRCM_a598_verticalAccelOffsetPos "TRCM ECU: a598 vertical accel offset pos limit";
CM_ SG_ 882 TRCM_a599_verticalAccelOffsetNeg "TRCM ECU: a599 vertical accel offset neg limit";
CM_ SG_ 882 TRCM_a600_airbagAsicStartupFailu "TRCM ECU: a600 airbag asic startup failure";
CM_ SG_ 882 TRCM_a601_loop0AsicStartupDiagno "TRCM ECU: a601 loop0 asic startup diagnostic failure";
CM_ SG_ 882 TRCM_a602_loop1AsicStartupDiagno "TRCM ECU: a602 loop1 asic startup diagnostic failure";
CM_ SG_ 882 TRCM_a603_loop2AsicStartupDiagno "TRCM ECU: a603 loop2 asic startup diagnostic failure";
CM_ SG_ 882 TRCM_a604_loop3AsicStartupDiagno "TRCM ECU: a604 loop3 asic startup diagnostic failure";
CM_ SG_ 882 TRCM_a605_loop4AsicStartupDiagno "TRCM ECU: a605 loop4 asic startup diagnostic failure";
CM_ SG_ 882 TRCM_a606_loop5AsicStartupDiagno "TRCM ECU: a606 loop5 asic startup diagnostic failure";
CM_ SG_ 882 TRCM_a607_loop6AsicStartupDiagno "TRCM ECU: a607 loop6 asic startup diagnostic failure";
CM_ SG_ 882 TRCM_a608_loop7AsicStartupDiagno "TRCM ECU: a608 loop7 asic startup diagnostic failure";
CM_ SG_ 882 TRCM_a609_loop8AsicStartupDiagno "TRCM ECU: a609 loop8 asic startup diagnostic failure";
CM_ SG_ 882 TRCM_a610_loop9AsicStartupDiagno "TRCM ECU: a610 loop9 asic startup diagnostic failure";
CM_ SG_ 882 TRCM_a611_loop10AsicStartupDiagn "TRCM ECU: a611 loop10 asic startup diagnostic failure";
CM_ SG_ 882 TRCM_a612_loop11AsicStartupDiagn "TRCM ECU: a612 loop11 asic startup diagnostic failure";
CM_ SG_ 882 TRCM_a613_loop12AsicStartupDiagn "TRCM ECU: a613 loop12 asic startup diagnostic failure";
CM_ SG_ 882 TRCM_a614_loop13AsicStartupDiagn "TRCM ECU: a614 loop13 asic startup diagnostic failure";
CM_ SG_ 882 TRCM_a615_loop14AsicStartupDiagn "TRCM ECU: a615 loop14 asic startup diagnostic failure";
CM_ SG_ 882 TRCM_a616_loop15AsicStartupDiagn "TRCM ECU: a616 loop15 asic startup diagnostic failure";
CM_ SG_ 882 TRCM_a617_loop16AsicStartupDiagn "TRCM ECU: a617 loop16 asic startup diagnostic failure";
CM_ SG_ 882 TRCM_a618_loop17AsicStartupDiagn "TRCM ECU: a618 loop17 asic startup diagnostic failure";
CM_ SG_ 882 TRCM_a619_loop18AsicStartupDiagn "TRCM ECU: a619 loop18 asic startup diagnostic failure";
CM_ SG_ 882 TRCM_a620_loop19AsicStartupDiagn "TRCM ECU: a620 loop19 asic startup diagnostic failure";
CM_ SG_ 882 TRCM_a621_loop20AsicStartupDiagn "TRCM ECU: a621 loop20 asic startup diagnostic failure";
CM_ SG_ 882 TRCM_a622_loop21AsicStartupDiagn "TRCM ECU: a622 loop21 asic startup diagnostic failure";
CM_ SG_ 882 TRCM_a623_loop22AsicStartupDiagn "TRCM ECU: a623 loop22 asic startup diagnostic failure";
CM_ SG_ 882 TRCM_a624_loop23AsicStartupDiagn "TRCM ECU: a624 loop23 asic startup diagnostic failure";
CM_ SG_ 882 TRCM_a625_loop24AsicStartupDiagn "TRCM ECU: a625 loop24 asic startup diagnostic failure";
CM_ SG_ 882 TRCM_a626_loop25AsicStartupDiagn "TRCM ECU: a626 loop25 asic startup diagnostic failure";
CM_ SG_ 882 TRCM_a627_loop26AsicStartupDiagn "TRCM ECU: a627 loop26 asic startup diagnostic failure";
CM_ SG_ 882 TRCM_a628_loop27AsicStartupDiagn "TRCM ECU: a628 loop27 asic startup diagnostic failure";
CM_ SG_ 882 TRCM_a629_loop28AsicStartupDiagn "TRCM ECU: a629 loop28 asic startup diagnostic failure";
CM_ SG_ 882 TRCM_a630_loop29AsicStartupDiagn "TRCM ECU: a630 loop29 asic startup diagnostic failure";
CM_ SG_ 882 TRCM_a631_loop30AsicStartupDiagn "TRCM ECU: a631 loop30 asic startup diagnostic failure";
CM_ SG_ 882 TRCM_a632_loop31AsicStartupDiagn "TRCM ECU: a632 loop31 asic startup diagnostic failure";
CM_ SG_ 882 TRCM_a633_glacierInitialStatusFa "TRCM ECU: a633 glacier initial status failure";
CM_ SG_ 882 TRCM_a634_glacierTraceabilityRea "TRCM ECU: a634 glacier traceability readout A0 A0 failure";
CM_ SG_ 882 TRCM_a635_glacierTraceabilityRea "TRCM ECU: a635 glacier traceability readout B0 B0 failure";
CM_ SG_ 882 TRCM_a636_glacierRegisterPattern "TRCM ECU: a636 glacier register pattern write failure";
CM_ SG_ 882 TRCM_a637_glacierFixedPatternSel "TRCM ECU: a637 glacier fixed pattern self test failure";
CM_ SG_ 882 TRCM_a638_glacierSelfTestEFailur "TRCM ECU: a638 glacier self test e failure";
CM_ SG_ 882 TRCM_a639_glacierSelfTestFFailur "TRCM ECU: a639 glacier self test f failure";
CM_ SG_ 882 TRCM_a640_glacierAnalogSelfTestF "TRCM ECU: a640 glacier analog self test failure";
CM_ SG_ 882 TRCM_a641_glacierOscillatorVerif "TRCM ECU: a641 glacier oscillator verification failure";
CM_ SG_ 882 TRCM_a642_glacierFinalStatusFail "TRCM ECU: a642 glacier final status failure";
CM_ SG_ 882 TRCM_a643_glacierOffsetVerificat "TRCM ECU: a643 glacier offset verification failure";
CM_ SG_ 882 TRCM_a644_glacierNormalOperation "TRCM ECU: a644 glacier normal operation failure";
CM_ SG_ 882 TRCM_a645_glacierDeviceReset "TRCM ECU: a645 glacier device reset";
CM_ SG_ 882 TRCM_a646_glacierDeviceFaulted "TRCM ECU: a646 glacier device faulted";
CM_ BO_ 850 "TRCM ECU message: info";
CM_ SG_ 850 TRCM_infoIndex "TRCM ECU: info index";
CM_ SG_ 850 TRCM_infoBuildType "TRCM ECU: info build type";
CM_ SG_ 850 TRCM_infoBuildConfigId "TRCM ECU: info build config id";
CM_ SG_ 850 TRCM_infoHardwareId "TRCM ECU: info hardware id";
CM_ SG_ 850 TRCM_infoComponentId "TRCM ECU: info component id";
CM_ SG_ 850 TRCM_infoPcbaId "TRCM ECU: info pcba id";
CM_ SG_ 850 TRCM_infoAssemblyId "TRCM ECU: info assembly id; raw 255 = signal not available (SNA)";
CM_ SG_ 850 TRCM_infoUsageId "TRCM ECU: info usage id";
CM_ SG_ 850 TRCM_infoSubUsageId "TRCM ECU: info sub usage id";
CM_ SG_ 850 TRCM_infoAppCrc "TRCM ECU: info app crc";
CM_ SG_ 850 TRCM_infoAppGitHash "TRCM ECU: info app git hash";
CM_ SG_ 850 TRCM_infoBootGitHash "TRCM ECU: info boot git hash";
CM_ SG_ 850 TRCM_infoBootUdsProtoVersion "TRCM ECU: info boot uds proto version";
CM_ SG_ 850 TRCM_infoBootCrc "TRCM ECU: info boot crc";
CM_ BO_ 1021 "Touchscreen user interface computer message: autopilot control; forwarded onto this bus by the gateway";
CM_ SG_ 1021 UI_autopilotControlIndex "Touchscreen user interface computer: autopilot control index";
CM_ SG_ 1021 UI_hovEnabled "UI HOV routes enabled";
CM_ SG_ 1021 UI_donDisableAutoWiperDuration "Touchscreen user interface computer: don disable auto wiper duration";
CM_ SG_ 1021 UI_donDisableOnAutoWiperSpeed "Touchscreen user interface computer: don disable on auto wiper speed";
CM_ SG_ 1021 UI_blindspotMinSpeed "Touchscreen user interface computer: blindspot min speed";
CM_ SG_ 1021 UI_blindspotDistance "Touchscreen user interface computer: blindspot distance";
CM_ SG_ 1021 UI_blindspotTTC "Touchscreen user interface computer: blindspot TTC";
CM_ SG_ 1021 UI_donStopEndOfRampBuffer "Touchscreen user interface computer: don stop end of ramp buffer";
CM_ SG_ 1021 UI_donDisableCutin "Touchscreen user interface computer: don disable cutin";
CM_ SG_ 1021 UI_smartSetSpeedOffset "TACC will apply this offset over the speed limit";
CM_ SG_ 1021 UI_smartSetSpeedOffsetType "Offset applied will be a percentage or fixed value based on this setting";
CM_ SG_ 1021 UI_autopilotMonarchBackup "Touchscreen user interface computer: autopilot monarch backup";
CM_ SG_ 1021 UI_fsdVisualizationEnabled "Touchscreen user interface computer: fsd visualization enabled";
CM_ SG_ 1021 UI_fsdStopsControlEnabled "Indicates if autopilot control for traffic lights and stops signs has been enabled by the driver";
CM_ SG_ 1021 UI_fsdContinueOnGreenWithCIPV "Touchscreen user interface computer: fsd continue on green with CIPV";
CM_ SG_ 1021 UI_smartSetSpeed "TACC will use speed limit + offset as user set speed when enabled";
CM_ SG_ 1021 UI_automaticSetSpeedOffset "Maximum set speed offset would be determined automatically when this option is enabled";
CM_ SG_ 1021 UI_apply2021_1958_ISA "Touchscreen user interface computer: apply2021 1958 ISA";
CM_ SG_ 1021 UI_apply2021_646_ELKS "Touchscreen user interface computer: apply2021 646 ELKS";
CM_ SG_ 1021 UI_apply2021_1341_DDAW "Touchscreen user interface computer: apply2021 1341 DDAW";
CM_ SG_ 1021 UI_homelinkNearby "Touchscreen user interface computer: homelink nearby";
CM_ SG_ 1021 UI_enableFullSelfDriving "Indicates if the driver has enabled FSD behaviors";
CM_ SG_ 1021 UI_hasFullSelfDriving "Indicates if the vehicle hardware, software, and dependencies allow FSD";
CM_ SG_ 1021 UI_autosteerActivation "User-selected autosteer activation method";
CM_ SG_ 1021 UI_fsdBetaRequest "User accepted disclaimer and requested FSD (Supervised) builds";
CM_ SG_ 1021 UI_fullSelfDrivingSuspended "Full self driving is suspended";
CM_ SG_ 1021 UI_disableOptionalLaneChanges "Disable optional lane changes while FSD is controlling";
CM_ SG_ 1021 UI_applyR152_AEBS "Touchscreen user interface computer: apply R152 AEBS";
CM_ SG_ 1021 UI_applyDCASBehavior "Touchscreen user interface computer: apply DCAS behavior";
CM_ SG_ 1021 UI_applyDCASBehaviorLegacy "Touchscreen user interface computer: apply DCAS behavior legacy";
CM_ SG_ 1021 UI_applyADDWWarnings "ADDW warnings are enabled on this vehicle";
CM_ SG_ 1021 UI_autopilotControlMux0Valid "Touchscreen user interface computer: autopilot control mux0 valid";
CM_ SG_ 1021 UI_selectableCameraRequest "Infotainment selectable camera state request from AP signal; raw 15 = signal not available (SNA)";
CM_ SG_ 1021 UI_overrideSleepWithSuspend "Touchscreen user interface computer: override sleep with suspend";
CM_ SG_ 1021 UI_driverMonitorConfirmation "Driver attentiveness confirmation";
CM_ SG_ 1021 UI_parkAssistUseVision "Reports if the vehicle should use vision park assist.";
CM_ SG_ 1021 UI_applyEceR79 "Touchscreen user interface computer: apply ece R79";
CM_ SG_ 1021 UI_enableMapStops "Touchscreen user interface computer: enable map stops";
CM_ SG_ 1021 UI_disableMain "Touchscreen user interface computer: disable main";
CM_ SG_ 1021 UI_disableNarrow "Touchscreen user interface computer: disable narrow";
CM_ SG_ 1021 UI_disableFisheye "Touchscreen user interface computer: disable fisheye";
CM_ SG_ 1021 UI_disableLeftPillar "Touchscreen user interface computer: disable left pillar";
CM_ SG_ 1021 UI_disableRightPillar "Touchscreen user interface computer: disable right pillar";
CM_ SG_ 1021 UI_disableLeftRepeater "Touchscreen user interface computer: disable left repeater";
CM_ SG_ 1021 UI_disableRightRepeater "Touchscreen user interface computer: disable right repeater";
CM_ SG_ 1021 UI_disableBackup "Touchscreen user interface computer: disable backup";
CM_ SG_ 1021 UI_disableRadar "Touchscreen user interface computer: disable radar";
CM_ SG_ 1021 UI_noStalkConfirmAlertHaptic "Detects if alert haptic feedback should trigger.";
CM_ SG_ 1021 UI_regulatoryLKA "Touchscreen user interface computer: regulatory LKA";
CM_ SG_ 1021 UI_regulatoryLaneAssistLevel "Touchscreen user interface computer: regulatory lane assist level";
CM_ SG_ 1021 UI_ulcSnooze "Touchscreen user interface computer: ulc snooze";
CM_ SG_ 1021 UI_noStalkConfirmAlertChime "Detects if alert chime should trigger.";
CM_ SG_ 1021 UI_factorySummonEnable "Controls Factory Summon.";
CM_ SG_ 1021 UI_apmv3Branch "Touchscreen user interface computer: apmv3 branch";
CM_ SG_ 1021 UI_enableCabinCamera "Indicates if autopilot can enable cabin camera";
CM_ SG_ 1021 UI_enableAutopilotStopWarning "Enables the Autopilot active red light warning function.";
CM_ SG_ 1021 UI_showLaneGraph "Touchscreen user interface computer: show lane graph";
CM_ SG_ 1021 UI_showTrackLabels "Touchscreen user interface computer: show track labels";
CM_ SG_ 1021 UI_hardCoreSummon "Touchscreen user interface computer: hard core summon";
CM_ SG_ 1021 UI_enableCabinCameraTelemetry "Touchscreen user interface computer: enable cabin camera telemetry";
CM_ SG_ 1021 UI_enableVisionSpeedControl "Indicates if autopilot can enable vision speed control";
CM_ SG_ 1021 UI_autopilotTelemetryInChina "Touchscreen user interface computer: autopilot telemetry in china";
CM_ SG_ 1021 UI_enableTeslaAutopark "Indicates if autopilot can enable Telsa Autopark control";
CM_ SG_ 1021 UI_autoTurnSignalMode "Turn signal activation mode";
CM_ SG_ 1021 UI_enableCautionLightControl "Touchscreen user interface computer: enable caution light control";
CM_ SG_ 1021 UI_applyEceR79SmartSummonOnly "Touchscreen user interface computer: apply ece R79 smart summon only";
CM_ SG_ 1021 UI_autopilotMonarchEnabled "Touchscreen user interface computer: autopilot monarch enabled";
CM_ SG_ 1021 UI_autopilotEphemerisEnabled "Touchscreen user interface computer: autopilot ephemeris enabled";
CM_ SG_ 1021 UI_enableCabinAudioRecording "Indicates if autopilot can record cabin audio";
CM_ SG_ 1021 UI_autopilotControlMux1Valid "Touchscreen user interface computer: autopilot control mux1 valid";
CM_ SG_ 1021 UI_enableApproachingEmergencyVeh "Touchscreen user interface computer: enable approaching emergency vehicle detection";
CM_ SG_ 1021 UI_enableStartFsdFromParkBrakeCo "Touchscreen user interface computer: enable start fsd from park brake confirmation";
CM_ SG_ 1021 UI_enableStartFsdFromPark "Touchscreen user interface computer: enable start fsd from park";
CM_ SG_ 1021 UI_fsdMaxSpeedOffsetPercentage "Touchscreen user interface computer: fsd max speed offset percentage";
CM_ SG_ 1021 UI_calibrationReadyInFactory "Touchscreen user interface computer: calibration ready in factory";
CM_ SG_ 1021 UI_coldStartMonarchInFactory "Touchscreen user interface computer: cold start monarch in factory";
CM_ SG_ 1021 UI_navMinutesToArrival "Touchscreen user interface computer: nav minutes to arrival";
CM_ SG_ 1021 UI_fsdQuizRequired "Touchscreen user interface computer: fsd quiz required";
CM_ SG_ 1021 UI_fsdQuizPassed "Touchscreen user interface computer: fsd quiz passed";
CM_ SG_ 1021 UI_fsdAllowedInLocalizedRegion "Touchscreen user interface computer: fsd allowed in localized region";
CM_ SG_ 1021 UI_autopilotDrivingProfile "Driving profile for autopilot control";
CM_ SG_ 1021 UI_autopilotControlMux2Valid "Touchscreen user interface computer: autopilot control mux2 valid";
CM_ BO_ 659 "Touchscreen user interface computer message: chassis control; forwarded onto this bus by the gateway";
CM_ SG_ 659 UI_steeringTuneRequest "UI customer level request for steering feel. MS had comfort, normal, sport. M3 intent is Normal, sport see SW-95934";
CM_ SG_ 659 UI_tractionControlMode "Transport user selected traction control modes";
CM_ SG_ 659 UI_parkBrakeRequest "User selection for Park brake; raw 3 = signal not available (SNA)";
CM_ SG_ 659 UI_narrowGarages "Touchscreen user interface computer: narrow garages";
CM_ SG_ 659 UI_winchModeRequest "Winch mode (towing) request";
CM_ SG_ 659 UI_zeroSpeedConfirmed "Touchscreen user interface computer: zero speed confirmed; raw 3 = signal not available (SNA)";
CM_ SG_ 659 UI_trailerMode "Indicates whether trailer mode is selected. To be used when towing a trailer.";
CM_ SG_ 659 UI_distanceUnits "Touchscreen user interface computer: distance units";
CM_ SG_ 659 UI_dasDebugEnable "Touchscreen user interface computer: das debug enable";
CM_ SG_ 659 UI_accOvertakeEnable "Enable ACC Overtake assistance (reduce follow distance when the turn signal is on), UI firmware only sets datavalue to True; raw 3 = signal not available (SNA)";
CM_ SG_ 659 UI_aebEnable "Enable Autonomous Emergency Brakes; raw 3 = signal not available (SNA)";
CM_ SG_ 659 UI_aesEnable "Enable Automatic Emergency Steering (associated datavalue set to true and never changed by UI firmware); raw 3 = signal not available (SNA)";
CM_ SG_ 659 UI_ahlbEnable "Enable Automatic High/Low Beams; raw 3 = signal not available (SNA)";
CM_ SG_ 659 UI_autoLaneChangeEnable "Enable Automatic Lane Change; raw 3 = signal not available (SNA)";
CM_ SG_ 659 UI_winchProxUserOverride "User feedback from tow mode panel confirming that charge cable is disconnected when vehicle is unable to determine cable status";
CM_ SG_ 659 UI_rebootAutopilot "Touchscreen user interface computer: reboot autopilot";
CM_ SG_ 659 UI_autoParkRequest "Request Automatic Parking; raw 15 = signal not available (SNA)";
CM_ SG_ 659 UI_bsdEnable "Enable Blind Spot Detection (datavalue defaults to true and not changed by UI firmware); raw 3 = signal not available (SNA)";
CM_ SG_ 659 UI_fcwEnable "Enable Forward Collision Warning; raw 3 = signal not available (SNA)";
CM_ SG_ 659 UI_fcwSensitivity "Forward Collision Warning Level; raw 3 = signal not available (SNA)";
CM_ SG_ 659 UI_latControlEnable "Enable Lateral Control (lane centering, lane keeping, lane changing); raw 3 = signal not available (SNA)";
CM_ SG_ 659 UI_ldwEnable "Enable Lane Departure Warning; raw 3 = signal not available (SNA)";
CM_ SG_ 659 UI_pedalSafetyEnable "Touchscreen user interface computer: pedal safety enable; raw 3 = signal not available (SNA)";
CM_ SG_ 659 UI_pedalMap_epas "Touchscreen user interface computer: pedal map epas";
CM_ SG_ 659 UI_redLightStopSignEnable "Touchscreen user interface computer: red light stop sign enable; raw 3 = signal not available (SNA)";
CM_ SG_ 659 UI_selfParkTune "Touchscreen user interface computer: self park tune; raw 15 = signal not available (SNA)";
CM_ SG_ 659 UI_chassisControlCounter "Touchscreen user interface computer: chassis control counter";
CM_ SG_ 659 UI_chassisControlChecksum "Touchscreen user interface computer: chassis control checksum";
CM_ BO_ 664 "Touchscreen user interface computer message: csa offramp curvature; forwarded onto this bus by the gateway";
CM_ SG_ 664 UI_csaOfframpCurvC2 "Touchscreen user interface computer: csa offramp curv C2";
CM_ SG_ 664 UI_csaOfframpCurvC3 "Touchscreen user interface computer: csa offramp curv C3";
CM_ SG_ 664 UI_csaOfframpCurvRange "Touchscreen user interface computer: csa offramp curv range";
CM_ SG_ 664 UI_csaOfframpCurvCounter "Touchscreen user interface computer: csa offramp curv counter";
CM_ SG_ 664 UI_csaOfframpCurvUsingTspline "Touchscreen user interface computer: csa offramp curv using tspline";
CM_ SG_ 664 UI_csaOfframpCurvReserved "Touchscreen user interface computer: csa offramp curv reserved";
CM_ SG_ 664 UI_csaOfframpCurvChecksum "Touchscreen user interface computer: csa offramp curv checksum";
CM_ BO_ 679 "Touchscreen user interface computer message: csa road curvature; forwarded onto this bus by the gateway";
CM_ SG_ 679 UI_csaRoadCurvC2 "Touchscreen user interface computer: csa road curv C2";
CM_ SG_ 679 UI_csaRoadCurvC3 "Touchscreen user interface computer: csa road curv C3";
CM_ SG_ 679 UI_csaRoadCurvRange "Touchscreen user interface computer: csa road curv range";
CM_ SG_ 679 UI_csaRoadCurvCounter "Touchscreen user interface computer: csa road curv counter";
CM_ SG_ 679 UI_csaRoadCurvUsingTspline "Touchscreen user interface computer: csa road curv using tspline";
CM_ SG_ 679 UI_csaRoadCurvReserved "Touchscreen user interface computer: csa road curv reserved";
CM_ SG_ 679 UI_csaRoadCurvChecksum "Touchscreen user interface computer: csa road curv checksum";
CM_ BO_ 1096 "Touchscreen user interface computer message: driver assist anon debug params; forwarded onto this bus by the gateway";
CM_ SG_ 1096 UI_anonDebugParam1 "Touchscreen user interface computer: anon debug param1";
CM_ SG_ 1096 UI_anonDebugFlag1 "Touchscreen user interface computer: anon debug flag1";
CM_ SG_ 1096 UI_anonDebugParam2 "Touchscreen user interface computer: anon debug param2";
CM_ SG_ 1096 UI_anonDebugFlag2 "Touchscreen user interface computer: anon debug flag2";
CM_ SG_ 1096 UI_anonDebugParam3 "Touchscreen user interface computer: anon debug param3";
CM_ SG_ 1096 UI_anonDebugFlag3 "Touchscreen user interface computer: anon debug flag3";
CM_ SG_ 1096 UI_anonDebugParam4 "Touchscreen user interface computer: anon debug param4";
CM_ SG_ 1096 UI_anonDebugFlag4 "Touchscreen user interface computer: anon debug flag4";
CM_ SG_ 1096 UI_anonDebugParam5 "Touchscreen user interface computer: anon debug param5";
CM_ SG_ 1096 UI_anonDebugParam6 "Touchscreen user interface computer: anon debug param6";
CM_ SG_ 1096 UI_anonDebugParam7 "Touchscreen user interface computer: anon debug param7";
CM_ SG_ 1096 UI_visionSpeedSlider "Touchscreen user interface computer: vision speed slider";
CM_ BO_ 1016 "Touchscreen user interface computer message: driver assist control; forwarded onto this bus by the gateway";
CM_ SG_ 1016 UI_autopilotControlRequest "Touchscreen user interface computer: autopilot control request";
CM_ SG_ 1016 UI_ulcStalkConfirm "Drive on autopilot stalk confirmation mode (set by feature config).";
CM_ SG_ 1016 UI_summonHeartbeat "Touchscreen user interface computer: summon heartbeat";
CM_ SG_ 1016 UI_curvSpeedAdaptDisable "Touchscreen user interface computer: curv speed adapt disable";
CM_ SG_ 1016 UI_dasDeveloper "Touchscreen user interface computer: das developer";
CM_ SG_ 1016 UI_enableVinAssociation "Touchscreen user interface computer: enable vin association";
CM_ SG_ 1016 UI_lssLkaEnabled "User setting for lane keep assist";
CM_ SG_ 1016 UI_lssLdwEnabled "User setting for lane departure warning";
CM_ SG_ 1016 UI_coastToCoast "Touchscreen user interface computer: coast to coast";
CM_ SG_ 1016 UI_autoSummonEnable "Touchscreen user interface computer: auto summon enable";
CM_ SG_ 1016 UI_exceptionListEnable "Touchscreen user interface computer: exception list enable";
CM_ SG_ 1016 UI_roadCheckDisable "Touchscreen user interface computer: road check disable";
CM_ SG_ 1016 UI_driveOnMapsEnable "Drive on Autopilot enabled";
CM_ SG_ 1016 UI_handsOnRequirementDisable "Touchscreen user interface computer: hands on requirement disable";
CM_ SG_ 1016 UI_ulcOffHighway "Touchscreen user interface computer: ulc off highway";
CM_ SG_ 1016 UI_fuseLanesDisable "Touchscreen user interface computer: fuse lanes disable";
CM_ SG_ 1016 UI_fuseHPPDisable "Touchscreen user interface computer: fuse HPP disable";
CM_ SG_ 1016 UI_fuseVehiclesDisable "Touchscreen user interface computer: fuse vehicles disable";
CM_ SG_ 1016 UI_enableClipParkedTelemetry "Touchscreen user interface computer: enable clip parked telemetry";
CM_ SG_ 1016 UI_visionSpeedType "Touchscreen user interface computer: vision speed type";
CM_ SG_ 1016 UI_curvatureDatabaseOnly "Touchscreen user interface computer: curvature database only";
CM_ SG_ 1016 UI_lssElkEnabled "User setting for emergency lane keep";
CM_ SG_ 1016 UI_summonExitType "Touchscreen user interface computer: summon exit type; raw 3 = signal not available (SNA)";
CM_ SG_ 1016 UI_summonEntryType "Touchscreen user interface computer: summon entry type; raw 3 = signal not available (SNA)";
CM_ SG_ 1016 UI_selfParkRequest "Self park request; raw 15 = signal not available (SNA)";
CM_ SG_ 1016 UI_summonReverseDist "Touchscreen user interface computer: summon reverse dist; raw 63 = signal not available (SNA)";
CM_ SG_ 1016 UI_undertakeAssistEnable "Touchscreen user interface computer: undertake assist enable";
CM_ SG_ 1016 UI_adaptiveSetSpeedEnable "Touchscreen user interface computer: adaptive set speed enable";
CM_ SG_ 1016 UI_drivingSide "Touchscreen user interface computer: driving side";
CM_ SG_ 1016 UI_enableClipTelemetry "Touchscreen user interface computer: enable clip telemetry";
CM_ SG_ 1016 UI_enableTripTelemetry "Touchscreen user interface computer: enable trip telemetry";
CM_ SG_ 1016 UI_enableRoadSegmentTelemetry "Touchscreen user interface computer: enable road segment telemetry";
CM_ SG_ 1016 UI_accFollowDistanceSetting "Touchscreen user interface computer: acc follow distance setting; raw 7 = signal not available (SNA)";
CM_ SG_ 1016 UI_hasDriveOnNav "Touchscreen user interface computer: has drive on nav";
CM_ SG_ 1016 UI_followNavRouteEnable "Following route with Drive on Autopilot";
CM_ SG_ 1016 UI_ulcSpeedConfig "Drive on autopilot speed base lane changes mode.";
CM_ SG_ 1016 UI_ulcBlindSpotConfig "Touchscreen user interface computer: ulc blind spot config";
CM_ SG_ 1016 UI_suppressExitPassingLane "Navigate on Autopilot will not suggest lane changes out of the passing lane";
CM_ SG_ 1016 UI_enableClipStartStopTelemetry "Touchscreen user interface computer: enable clip start stop telemetry";
CM_ SG_ 1016 UI_alcOffHighwayEnable "Touchscreen user interface computer: alc off highway enable";
CM_ SG_ 1016 UI_validationLoop "Touchscreen user interface computer: validation loop";
CM_ SG_ 1016 UI_smartSummonType "Type of smart summon session (Find Me, Pin Drop, Smart Autopark)";
CM_ SG_ 1016 UI_enableVisionOnlyStops "Touchscreen user interface computer: enable vision only stops";
CM_ SG_ 1016 UI_source3D "Touchscreen user interface computer: source3 d";
CM_ SG_ 1016 UI_isaSpeedingChimeMuted "Reports the user input of Intelligent Speed Assist (ISA) speed chime alert option.";
CM_ BO_ 568 "Touchscreen user interface computer message: driver assist map data; forwarded onto this bus by the gateway";
CM_ SG_ 568 UI_mapSpeedLimitDependency "Touchscreen user interface computer: map speed limit dependency; raw 7 = signal not available (SNA)";
CM_ SG_ 568 UI_roadClass "Autopilot map road class; raw 0 = signal not available (SNA)";
CM_ SG_ 568 UI_inSuperchargerGeofence "Touchscreen user interface computer: in supercharger geofence";
CM_ SG_ 568 UI_mapSpeedUnits "Touchscreen user interface computer: map speed units";
CM_ SG_ 568 UI_mapSpeedLimit "Touchscreen user interface computer: map speed limit; raw 31 = signal not available (SNA)";
CM_ SG_ 568 UI_mapSpeedLimitType "Touchscreen user interface computer: map speed limit type; raw 7 = signal not available (SNA)";
CM_ SG_ 568 UI_countryCode "Touchscreen user interface computer: country code; raw 1023 = signal not available (SNA)";
CM_ SG_ 568 UI_streetCount "Touchscreen user interface computer: street count";
CM_ SG_ 568 UI_gpsRoadMatch "Touchscreen user interface computer: gps road match";
CM_ SG_ 568 UI_navRouteActive "Navigation route is active";
CM_ SG_ 568 UI_parallelAutoparkEnabled "Autopilot map parallel park enabled.";
CM_ SG_ 568 UI_perpendicularAutoparkEnabled "Autopilot map perpendicular park enabled.";
CM_ SG_ 568 UI_nextBranchDist "Touchscreen user interface computer: next branch dist; raw 31 = signal not available (SNA)";
CM_ SG_ 568 UI_controlledAccess "DAS map controlled access segment.";
CM_ SG_ 568 UI_nextBranchLeftOffRamp "Touchscreen user interface computer: next branch left off ramp";
CM_ SG_ 568 UI_nextBranchRightOffRamp "Touchscreen user interface computer: next branch right off ramp";
CM_ SG_ 568 UI_rejectLeftLane "Touchscreen user interface computer: reject left lane";
CM_ SG_ 568 UI_rejectRightLane "Touchscreen user interface computer: reject right lane";
CM_ SG_ 568 UI_rejectHPP "Touchscreen user interface computer: reject HPP";
CM_ SG_ 568 UI_rejectNav "Touchscreen user interface computer: reject nav";
CM_ SG_ 568 UI_rejectLeftFreeSpace "Touchscreen user interface computer: reject left free space";
CM_ SG_ 568 UI_rejectRightFreeSpace "Touchscreen user interface computer: reject right free space";
CM_ SG_ 568 UI_rejectAutosteer "Touchscreen user interface computer: reject autosteer";
CM_ SG_ 568 UI_rejectHandsOn "Touchscreen user interface computer: reject hands on";
CM_ SG_ 568 UI_acceptBottsDots "Touchscreen user interface computer: accept botts dots";
CM_ SG_ 568 UI_autosteerRestricted "Autopilot map is autostreer restricted.";
CM_ SG_ 568 UI_pmmEnabled "Touchscreen user interface computer: pmm enabled";
CM_ SG_ 568 UI_scaEnabled "Touchscreen user interface computer: sca enabled";
CM_ SG_ 568 UI_mapDataCounter "Touchscreen user interface computer: map data counter";
CM_ SG_ 568 UI_mapDataChecksum "Touchscreen user interface computer: map data checksum";
CM_ BO_ 536 "Touchscreen user interface computer message: driver assist road sign; forwarded onto this bus by the gateway";
CM_ SG_ 536 UI_roadSign "Touchscreen user interface computer: road sign; raw 255 = signal not available (SNA)";
CM_ SG_ 536 UI_splineLocConfidence "Touchscreen user interface computer: spline loc confidence; raw 0 = signal not available (SNA)";
CM_ SG_ 536 UI_splineID "Touchscreen user interface computer: spline ID";
CM_ SG_ 536 UI_roadSignCounter "Touchscreen user interface computer: road sign counter";
CM_ SG_ 536 UI_roadSignChecksum "Touchscreen user interface computer: road sign checksum";
CM_ SG_ 536 UI_dummyData "Touchscreen user interface computer: dummy data";
CM_ SG_ 536 UI_stopSignStopLineDist "Touchscreen user interface computer: stop sign stop line dist; raw 1023 = signal not available (SNA)";
CM_ SG_ 536 UI_stopSignStopLineConf "Touchscreen user interface computer: stop sign stop line conf; raw 0 = signal not available (SNA)";
CM_ SG_ 536 UI_trafficLightStopLineDist "Touchscreen user interface computer: traffic light stop line dist; raw 1023 = signal not available (SNA)";
CM_ SG_ 536 UI_trafficLightStopLineConf "Touchscreen user interface computer: traffic light stop line conf; raw 0 = signal not available (SNA)";
CM_ SG_ 536 UI_baseMapSpeedLimitMPS "Touchscreen user interface computer: base map speed limit MPS; raw 255 = signal not available (SNA)";
CM_ SG_ 536 UI_bottomQrtlFleetSpeedMPS "Touchscreen user interface computer: bottom qrtl fleet speed MPS; raw 255 = signal not available (SNA)";
CM_ SG_ 536 UI_topQrtlFleetSpeedMPS "Touchscreen user interface computer: top qrtl fleet speed MPS; raw 255 = signal not available (SNA)";
CM_ SG_ 536 UI_meanFleetSplineSpeedMPS "Touchscreen user interface computer: mean fleet spline speed MPS; raw 255 = signal not available (SNA)";
CM_ SG_ 536 UI_medianFleetSpeedMPS "Touchscreen user interface computer: median fleet speed MPS; raw 255 = signal not available (SNA)";
CM_ SG_ 536 UI_meanFleetSplineAccelMPS2 "Touchscreen user interface computer: mean fleet spline accel MPS2; raw 255 = signal not available (SNA)";
CM_ SG_ 536 UI_rampType "Touchscreen user interface computer: ramp type; raw 0 = signal not available (SNA)";
CM_ SG_ 536 UI_valhallaRamp "Touchscreen user interface computer: valhalla ramp; raw 0 = signal not available (SNA)";
CM_ SG_ 536 UI_overrideACMFleetSpeed "Touchscreen user interface computer: override ACM fleet speed";
CM_ SG_ 536 UI_currSplineIdFull "Touchscreen user interface computer: curr spline id full; raw 0 = signal not available (SNA)";
CM_ BO_ 1971 "Touchscreen user interface computer message: dynamic triggers campaign fired; forwarded onto this bus by the gateway";
CM_ SG_ 1971 UI_campaignFired "Touchscreen user interface computer: campaign fired";
CM_ BO_ 760 "Touchscreen user interface computer message: gps vehicle speed; forwarded onto this bus by the gateway";
CM_ SG_ 760 UI_gpsHDOP "Touchscreen user interface computer: gps HDOP";
CM_ SG_ 760 UI_gpsVehicleHeading "Touchscreen user interface computer: gps vehicle heading";
CM_ SG_ 760 UI_gpsVehicleSpeed "Touchscreen user interface computer: gps vehicle speed";
CM_ SG_ 760 UI_userSpeedOffset "Touchscreen user interface computer: user speed offset";
CM_ SG_ 760 UI_mapSpeedLimitUnits "Autopilot map speed limit units.";
CM_ SG_ 760 UI_userSpeedOffsetUnits "Touchscreen user interface computer: user speed offset units";
CM_ SG_ 760 UI_mppSpeedLimit "Autopilot map speed limit";
CM_ SG_ 760 UI_gpsNmeaMIA "GPS NMEA data MIA";
CM_ SG_ 760 UI_gpsAntennaDisconnected "GPS antenna state";
CM_ SG_ 760 UI_conditionalLimitActive "Conditional speed limit condition is currently active";
CM_ SG_ 760 UI_conditionalSpeedLimit "Conditional speed limit value; raw 31 = signal not available (SNA)";
CM_ BO_ 985 "Touchscreen user interface computer message: location offset; forwarded onto this bus by the gateway";
CM_ SG_ 985 UI_latitudeOffset "Touchscreen user interface computer: latitude offset";
CM_ SG_ 985 UI_longitudeOffset "Touchscreen user interface computer: longitude offset";
CM_ BO_ 777 "Touchscreen user interface computer message: location status; forwarded onto this bus by the gateway";
CM_ SG_ 777 UI_latitude "Touchscreen user interface computer: latitude";
CM_ SG_ 777 UI_longitude "Touchscreen user interface computer: longitude";
CM_ SG_ 777 UI_gpsAccuracy "Touchscreen user interface computer: gps accuracy; raw 127 = signal not available (SNA)";
CM_ BO_ 1011 "Touchscreen user interface computer message: odo; forwarded onto this bus by the gateway";
CM_ SG_ 1011 UI_odometer "Odometer; raw 16777215 = signal not available (SNA)";
CM_ BO_ 987 "Touchscreen user interface computer message: phone location status; forwarded onto this bus by the gateway";
CM_ SG_ 987 UI_phoneLatitude "Touchscreen user interface computer: phone latitude";
CM_ SG_ 987 UI_phoneLongitude "Touchscreen user interface computer: phone longitude";
CM_ SG_ 987 UI_phoneGpsAccuracy "Touchscreen user interface computer: phone gps accuracy; raw 127 = signal not available (SNA)";
CM_ BO_ 820 "Touchscreen user interface computer message: powertrain control; forwarded onto this bus by the gateway";
CM_ SG_ 820 UI_systemPowerLimit "Touchscreen user interface computer: system power limit; raw 31 = signal not available (SNA)";
CM_ SG_ 820 UI_pedalMap "Switch between various platform specific pedal maps";
CM_ SG_ 820 UI_enableRegenBackfill "Indicates if regenerative braking backfill has been enabled by the driver";
CM_ SG_ 820 UI_systemTorqueLimit "Touchscreen user interface computer: system torque limit; raw 63 = signal not available (SNA)";
CM_ SG_ 820 UI_closureConfirmed "Touchscreen user interface computer: closure confirmed";
CM_ SG_ 820 UI_regenTorqueMax "Maximum regen torque from UI - reports different value when in track mode";
CM_ SG_ 820 UI_limitMode "Commands limited drive inverter capabilities based on special vehicle modes";
CM_ SG_ 820 UI_factoryCustomerDrivingModeReq "Touchscreen user interface computer: factory customer driving mode request";
CM_ SG_ 820 UI_motorOnMode "Request from the UI to selectively enable or disable a drive unit (dev-only)";
CM_ SG_ 820 UI_stoppingMode "Low-speed behavior when no pedal is pressed (stopping/rolling/creeping)";
CM_ SG_ 820 UI_DIAppSliderDebug "Touchscreen user interface computer: DI app slider debug";
CM_ SG_ 820 UI_speedLimit "Maximum allowed speed enforced at vehicle level.; raw 511 = signal not available (SNA)";
CM_ SG_ 820 UI_enableSmartShift "Stalkless convenience feature that allows unparking with only a firm press of brake pedal";
CM_ SG_ 820 UI_navVehParallelToRdCanContinue "Whether the vehicle is parallel parked on a public road; raw 0 = signal not available (SNA)";
CM_ SG_ 820 UI_powertrainControlCounter "Touchscreen user interface computer: powertrain control counter";
CM_ SG_ 820 UI_powertrainControlChecksum "Touchscreen user interface computer: powertrain control checksum";
CM_ BO_ 698 "Touchscreen user interface computer message: radar map data; forwarded onto this bus by the gateway";
CM_ SG_ 698 UI_radarTargetDx "Touchscreen user interface computer: radar target dx";
CM_ SG_ 698 UI_radarTargetDxEnd "Touchscreen user interface computer: radar target dx end";
CM_ SG_ 698 UI_radarTargetTrustMap "Touchscreen user interface computer: radar target trust map";
CM_ SG_ 698 UI_radarEnableBraking "Touchscreen user interface computer: radar enable braking";
CM_ SG_ 698 UI_radarMapDataCounter "Touchscreen user interface computer: radar map data counter";
CM_ SG_ 698 UI_radarMapDataChecksum "Touchscreen user interface computer: radar map data checksum";
CM_ BO_ 632 "Touchscreen user interface computer message: road curvature; forwarded onto this bus by the gateway";
CM_ SG_ 632 UI_roadCurvC0 "Touchscreen user interface computer: road curv C0";
CM_ SG_ 632 UI_roadCurvC1 "Touchscreen user interface computer: road curv C1";
CM_ SG_ 632 UI_roadCurvC2 "Touchscreen user interface computer: road curv C2";
CM_ SG_ 632 UI_roadCurvC3 "Touchscreen user interface computer: road curv C3";
CM_ SG_ 632 UI_roadCurvRange "Touchscreen user interface computer: road curv range";
CM_ SG_ 632 UI_roadCurvHealth "Touchscreen user interface computer: road curv health";
CM_ SG_ 632 UI_roadCurvChecksum "Touchscreen user interface computer: road curv checksum";
CM_ BO_ 723 "Touchscreen user interface computer message: solar data; forwarded onto this bus by the gateway";
CM_ SG_ 723 UI_solarAzimuthAngle "Touchscreen user interface computer: solar azimuth angle; raw 32768 = signal not available (SNA)";
CM_ SG_ 723 UI_solarAzimuthAngleCarRef "Touchscreen user interface computer: solar azimuth angle car ref; raw 255 = signal not available (SNA)";
CM_ SG_ 723 UI_isSunUp "is sun up; raw 3 = signal not available (SNA)";
CM_ SG_ 723 UI_solarElevationAngle "Solar Elevation Angle; raw 127 = signal not available (SNA)";
CM_ SG_ 723 UI_screenPCBTemperature "Temperature of display PCB";
CM_ SG_ 723 UI_minsToSunset "time until to sunset";
CM_ SG_ 723 UI_minsToSunrise "time until to sunrise";
CM_ BO_ 851 "Touchscreen user interface computer message: status; forwarded onto this bus by the gateway";
CM_ SG_ 851 UI_touchActive "No touchscreen errors";
CM_ SG_ 851 UI_audioActive "Audio system is ready.";
CM_ SG_ 851 UI_bluetoothActive "Touchscreen user interface computer: bluetooth active";
CM_ SG_ 851 UI_cellActive "Cell is powered";
CM_ SG_ 851 UI_displayReady "UI is ready (GUI_allReady) and display is ok (GUI_displayHardwareOK)";
CM_ SG_ 851 UI_displayOn "UI display on/off status";
CM_ SG_ 851 UI_wifiActive "WiFi active.";
CM_ SG_ 851 UI_wifiConnected "WiFi Connected.";
CM_ SG_ 851 UI_systemActive "Touchscreen user interface computer: system active";
CM_ SG_ 851 UI_readyForDrive "Ready for drive (UI ready or self park request)";
CM_ SG_ 851 UI_cellConnected "Detects if the cell is connected to a network.";
CM_ SG_ 851 UI_vpnActive "VPN connected.";
CM_ SG_ 851 UI_autopilotTrial "Touchscreen user interface computer: autopilot trial";
CM_ SG_ 851 UI_factoryReset "UI request for factory reset; raw 0 = signal not available (SNA)";
CM_ SG_ 851 UI_gpsActive "GPS has valid fix";
CM_ SG_ 851 UI_screenshotActive "Touchscreen user interface computer: screenshot active";
CM_ SG_ 851 UI_radioActive "Touchscreen user interface computer: radio active";
CM_ SG_ 851 UI_cellNetworkTechnology "Describes the type of cellular network to which the car computer is connected: GPRS_2G(114Kbps) < EGDE_2G(368Kbps) < 3G(3Mbps) < HSDPA_3G(14Mbps) < HSPAplus_4Gg(168Mbps) < 4G_LTE(299Mbps); raw 15 = signal not available (SNA)";
CM_ SG_ 851 UI_cellReceiverPower "Touchscreen user interface computer: cell receiver power";
CM_ SG_ 851 UI_falseTouchCounter "Count false touches after display is off.";
CM_ SG_ 851 UI_developmentCar "Touchscreen user interface computer: development car";
CM_ SG_ 851 UI_cameraActive "Touchscreen user interface computer: camera active";
CM_ SG_ 851 UI_cellSignalBars "Number of cellular signal bars displayed on the UI, derived from cellSignalStrength; raw 7 = signal not available (SNA)";
CM_ SG_ 851 UI_trailerModeTelltale "Color of the trailer mode telltale";
CM_ SG_ 851 UI_pcbTemperature "PCB digital temp sensor reading in DegC";
CM_ SG_ 851 UI_cpuTemperature "Apollo Lake SOC temperature in DegC";
CM_ BO_ 991 "Touchscreen user interface computer message: status2; forwarded onto this bus by the gateway";
CM_ SG_ 991 UI_mobileAppStepCount "Touchscreen user interface computer: mobile app step count";
CM_ SG_ 991 UI_userRequestSnapshot "Touchscreen user interface computer: user request snapshot";
CM_ SG_ 991 UI_touchDetected "Touchscreen user interface computer: touch detected";
CM_ SG_ 991 UI_validDeviceForEUSummon "Touchscreen user interface computer: valid device for EU summon";
CM_ SG_ 991 UI_locatedAtHome "Touchscreen user interface computer: located at home";
CM_ SG_ 991 UI_locatedAtWork "Touchscreen user interface computer: located at work";
CM_ SG_ 991 UI_locatedAtFavorite "Touchscreen user interface computer: located at favorite";
CM_ SG_ 991 UI_displayInDarkMode "Touchscreen user interface computer: display in dark mode";
CM_ SG_ 991 UI_userActivity "Indicates user interaction with the center display";
CM_ SG_ 991 UI_activeTouchPoints "Quantity of active touch points on the Center Display";
CM_ SG_ 991 UI_linkState "Connectivity link state";
CM_ SG_ 991 UI_sentryModeState "Touchscreen user interface computer: sentry mode state; raw 6 = signal not available (SNA)";
CM_ SG_ 991 UI_autopilotSentryRequest "whether AP sentry mode should be enabled";
CM_ SG_ 991 UI_mobileAppConnected "Reports if Web Real-Time Communication (WebRTC) connection is connected while summon screen is open on the mobile app.";
CM_ SG_ 991 UI_phoneLeftInCabin "Used for monitoring phone left behind feature";
CM_ SG_ 991 UI_autoshiftDRState "Reports the User Interface (UI) autoshift Drive/Reverse state.";
CM_ SG_ 991 UI_wifiBtModuleType "Reports the type of Wi-Fi and Bluetooth (BT) module.";
CM_ SG_ 991 UI_sohHealthStatus "Touchscreen user interface computer: soh health status";
CM_ SG_ 991 UI_selfParkState "Reports the auto park state changes.; raw 255 = signal not available (SNA)";
CM_ SG_ 991 UI_summonDeviceIndex "Reports which device is being used to control summon.";
CM_ SG_ 991 UI_fullScreenMode "Aggregates all situations with which the UI is using the entire screen so stalkless gear controls are not present";
CM_ SG_ 991 UI_sentryModeCameraDetection "Touchscreen user interface computer: sentry mode camera detection";
CM_ SG_ 991 UI_wakeOnIPActive "Touchscreen user interface computer: wake on IP active";
CM_ SG_ 991 UI_sapActive "Touchscreen user interface computer: sap active";
CM_ SG_ 991 UI_sapClients "Touchscreen user interface computer: sap clients";
CM_ SG_ 991 UI_connectivityStandbyActive "Touchscreen user interface computer: connectivity standby active";
CM_ BO_ 988 "Touchscreen user interface computer message: summon goal; forwarded onto this bus by the gateway";
CM_ SG_ 988 UI_goalLatitude "Touchscreen user interface computer: goal latitude";
CM_ SG_ 988 UI_goalLongitude "Touchscreen user interface computer: goal longitude";
CM_ SG_ 988 UI_goalOrientation "Touchscreen user interface computer: goal orientation";
CM_ BO_ 1064 "Touchscreen user interface computer message: telemetry control; forwarded onto this bus by the gateway";
CM_ SG_ 1064 UI_TCR_enable "Touchscreen user interface computer: TCR enable";
CM_ SG_ 1064 UI_TCR_moveStateStanding "Touchscreen user interface computer: TCR move state standing";
CM_ SG_ 1064 UI_TCR_moveStateStopped "Touchscreen user interface computer: TCR move state stopped";
CM_ SG_ 1064 UI_TCR_moveStateMoving "Touchscreen user interface computer: TCR move state moving";
CM_ SG_ 1064 UI_TCR_moveStateIndeterm "Touchscreen user interface computer: TCR move state indeterm";
CM_ SG_ 1064 UI_TCR_classConstElem "Touchscreen user interface computer: TCR class const elem";
CM_ SG_ 1064 UI_TCR_classMovingPed "Touchscreen user interface computer: TCR class moving ped";
CM_ SG_ 1064 UI_TCR_classMovingTwoWheel "Touchscreen user interface computer: TCR class moving two wheel";
CM_ SG_ 1064 UI_TCR_classMovingFourWheel "Touchscreen user interface computer: TCR class moving four wheel";
CM_ SG_ 1064 UI_TCR_classUnknown "Touchscreen user interface computer: TCR class unknown";
CM_ SG_ 1064 UI_TCR_downSampleFactor "Touchscreen user interface computer: TCR down sample factor";
CM_ SG_ 1064 UI_TCR_wExist "Touchscreen user interface computer: TCR w exist";
CM_ SG_ 1064 UI_TCR_vehSpeed "Touchscreen user interface computer: TCR veh speed";
CM_ SG_ 1064 UI_TCR_minRCS "Touchscreen user interface computer: TCR min RCS";
CM_ SG_ 1064 UI_TCR_maxDy "Touchscreen user interface computer: TCR max dy";
CM_ SG_ 1064 UI_TCR_maxObjects "Touchscreen user interface computer: TCR max objects";
CM_ SG_ 1064 UI_TCR_maxRoadClass "Touchscreen user interface computer: TCR max road class";
CM_ BO_ 856 "Touchscreen user interface computer message: tpms mode; forwarded onto this bus by the gateway";
CM_ SG_ 856 UI_TPMSMode "Touchscreen user interface computer: TPMS mode";
CM_ SG_ 856 UI_TPMSLearnIDMode "Touchscreen user interface computer: TPMS learn ID mode";
CM_ SG_ 856 UI_sizeOfWheelSelect "Touchscreen user interface computer: size of wheel select";
CM_ SG_ 856 UI_sizeOfReqCANAutoLearn "Touchscreen user interface computer: size of req CAN auto learn";
CM_ BO_ 952 "Touchscreen user interface computer message: tpms RC psetting; forwarded onto this bus by the gateway";
CM_ SG_ 952 UI_sendCalibrateTireRequest "Reports UI requests for PMDI to start the tire pressure calibration routine.";
CM_ SG_ 952 UI_setRCPFront "Touchscreen user interface computer: set RCP front";
CM_ SG_ 952 UI_setRCPRear "Touchscreen user interface computer: set RCP rear";
BA_DEF_ BO_ "GenMsgCycleTime" INT 0 3600000;
BA_DEF_ BO_ "GenMsgSendType" ENUM "Cyclic","NotUsed","NotUsed","NotUsed","NotUsed","NotUsed","NotUsed","IfActive","NoMsgSendType","NotUsed";
BA_DEF_ BO_ "VFrameFormat" ENUM "StandardCAN","ExtendedCAN","reserved","J1939PG","reserved","reserved","reserved","reserved","reserved","reserved","reserved","reserved","reserved","reserved","StandardCAN_FD","ExtendedCAN_FD";
BA_DEF_ BO_ "CANFD_BRS" ENUM "0","1";
BA_DEF_ SG_ "GenSigSNA" STRING;
BA_DEF_ SG_ "SystemSignalLongSymbol" STRING;
BA_DEF_ SG_ "Confidence" ENUM "validated","plausible","layout-only","contradicted";
BA_DEF_DEF_ "GenMsgCycleTime" 0;
BA_DEF_DEF_ "GenMsgSendType" "NoMsgSendType";
BA_DEF_DEF_ "VFrameFormat" "StandardCAN";
BA_DEF_DEF_ "CANFD_BRS" "1";
BA_DEF_DEF_ "GenSigSNA" "";
BA_DEF_DEF_ "SystemSignalLongSymbol" "";
BA_DEF_DEF_ "Confidence" "layout-only";
BA_ "GenMsgCycleTime" BO_ 882 100;
BA_ "GenMsgSendType" BO_ 882 0;
BA_ "GenMsgCycleTime" BO_ 850 1000;
BA_ "GenMsgSendType" BO_ 850 0;
BA_ "GenMsgCycleTime" BO_ 1021 500;
BA_ "GenMsgSendType" BO_ 1021 0;
BA_ "GenMsgCycleTime" BO_ 659 500;
BA_ "GenMsgSendType" BO_ 659 0;
BA_ "GenMsgCycleTime" BO_ 664 500;
BA_ "GenMsgSendType" BO_ 664 0;
BA_ "GenMsgCycleTime" BO_ 679 500;
BA_ "GenMsgSendType" BO_ 679 0;
BA_ "GenMsgCycleTime" BO_ 1096 1000;
BA_ "GenMsgSendType" BO_ 1096 0;
BA_ "GenMsgCycleTime" BO_ 1016 1000;
BA_ "GenMsgSendType" BO_ 1016 0;
BA_ "GenMsgCycleTime" BO_ 568 500;
BA_ "GenMsgSendType" BO_ 568 0;
BA_ "GenMsgCycleTime" BO_ 536 500;
BA_ "GenMsgSendType" BO_ 536 0;
BA_ "GenMsgCycleTime" BO_ 1971 500;
BA_ "GenMsgSendType" BO_ 1971 0;
BA_ "GenMsgCycleTime" BO_ 760 1000;
BA_ "GenMsgSendType" BO_ 760 0;
BA_ "GenMsgCycleTime" BO_ 985 1000;
BA_ "GenMsgSendType" BO_ 985 0;
BA_ "GenMsgCycleTime" BO_ 777 1000;
BA_ "GenMsgSendType" BO_ 777 0;
BA_ "GenMsgCycleTime" BO_ 1011 1000;
BA_ "GenMsgSendType" BO_ 1011 0;
BA_ "GenMsgCycleTime" BO_ 987 1000;
BA_ "GenMsgSendType" BO_ 987 0;
BA_ "GenMsgCycleTime" BO_ 820 500;
BA_ "GenMsgSendType" BO_ 820 0;
BA_ "GenMsgCycleTime" BO_ 698 500;
BA_ "GenMsgSendType" BO_ 698 0;
BA_ "GenMsgCycleTime" BO_ 632 500;
BA_ "GenMsgSendType" BO_ 632 0;
BA_ "GenMsgCycleTime" BO_ 723 1000;
BA_ "GenMsgSendType" BO_ 723 0;
BA_ "GenMsgCycleTime" BO_ 851 500;
BA_ "GenMsgSendType" BO_ 851 0;
BA_ "GenMsgCycleTime" BO_ 991 500;
BA_ "GenMsgSendType" BO_ 991 0;
BA_ "GenMsgCycleTime" BO_ 988 1000;
BA_ "GenMsgSendType" BO_ 988 0;
BA_ "GenMsgCycleTime" BO_ 1064 1000;
BA_ "GenMsgSendType" BO_ 1064 0;
BA_ "GenMsgCycleTime" BO_ 952 1000;
BA_ "GenMsgSendType" BO_ 952 0;
BA_ "Confidence" SG_ 882 TRCM_matrixIndex 1;
BA_ "SystemSignalLongSymbol" SG_ 882 TRCM_a012_asm5TemperatureOutside "TRCM_a012_asm5TemperatureOutsideSignalRange";
BA_ "SystemSignalLongSymbol" SG_ 882 TRCM_a014_asm3TemperatureOutside "TRCM_a014_asm3TemperatureOutsideSignalRange";
BA_ "SystemSignalLongSymbol" SG_ 882 TRCM_a017_asm5TemperatureOutside "TRCM_a017_asm5TemperatureOutsideOperatingRange";
BA_ "SystemSignalLongSymbol" SG_ 882 TRCM_a018_asm3TemperatureOutside "TRCM_a018_asm3TemperatureOutsideOperatingRange";
BA_ "SystemSignalLongSymbol" SG_ 882 TRCM_a026_airbagAsicDiagnosticFa "TRCM_a026_airbagAsicDiagnosticFault";
BA_ "SystemSignalLongSymbol" SG_ 882 TRCM_a027_airbagAsicDeploymentDi "TRCM_a027_airbagAsicDeploymentDiagnosticFault";
BA_ "SystemSignalLongSymbol" SG_ 882 TRCM_a074_ais2120SelfTestXPositi "TRCM_a074_ais2120SelfTestXPositiveFailed";
BA_ "SystemSignalLongSymbol" SG_ 882 TRCM_a075_ais2120SelfTestXNegati "TRCM_a075_ais2120SelfTestXNegativeFailed";
BA_ "SystemSignalLongSymbol" SG_ 882 TRCM_a076_ais2120SelfTestYPositi "TRCM_a076_ais2120SelfTestYPositiveFailed";
BA_ "SystemSignalLongSymbol" SG_ 882 TRCM_a077_ais2120SelfTestYNegati "TRCM_a077_ais2120SelfTestYNegativeFailed";
BA_ "SystemSignalLongSymbol" SG_ 882 TRCM_a121_buckleStatusFrontLeftS "TRCM_a121_buckleStatusFrontLeftSignalNotOkay";
BA_ "SystemSignalLongSymbol" SG_ 882 TRCM_a122_buckleStatusFrontRight "TRCM_a122_buckleStatusFrontRightSignalNotOkay";
BA_ "SystemSignalLongSymbol" SG_ 882 TRCM_a123_buckleStatusRearLeftSi "TRCM_a123_buckleStatusRearLeftSignalNotOkay";
BA_ "SystemSignalLongSymbol" SG_ 882 TRCM_a124_buckleStatusRearRightS "TRCM_a124_buckleStatusRearRightSignalNotOkay";
BA_ "SystemSignalLongSymbol" SG_ 882 TRCM_a125_occupantClassification "TRCM_a125_occupantClassificationSignalNotOkay";
BA_ "SystemSignalLongSymbol" SG_ 882 TRCM_a126_seatTrackPositionLeftS "TRCM_a126_seatTrackPositionLeftSignalNotOkay";
BA_ "SystemSignalLongSymbol" SG_ 882 TRCM_a127_seatTrackPositionRight "TRCM_a127_seatTrackPositionRightSignalNotOkay";
BA_ "SystemSignalLongSymbol" SG_ 882 TRCM_a137_ext1AsicSnoopTestFaile "TRCM_a137_ext1AsicSnoopTestFailed";
BA_ "SystemSignalLongSymbol" SG_ 882 TRCM_a138_ext2AsicSnoopTestFaile "TRCM_a138_ext2AsicSnoopTestFailed";
BA_ "SystemSignalLongSymbol" SG_ 882 TRCM_a145_frontCenterAccelReport "TRCM_a145_frontCenterAccelReportedError";
BA_ "SystemSignalLongSymbol" SG_ 882 TRCM_a146_frontCenterAccelGenera "TRCM_a146_frontCenterAccelGeneralIssue";
BA_ "SystemSignalLongSymbol" SG_ 882 TRCM_a147_frontCenterAccelElectr "TRCM_a147_frontCenterAccelElectricalIssue";
BA_ "SystemSignalLongSymbol" SG_ 882 TRCM_a148_frontCenterAccelConfig "TRCM_a148_frontCenterAccelConfigError";
BA_ "SystemSignalLongSymbol" SG_ 882 TRCM_a149_frontCenterAccelSignal "TRCM_a149_frontCenterAccelSignalMonitor";
BA_ "SystemSignalLongSymbol" SG_ 882 TRCM_a150_frontLeftAccelReported "TRCM_a150_frontLeftAccelReportedError";
BA_ "SystemSignalLongSymbol" SG_ 882 TRCM_a151_frontLeftAccelGeneralI "TRCM_a151_frontLeftAccelGeneralIssue";
BA_ "SystemSignalLongSymbol" SG_ 882 TRCM_a152_frontLeftAccelElectric "TRCM_a152_frontLeftAccelElectricalIssue";
BA_ "SystemSignalLongSymbol" SG_ 882 TRCM_a153_frontLeftAccelConfigEr "TRCM_a153_frontLeftAccelConfigError";
BA_ "SystemSignalLongSymbol" SG_ 882 TRCM_a154_frontLeftAccelSignalMo "TRCM_a154_frontLeftAccelSignalMonitor";
BA_ "SystemSignalLongSymbol" SG_ 882 TRCM_a155_frontLeftDoorPressureR "TRCM_a155_frontLeftDoorPressureReportedError";
BA_ "SystemSignalLongSymbol" SG_ 882 TRCM_a156_frontLeftDoorPressureG "TRCM_a156_frontLeftDoorPressureGeneralIssue";
BA_ "SystemSignalLongSymbol" SG_ 882 TRCM_a157_frontLeftDoorPressureE "TRCM_a157_frontLeftDoorPressureElectricalIssue";
BA_ "SystemSignalLongSymbol" SG_ 882 TRCM_a158_frontLeftDoorPressureC "TRCM_a158_frontLeftDoorPressureConfigError";
BA_ "SystemSignalLongSymbol" SG_ 882 TRCM_a159_frontLeftDoorPressureS "TRCM_a159_frontLeftDoorPressureSignalMonitor";
BA_ "SystemSignalLongSymbol" SG_ 882 TRCM_a160_frontRightAccelReporte "TRCM_a160_frontRightAccelReportedError";
BA_ "SystemSignalLongSymbol" SG_ 882 TRCM_a161_frontRightAccelGeneral "TRCM_a161_frontRightAccelGeneralIssue";
BA_ "SystemSignalLongSymbol" SG_ 882 TRCM_a162_frontRightAccelElectri "TRCM_a162_frontRightAccelElectricalIssue";
BA_ "SystemSignalLongSymbol" SG_ 882 TRCM_a163_frontRightAccelConfigE "TRCM_a163_frontRightAccelConfigError";
BA_ "SystemSignalLongSymbol" SG_ 882 TRCM_a164_frontRightAccelSignalM "TRCM_a164_frontRightAccelSignalMonitor";
BA_ "SystemSignalLongSymbol" SG_ 882 TRCM_a165_frontRightDoorPressure "TRCM_a165_frontRightDoorPressureReportedError";
BA_ "SystemSignalLongSymbol" SG_ 882 TRCM_a166_frontRightDoorPressure "TRCM_a166_frontRightDoorPressureGeneralIssue";
BA_ "SystemSignalLongSymbol" SG_ 882 TRCM_a167_frontRightDoorPressure "TRCM_a167_frontRightDoorPressureElectricalIssue";
BA_ "SystemSignalLongSymbol" SG_ 882 TRCM_a168_frontRightDoorPressure "TRCM_a168_frontRightDoorPressureConfigError";
BA_ "SystemSignalLongSymbol" SG_ 882 TRCM_a169_frontRightDoorPressure "TRCM_a169_frontRightDoorPressureSignalMonitor";
BA_ "SystemSignalLongSymbol" SG_ 882 TRCM_a170_leftBPillarAccelReport "TRCM_a170_leftBPillarAccelReportedError";
BA_ "SystemSignalLongSymbol" SG_ 882 TRCM_a171_leftBPillarAccelGenera "TRCM_a171_leftBPillarAccelGeneralIssue";
BA_ "SystemSignalLongSymbol" SG_ 882 TRCM_a172_leftBPillarAccelElectr "TRCM_a172_leftBPillarAccelElectricalIssue";
BA_ "SystemSignalLongSymbol" SG_ 882 TRCM_a173_leftBPillarAccelConfig "TRCM_a173_leftBPillarAccelConfigError";
BA_ "SystemSignalLongSymbol" SG_ 882 TRCM_a174_leftBPillarAccelSignal "TRCM_a174_leftBPillarAccelSignalMonitor";
BA_ "SystemSignalLongSymbol" SG_ 882 TRCM_a175_leftCPillarAccelReport "TRCM_a175_leftCPillarAccelReportedError";
BA_ "SystemSignalLongSymbol" SG_ 882 TRCM_a176_leftCPillarAccelGenera "TRCM_a176_leftCPillarAccelGeneralIssue";
BA_ "SystemSignalLongSymbol" SG_ 882 TRCM_a177_leftCPillarAccelElectr "TRCM_a177_leftCPillarAccelElectricalIssue";
BA_ "SystemSignalLongSymbol" SG_ 882 TRCM_a178_leftCPillarAccelConfig "TRCM_a178_leftCPillarAccelConfigError";
BA_ "SystemSignalLongSymbol" SG_ 882 TRCM_a179_leftCPillarAccelSignal "TRCM_a179_leftCPillarAccelSignalMonitor";
BA_ "SystemSignalLongSymbol" SG_ 882 TRCM_a190_rearLeftDoorPressureRe "TRCM_a190_rearLeftDoorPressureReportedError";
BA_ "SystemSignalLongSymbol" SG_ 882 TRCM_a191_rearLeftDoorPressureGe "TRCM_a191_rearLeftDoorPressureGeneralIssue";
BA_ "SystemSignalLongSymbol" SG_ 882 TRCM_a192_rearLeftDoorPressureEl "TRCM_a192_rearLeftDoorPressureElectricalIssue";
BA_ "SystemSignalLongSymbol" SG_ 882 TRCM_a193_rearLeftDoorPressureCo "TRCM_a193_rearLeftDoorPressureConfigError";
BA_ "SystemSignalLongSymbol" SG_ 882 TRCM_a194_rearLeftDoorPressureSi "TRCM_a194_rearLeftDoorPressureSignalMonitor";
BA_ "SystemSignalLongSymbol" SG_ 882 TRCM_a195_rearRightDoorPressureR "TRCM_a195_rearRightDoorPressureReportedError";
BA_ "SystemSignalLongSymbol" SG_ 882 TRCM_a196_rearRightDoorPressureG "TRCM_a196_rearRightDoorPressureGeneralIssue";
BA_ "SystemSignalLongSymbol" SG_ 882 TRCM_a197_rearRightDoorPressureE "TRCM_a197_rearRightDoorPressureElectricalIssue";
BA_ "SystemSignalLongSymbol" SG_ 882 TRCM_a198_rearRightDoorPressureC "TRCM_a198_rearRightDoorPressureConfigError";
BA_ "SystemSignalLongSymbol" SG_ 882 TRCM_a199_rearRightDoorPressureS "TRCM_a199_rearRightDoorPressureSignalMonitor";
BA_ "SystemSignalLongSymbol" SG_ 882 TRCM_a200_rightBPillarAccelRepor "TRCM_a200_rightBPillarAccelReportedError";
BA_ "SystemSignalLongSymbol" SG_ 882 TRCM_a201_rightBPillarAccelGener "TRCM_a201_rightBPillarAccelGeneralIssue";
BA_ "SystemSignalLongSymbol" SG_ 882 TRCM_a202_rightBPillarAccelElect "TRCM_a202_rightBPillarAccelElectricalIssue";
BA_ "SystemSignalLongSymbol" SG_ 882 TRCM_a203_rightBPillarAccelConfi "TRCM_a203_rightBPillarAccelConfigError";
BA_ "SystemSignalLongSymbol" SG_ 882 TRCM_a204_rightBPillarAccelSigna "TRCM_a204_rightBPillarAccelSignalMonitor";
BA_ "SystemSignalLongSymbol" SG_ 882 TRCM_a205_rightCPillarAccelRepor "TRCM_a205_rightCPillarAccelReportedError";
BA_ "SystemSignalLongSymbol" SG_ 882 TRCM_a206_rightCPillarAccelGener "TRCM_a206_rightCPillarAccelGeneralIssue";
BA_ "SystemSignalLongSymbol" SG_ 882 TRCM_a207_rightCPillarAccelElect "TRCM_a207_rightCPillarAccelElectricalIssue";
BA_ "SystemSignalLongSymbol" SG_ 882 TRCM_a208_rightCPillarAccelConfi "TRCM_a208_rightCPillarAccelConfigError";
BA_ "SystemSignalLongSymbol" SG_ 882 TRCM_a209_rightCPillarAccelSigna "TRCM_a209_rightCPillarAccelSignalMonitor";
BA_ "SystemSignalLongSymbol" SG_ 882 TRCM_a300_driverAirbagStage1Supp "TRCM_a300_driverAirbagStage1Suppressed";
BA_ "SystemSignalLongSymbol" SG_ 882 TRCM_a301_passengerAirbagStage1S "TRCM_a301_passengerAirbagStage1Suppressed";
BA_ "SystemSignalLongSymbol" SG_ 882 TRCM_a302_driverAirbagStage2Supp "TRCM_a302_driverAirbagStage2Suppressed";
BA_ "SystemSignalLongSymbol" SG_ 882 TRCM_a303_driverAirbagActiveVent "TRCM_a303_driverAirbagActiveVentSuppressed";
BA_ "SystemSignalLongSymbol" SG_ 882 TRCM_a304_passengerAirbagStage2S "TRCM_a304_passengerAirbagStage2Suppressed";
BA_ "SystemSignalLongSymbol" SG_ 882 TRCM_a305_passengerAirbagActiveV "TRCM_a305_passengerAirbagActiveVentSuppressed";
BA_ "SystemSignalLongSymbol" SG_ 882 TRCM_a306_inboardSeatAirbagSuppr "TRCM_a306_inboardSeatAirbagSuppressed";
BA_ "SystemSignalLongSymbol" SG_ 882 TRCM_a308_kneeAirbagLeftSuppress "TRCM_a308_kneeAirbagLeftSuppressed";
BA_ "SystemSignalLongSymbol" SG_ 882 TRCM_a309_kneeAirbagRightSuppres "TRCM_a309_kneeAirbagRightSuppressed";
BA_ "SystemSignalLongSymbol" SG_ 882 TRCM_a310_curtainAirbagLeftSuppr "TRCM_a310_curtainAirbagLeftSuppressed";
BA_ "SystemSignalLongSymbol" SG_ 882 TRCM_a311_curtainAirbagRightSupp "TRCM_a311_curtainAirbagRightSuppressed";
BA_ "SystemSignalLongSymbol" SG_ 882 TRCM_a312_seatbeltLoadLimiterFro "TRCM_a312_seatbeltLoadLimiterFrontLeftSuppressed";
BA_ "SystemSignalLongSymbol" SG_ 882 TRCM_a313_seatbeltLoadLimiterFro "TRCM_a313_seatbeltLoadLimiterFrontRightSuppressed";
BA_ "SystemSignalLongSymbol" SG_ 882 TRCM_a314_seatbeltShoulderPreten "TRCM_a314_seatbeltShoulderPretensionerFrontLeftSuppressed";
BA_ "SystemSignalLongSymbol" SG_ 882 TRCM_a315_seatbeltShoulderPreten "TRCM_a315_seatbeltShoulderPretensionerFrontRightSuppressed";
BA_ "SystemSignalLongSymbol" SG_ 882 TRCM_a316_seatbeltLapPretensione "TRCM_a316_seatbeltLapPretensionerFrontLeftSuppressed";
BA_ "SystemSignalLongSymbol" SG_ 882 TRCM_a317_seatbeltLapPretensione "TRCM_a317_seatbeltLapPretensionerFrontRightSuppressed";
BA_ "SystemSignalLongSymbol" SG_ 882 TRCM_a318_outboardSeatAirbagLeft "TRCM_a318_outboardSeatAirbagLeftSuppressed";
BA_ "SystemSignalLongSymbol" SG_ 882 TRCM_a319_outboardSeatAirbagRigh "TRCM_a319_outboardSeatAirbagRightSuppressed";
BA_ "SystemSignalLongSymbol" SG_ 882 TRCM_a320_hoodLifterLeftSuppress "TRCM_a320_hoodLifterLeftSuppressed";
BA_ "SystemSignalLongSymbol" SG_ 882 TRCM_a321_hoodLifterRightSuppres "TRCM_a321_hoodLifterRightSuppressed";
BA_ "SystemSignalLongSymbol" SG_ 882 TRCM_a322_seatbeltShoulderPreten "TRCM_a322_seatbeltShoulderPretensionerRearLeftSuppressed";
BA_ "SystemSignalLongSymbol" SG_ 882 TRCM_a323_seatbeltShoulderPreten "TRCM_a323_seatbeltShoulderPretensionerRearRightSuppressed";
BA_ "SystemSignalLongSymbol" SG_ 882 TRCM_a332_driverAirbagStage1Depl "TRCM_a332_driverAirbagStage1Deployed";
BA_ "SystemSignalLongSymbol" SG_ 882 TRCM_a333_passengerAirbagStage1D "TRCM_a333_passengerAirbagStage1Deployed";
BA_ "SystemSignalLongSymbol" SG_ 882 TRCM_a334_driverAirbagStage2Depl "TRCM_a334_driverAirbagStage2Deployed";
BA_ "SystemSignalLongSymbol" SG_ 882 TRCM_a335_driverAirbagActiveVent "TRCM_a335_driverAirbagActiveVentDeployed";
BA_ "SystemSignalLongSymbol" SG_ 882 TRCM_a336_passengerAirbagStage2D "TRCM_a336_passengerAirbagStage2Deployed";
BA_ "SystemSignalLongSymbol" SG_ 882 TRCM_a337_passengerAirbagActiveV "TRCM_a337_passengerAirbagActiveVentDeployed";
BA_ "SystemSignalLongSymbol" SG_ 882 TRCM_a338_inboardSeatAirbagDeplo "TRCM_a338_inboardSeatAirbagDeployed";
BA_ "SystemSignalLongSymbol" SG_ 882 TRCM_a341_kneeAirbagRightDeploye "TRCM_a341_kneeAirbagRightDeployed";
BA_ "SystemSignalLongSymbol" SG_ 882 TRCM_a342_curtainAirbagLeftDeplo "TRCM_a342_curtainAirbagLeftDeployed";
BA_ "SystemSignalLongSymbol" SG_ 882 TRCM_a343_curtainAirbagRightDepl "TRCM_a343_curtainAirbagRightDeployed";
BA_ "SystemSignalLongSymbol" SG_ 882 TRCM_a344_seatbeltLoadLimiterFro "TRCM_a344_seatbeltLoadLimiterFrontLeftDeployed";
BA_ "SystemSignalLongSymbol" SG_ 882 TRCM_a345_seatbeltLoadLimiterFro "TRCM_a345_seatbeltLoadLimiterFrontRightDeployed";
BA_ "SystemSignalLongSymbol" SG_ 882 TRCM_a346_seatbeltShoulderPreten "TRCM_a346_seatbeltShoulderPretensionerFrontLeftDeployed";
BA_ "SystemSignalLongSymbol" SG_ 882 TRCM_a347_seatbeltShoulderPreten "TRCM_a347_seatbeltShoulderPretensionerFrontRightDeployed";
BA_ "SystemSignalLongSymbol" SG_ 882 TRCM_a348_seatbeltLapPretensione "TRCM_a348_seatbeltLapPretensionerFrontLeftDeployed";
BA_ "SystemSignalLongSymbol" SG_ 882 TRCM_a349_seatbeltLapPretensione "TRCM_a349_seatbeltLapPretensionerFrontRightDeployed";
BA_ "SystemSignalLongSymbol" SG_ 882 TRCM_a350_outboardSeatAirbagLeft "TRCM_a350_outboardSeatAirbagLeftDeployed";
BA_ "SystemSignalLongSymbol" SG_ 882 TRCM_a351_outboardSeatAirbagRigh "TRCM_a351_outboardSeatAirbagRightDeployed";
BA_ "SystemSignalLongSymbol" SG_ 882 TRCM_a353_hoodLifterRightDeploye "TRCM_a353_hoodLifterRightDeployed";
BA_ "SystemSignalLongSymbol" SG_ 882 TRCM_a354_seatbeltShoulderPreten "TRCM_a354_seatbeltShoulderPretensionerRearLeftDeployed";
BA_ "SystemSignalLongSymbol" SG_ 882 TRCM_a355_seatbeltShoulderPreten "TRCM_a355_seatbeltShoulderPretensionerRearRightDeployed";
BA_ "SystemSignalLongSymbol" SG_ 882 TRCM_a364_safingEngine0NoValidDa "TRCM_a364_safingEngine0NoValidData";
BA_ "SystemSignalLongSymbol" SG_ 882 TRCM_a365_safingEngine1NoValidDa "TRCM_a365_safingEngine1NoValidData";
BA_ "SystemSignalLongSymbol" SG_ 882 TRCM_a366_safingEngine2NoValidDa "TRCM_a366_safingEngine2NoValidData";
BA_ "SystemSignalLongSymbol" SG_ 882 TRCM_a367_safingEngine3NoValidDa "TRCM_a367_safingEngine3NoValidData";
BA_ "SystemSignalLongSymbol" SG_ 882 TRCM_a368_safingEngine4NoValidDa "TRCM_a368_safingEngine4NoValidData";
BA_ "SystemSignalLongSymbol" SG_ 882 TRCM_a369_safingEngine5NoValidDa "TRCM_a369_safingEngine5NoValidData";
BA_ "SystemSignalLongSymbol" SG_ 882 TRCM_a370_safingEngine6NoValidDa "TRCM_a370_safingEngine6NoValidData";
BA_ "SystemSignalLongSymbol" SG_ 882 TRCM_a371_safingEngine7NoValidDa "TRCM_a371_safingEngine7NoValidData";
BA_ "SystemSignalLongSymbol" SG_ 882 TRCM_a372_safingEngine8NoValidDa "TRCM_a372_safingEngine8NoValidData";
BA_ "SystemSignalLongSymbol" SG_ 882 TRCM_a373_safingEngine9NoValidDa "TRCM_a373_safingEngine9NoValidData";
BA_ "SystemSignalLongSymbol" SG_ 882 TRCM_a374_safingEngine10NoValidD "TRCM_a374_safingEngine10NoValidData";
BA_ "SystemSignalLongSymbol" SG_ 882 TRCM_a375_safingEngine11NoValidD "TRCM_a375_safingEngine11NoValidData";
BA_ "SystemSignalLongSymbol" SG_ 882 TRCM_a376_safingEngine12NoValidD "TRCM_a376_safingEngine12NoValidData";
BA_ "SystemSignalLongSymbol" SG_ 882 TRCM_a377_safingEngine13NoValidD "TRCM_a377_safingEngine13NoValidData";
BA_ "SystemSignalLongSymbol" SG_ 882 TRCM_a378_safingEngine14NoValidD "TRCM_a378_safingEngine14NoValidData";
BA_ "SystemSignalLongSymbol" SG_ 882 TRCM_a379_safingEngine15NoValidD "TRCM_a379_safingEngine15NoValidData";
BA_ "SystemSignalLongSymbol" SG_ 882 TRCM_a380_safingEngine16NoValidD "TRCM_a380_safingEngine16NoValidData";
BA_ "SystemSignalLongSymbol" SG_ 882 TRCM_a381_safingEngine17NoValidD "TRCM_a381_safingEngine17NoValidData";
BA_ "SystemSignalLongSymbol" SG_ 882 TRCM_a382_safingEngine18NoValidD "TRCM_a382_safingEngine18NoValidData";
BA_ "SystemSignalLongSymbol" SG_ 882 TRCM_a383_safingEngine19NoValidD "TRCM_a383_safingEngine19NoValidData";
BA_ "SystemSignalLongSymbol" SG_ 882 TRCM_a384_safingEngine20NoValidD "TRCM_a384_safingEngine20NoValidData";
BA_ "SystemSignalLongSymbol" SG_ 882 TRCM_a385_safingEngine21NoValidD "TRCM_a385_safingEngine21NoValidData";
BA_ "SystemSignalLongSymbol" SG_ 882 TRCM_a390_systemAsicClockOrOpera "TRCM_a390_systemAsicClockOrOperatingStateError";
BA_ "SystemSignalLongSymbol" SG_ 882 TRCM_a391_extAsic1ClockOrOperati "TRCM_a391_extAsic1ClockOrOperatingStateError";
BA_ "SystemSignalLongSymbol" SG_ 882 TRCM_a392_extAsic2ClockOrOperati "TRCM_a392_extAsic2ClockOrOperatingStateError";
BA_ "SystemSignalLongSymbol" SG_ 882 TRCM_a393_depAdcConvertRatioErro "TRCM_a393_depAdcConvertRatioError";
BA_ "SystemSignalLongSymbol" SG_ 882 TRCM_a394_gspiGlobalStatusWordEr "TRCM_a394_gspiGlobalStatusWordError";
BA_ "SystemSignalLongSymbol" SG_ 882 TRCM_a396_spiCommunicationProgra "TRCM_a396_spiCommunicationProgramError";
BA_ "SystemSignalLongSymbol" SG_ 882 TRCM_a400_driverAirbagStage1Issu "TRCM_a400_driverAirbagStage1Issue";
BA_ "SystemSignalLongSymbol" SG_ 882 TRCM_a401_passengerAirbagStage1I "TRCM_a401_passengerAirbagStage1Issue";
BA_ "SystemSignalLongSymbol" SG_ 882 TRCM_a402_driverAirbagStage2Issu "TRCM_a402_driverAirbagStage2Issue";
BA_ "SystemSignalLongSymbol" SG_ 882 TRCM_a403_driverAirbagActiveVent "TRCM_a403_driverAirbagActiveVentIssue";
BA_ "SystemSignalLongSymbol" SG_ 882 TRCM_a404_passengerAirbagStage2I "TRCM_a404_passengerAirbagStage2Issue";
BA_ "SystemSignalLongSymbol" SG_ 882 TRCM_a405_passengerAirbagActiveV "TRCM_a405_passengerAirbagActiveVentIssue";
BA_ "SystemSignalLongSymbol" SG_ 882 TRCM_a411_curtainAirbagRightIssu "TRCM_a411_curtainAirbagRightIssue";
BA_ "SystemSignalLongSymbol" SG_ 882 TRCM_a412_seatbeltLoadLimiterFro "TRCM_a412_seatbeltLoadLimiterFrontLeftIssue";
BA_ "SystemSignalLongSymbol" SG_ 882 TRCM_a413_seatbeltLoadLimiterFro "TRCM_a413_seatbeltLoadLimiterFrontRightIssue";
BA_ "SystemSignalLongSymbol" SG_ 882 TRCM_a414_seatbeltShoulderPreten "TRCM_a414_seatbeltShoulderPretensionerFrontLeftIssue";
BA_ "SystemSignalLongSymbol" SG_ 882 TRCM_a415_seatbeltShoulderPreten "TRCM_a415_seatbeltShoulderPretensionerFrontRightIssue";
BA_ "SystemSignalLongSymbol" SG_ 882 TRCM_a416_seatbeltLapPretensione "TRCM_a416_seatbeltLapPretensionerFrontLeftIssue";
BA_ "SystemSignalLongSymbol" SG_ 882 TRCM_a417_seatbeltLapPretensione "TRCM_a417_seatbeltLapPretensionerFrontRightIssue";
BA_ "SystemSignalLongSymbol" SG_ 882 TRCM_a418_outboardSeatAirbagLeft "TRCM_a418_outboardSeatAirbagLeftIssue";
BA_ "SystemSignalLongSymbol" SG_ 882 TRCM_a419_outboardSeatAirbagRigh "TRCM_a419_outboardSeatAirbagRightIssue";
BA_ "SystemSignalLongSymbol" SG_ 882 TRCM_a422_seatbeltShoulderPreten "TRCM_a422_seatbeltShoulderPretensionerRearLeftIssue";
BA_ "SystemSignalLongSymbol" SG_ 882 TRCM_a423_seatbeltShoulderPreten "TRCM_a423_seatbeltShoulderPretensionerRearRightIssue";
BA_ "SystemSignalLongSymbol" SG_ 882 TRCM_a432_driverAirbagStage1Conf "TRCM_a432_driverAirbagStage1ConfigError";
BA_ "SystemSignalLongSymbol" SG_ 882 TRCM_a433_passengerAirbagStage1C "TRCM_a433_passengerAirbagStage1ConfigError";
BA_ "SystemSignalLongSymbol" SG_ 882 TRCM_a434_driverAirbagStage2Conf "TRCM_a434_driverAirbagStage2ConfigError";
BA_ "SystemSignalLongSymbol" SG_ 882 TRCM_a435_driverAirbagActiveVent "TRCM_a435_driverAirbagActiveVentConfigError";
BA_ "SystemSignalLongSymbol" SG_ 882 TRCM_a436_passengerAirbagStage2C "TRCM_a436_passengerAirbagStage2ConfigError";
BA_ "SystemSignalLongSymbol" SG_ 882 TRCM_a437_passengerAirbagActiveV "TRCM_a437_passengerAirbagActiveVentConfigError";
BA_ "SystemSignalLongSymbol" SG_ 882 TRCM_a438_inboardSeatAirbagConfi "TRCM_a438_inboardSeatAirbagConfigError";
BA_ "SystemSignalLongSymbol" SG_ 882 TRCM_a440_kneeAirbagLeftConfigEr "TRCM_a440_kneeAirbagLeftConfigError";
BA_ "SystemSignalLongSymbol" SG_ 882 TRCM_a441_kneeAirbagRightConfigE "TRCM_a441_kneeAirbagRightConfigError";
BA_ "SystemSignalLongSymbol" SG_ 882 TRCM_a442_curtainAirbagLeftConfi "TRCM_a442_curtainAirbagLeftConfigError";
BA_ "SystemSignalLongSymbol" SG_ 882 TRCM_a443_curtainAirbagRightConf "TRCM_a443_curtainAirbagRightConfigError";
BA_ "SystemSignalLongSymbol" SG_ 882 TRCM_a444_seatbeltLoadLimiterFro "TRCM_a444_seatbeltLoadLimiterFrontLeftConfigError";
BA_ "SystemSignalLongSymbol" SG_ 882 TRCM_a445_seatbeltLoadLimiterFro "TRCM_a445_seatbeltLoadLimiterFrontRightConfigError";
BA_ "SystemSignalLongSymbol" SG_ 882 TRCM_a446_seatbeltShoulderPreten "TRCM_a446_seatbeltShoulderPretensionerFrontLeftConfigError";
BA_ "SystemSignalLongSymbol" SG_ 882 TRCM_a447_seatbeltShoulderPreten "TRCM_a447_seatbeltShoulderPretensionerFrontRightConfigError";
BA_ "SystemSignalLongSymbol" SG_ 882 TRCM_a448_seatbeltLapPretensione "TRCM_a448_seatbeltLapPretensionerFrontLeftConfigError";
BA_ "SystemSignalLongSymbol" SG_ 882 TRCM_a449_seatbeltLapPretensione "TRCM_a449_seatbeltLapPretensionerFrontRightConfigError";
BA_ "SystemSignalLongSymbol" SG_ 882 TRCM_a450_outboardSeatAirbagLeft "TRCM_a450_outboardSeatAirbagLeftConfigError";
BA_ "SystemSignalLongSymbol" SG_ 882 TRCM_a451_outboardSeatAirbagRigh "TRCM_a451_outboardSeatAirbagRightConfigError";
BA_ "SystemSignalLongSymbol" SG_ 882 TRCM_a452_hoodLifterLeftConfigEr "TRCM_a452_hoodLifterLeftConfigError";
BA_ "SystemSignalLongSymbol" SG_ 882 TRCM_a453_hoodLifterRightConfigE "TRCM_a453_hoodLifterRightConfigError";
BA_ "SystemSignalLongSymbol" SG_ 882 TRCM_a454_seatbeltShoulderPreten "TRCM_a454_seatbeltShoulderPretensionerRearLeftConfigError";
BA_ "SystemSignalLongSymbol" SG_ 882 TRCM_a455_seatbeltShoulderPreten "TRCM_a455_seatbeltShoulderPretensionerRearRightConfigError";
BA_ "SystemSignalLongSymbol" SG_ 882 TRCM_a545_erCapBelowAutarkyThres "TRCM_a545_erCapBelowAutarkyThreshold";
BA_ "SystemSignalLongSymbol" SG_ 882 TRCM_a546_sensorValuesFaultedByS "TRCM_a546_sensorValuesFaultedBySmart";
BA_ "SystemSignalLongSymbol" SG_ 882 TRCM_a550_AlgoWake_RCM_WAKE_FRON "TRCM_a550_AlgoWake_RCM_WAKE_FRONT";
BA_ "SystemSignalLongSymbol" SG_ 882 TRCM_a553_AlgoWake_RCM_WAKE_RIGH "TRCM_a553_AlgoWake_RCM_WAKE_RIGHT";
BA_ "SystemSignalLongSymbol" SG_ 882 TRCM_a554_AlgoWake_PAS_LH_PLAUSI "TRCM_a554_AlgoWake_PAS_LH_PLAUSI_FRONT";
BA_ "SystemSignalLongSymbol" SG_ 882 TRCM_a555_AlgoWake_PAS_LH_PLAUSI "TRCM_a555_AlgoWake_PAS_LH_PLAUSI_REAR";
BA_ "SystemSignalLongSymbol" SG_ 882 TRCM_a557_AlgoWake_PAS_RH_PLAUSI "TRCM_a557_AlgoWake_PAS_RH_PLAUSI_FRONT";
BA_ "SystemSignalLongSymbol" SG_ 882 TRCM_a558_AlgoWake_PAS_RH_PLAUSI "TRCM_a558_AlgoWake_PAS_RH_PLAUSI_REAR";
BA_ "SystemSignalLongSymbol" SG_ 882 TRCM_a560_AlgoWake_RCM_WAKE_ROLL "TRCM_a560_AlgoWake_RCM_WAKE_ROLL_LEFT";
BA_ "SystemSignalLongSymbol" SG_ 882 TRCM_a561_AlgoWake_RCM_WAKE_ROLL "TRCM_a561_AlgoWake_RCM_WAKE_ROLL_RIGHT";
BA_ "SystemSignalLongSymbol" SG_ 882 TRCM_a562_AlgoWake_RCM_AWAKE_FRO "TRCM_a562_AlgoWake_RCM_AWAKE_FRONT";
BA_ "SystemSignalLongSymbol" SG_ 882 TRCM_a563_AlgoWake_RCM_AWAKE_REA "TRCM_a563_AlgoWake_RCM_AWAKE_REAR";
BA_ "SystemSignalLongSymbol" SG_ 882 TRCM_a564_AlgoWake_RCM_AWAKE_LEF "TRCM_a564_AlgoWake_RCM_AWAKE_LEFT";
BA_ "SystemSignalLongSymbol" SG_ 882 TRCM_a565_AlgoWake_RCM_AWAKE_RIG "TRCM_a565_AlgoWake_RCM_AWAKE_RIGHT";
BA_ "SystemSignalLongSymbol" SG_ 882 TRCM_a566_AlgoWake_RCM_AWAKE_ROL "TRCM_a566_AlgoWake_RCM_AWAKE_ROLL";
BA_ "SystemSignalLongSymbol" SG_ 882 TRCM_a570_AlgoWake_PAS_WAKE_RIGH "TRCM_a570_AlgoWake_PAS_WAKE_RIGHT";
BA_ "SystemSignalLongSymbol" SG_ 882 TRCM_a576_AlgoWake_IMPACT_FINISH "TRCM_a576_AlgoWake_IMPACT_FINISH_X";
BA_ "SystemSignalLongSymbol" SG_ 882 TRCM_a577_AlgoWake_IMPACT_FINISH "TRCM_a577_AlgoWake_IMPACT_FINISH_Y";
BA_ "SystemSignalLongSymbol" SG_ 882 TRCM_a578_AlgoWake_IMPACT_FINISH "TRCM_a578_AlgoWake_IMPACT_FINISH_ROLL";
BA_ "SystemSignalLongSymbol" SG_ 882 TRCM_a581_AlgoWake_RCM_ENABLED_R "TRCM_a581_AlgoWake_RCM_ENABLED_ROLL";
BA_ "SystemSignalLongSymbol" SG_ 882 TRCM_a590_pitchRateOffsetPosLimi "TRCM_a590_pitchRateOffsetPosLimit";
BA_ "SystemSignalLongSymbol" SG_ 882 TRCM_a591_pitchRateOffsetNegLimi "TRCM_a591_pitchRateOffsetNegLimit";
BA_ "SystemSignalLongSymbol" SG_ 882 TRCM_a594_longitudinalAccelOffse "TRCM_a594_longitudinalAccelOffsetPosLimit";
BA_ "SystemSignalLongSymbol" SG_ 882 TRCM_a595_longitudinalAccelOffse "TRCM_a595_longitudinalAccelOffsetNegLimit";
BA_ "SystemSignalLongSymbol" SG_ 882 TRCM_a596_lateralAccelOffsetPosL "TRCM_a596_lateralAccelOffsetPosLimit";
BA_ "SystemSignalLongSymbol" SG_ 882 TRCM_a597_lateralAccelOffsetNegL "TRCM_a597_lateralAccelOffsetNegLimit";
BA_ "SystemSignalLongSymbol" SG_ 882 TRCM_a598_verticalAccelOffsetPos "TRCM_a598_verticalAccelOffsetPosLimit";
BA_ "SystemSignalLongSymbol" SG_ 882 TRCM_a599_verticalAccelOffsetNeg "TRCM_a599_verticalAccelOffsetNegLimit";
BA_ "SystemSignalLongSymbol" SG_ 882 TRCM_a600_airbagAsicStartupFailu "TRCM_a600_airbagAsicStartupFailure";
BA_ "SystemSignalLongSymbol" SG_ 882 TRCM_a601_loop0AsicStartupDiagno "TRCM_a601_loop0AsicStartupDiagnosticFailure";
BA_ "SystemSignalLongSymbol" SG_ 882 TRCM_a602_loop1AsicStartupDiagno "TRCM_a602_loop1AsicStartupDiagnosticFailure";
BA_ "SystemSignalLongSymbol" SG_ 882 TRCM_a603_loop2AsicStartupDiagno "TRCM_a603_loop2AsicStartupDiagnosticFailure";
BA_ "SystemSignalLongSymbol" SG_ 882 TRCM_a604_loop3AsicStartupDiagno "TRCM_a604_loop3AsicStartupDiagnosticFailure";
BA_ "SystemSignalLongSymbol" SG_ 882 TRCM_a605_loop4AsicStartupDiagno "TRCM_a605_loop4AsicStartupDiagnosticFailure";
BA_ "SystemSignalLongSymbol" SG_ 882 TRCM_a606_loop5AsicStartupDiagno "TRCM_a606_loop5AsicStartupDiagnosticFailure";
BA_ "SystemSignalLongSymbol" SG_ 882 TRCM_a607_loop6AsicStartupDiagno "TRCM_a607_loop6AsicStartupDiagnosticFailure";
BA_ "SystemSignalLongSymbol" SG_ 882 TRCM_a608_loop7AsicStartupDiagno "TRCM_a608_loop7AsicStartupDiagnosticFailure";
BA_ "SystemSignalLongSymbol" SG_ 882 TRCM_a609_loop8AsicStartupDiagno "TRCM_a609_loop8AsicStartupDiagnosticFailure";
BA_ "SystemSignalLongSymbol" SG_ 882 TRCM_a610_loop9AsicStartupDiagno "TRCM_a610_loop9AsicStartupDiagnosticFailure";
BA_ "SystemSignalLongSymbol" SG_ 882 TRCM_a611_loop10AsicStartupDiagn "TRCM_a611_loop10AsicStartupDiagnosticFailure";
BA_ "SystemSignalLongSymbol" SG_ 882 TRCM_a612_loop11AsicStartupDiagn "TRCM_a612_loop11AsicStartupDiagnosticFailure";
BA_ "SystemSignalLongSymbol" SG_ 882 TRCM_a613_loop12AsicStartupDiagn "TRCM_a613_loop12AsicStartupDiagnosticFailure";
BA_ "SystemSignalLongSymbol" SG_ 882 TRCM_a614_loop13AsicStartupDiagn "TRCM_a614_loop13AsicStartupDiagnosticFailure";
BA_ "SystemSignalLongSymbol" SG_ 882 TRCM_a615_loop14AsicStartupDiagn "TRCM_a615_loop14AsicStartupDiagnosticFailure";
BA_ "SystemSignalLongSymbol" SG_ 882 TRCM_a616_loop15AsicStartupDiagn "TRCM_a616_loop15AsicStartupDiagnosticFailure";
BA_ "SystemSignalLongSymbol" SG_ 882 TRCM_a617_loop16AsicStartupDiagn "TRCM_a617_loop16AsicStartupDiagnosticFailure";
BA_ "SystemSignalLongSymbol" SG_ 882 TRCM_a618_loop17AsicStartupDiagn "TRCM_a618_loop17AsicStartupDiagnosticFailure";
BA_ "SystemSignalLongSymbol" SG_ 882 TRCM_a619_loop18AsicStartupDiagn "TRCM_a619_loop18AsicStartupDiagnosticFailure";
BA_ "SystemSignalLongSymbol" SG_ 882 TRCM_a620_loop19AsicStartupDiagn "TRCM_a620_loop19AsicStartupDiagnosticFailure";
BA_ "SystemSignalLongSymbol" SG_ 882 TRCM_a621_loop20AsicStartupDiagn "TRCM_a621_loop20AsicStartupDiagnosticFailure";
BA_ "SystemSignalLongSymbol" SG_ 882 TRCM_a622_loop21AsicStartupDiagn "TRCM_a622_loop21AsicStartupDiagnosticFailure";
BA_ "SystemSignalLongSymbol" SG_ 882 TRCM_a623_loop22AsicStartupDiagn "TRCM_a623_loop22AsicStartupDiagnosticFailure";
BA_ "SystemSignalLongSymbol" SG_ 882 TRCM_a624_loop23AsicStartupDiagn "TRCM_a624_loop23AsicStartupDiagnosticFailure";
BA_ "SystemSignalLongSymbol" SG_ 882 TRCM_a625_loop24AsicStartupDiagn "TRCM_a625_loop24AsicStartupDiagnosticFailure";
BA_ "SystemSignalLongSymbol" SG_ 882 TRCM_a626_loop25AsicStartupDiagn "TRCM_a626_loop25AsicStartupDiagnosticFailure";
BA_ "SystemSignalLongSymbol" SG_ 882 TRCM_a627_loop26AsicStartupDiagn "TRCM_a627_loop26AsicStartupDiagnosticFailure";
BA_ "SystemSignalLongSymbol" SG_ 882 TRCM_a628_loop27AsicStartupDiagn "TRCM_a628_loop27AsicStartupDiagnosticFailure";
BA_ "SystemSignalLongSymbol" SG_ 882 TRCM_a629_loop28AsicStartupDiagn "TRCM_a629_loop28AsicStartupDiagnosticFailure";
BA_ "SystemSignalLongSymbol" SG_ 882 TRCM_a630_loop29AsicStartupDiagn "TRCM_a630_loop29AsicStartupDiagnosticFailure";
BA_ "SystemSignalLongSymbol" SG_ 882 TRCM_a631_loop30AsicStartupDiagn "TRCM_a631_loop30AsicStartupDiagnosticFailure";
BA_ "SystemSignalLongSymbol" SG_ 882 TRCM_a632_loop31AsicStartupDiagn "TRCM_a632_loop31AsicStartupDiagnosticFailure";
BA_ "SystemSignalLongSymbol" SG_ 882 TRCM_a633_glacierInitialStatusFa "TRCM_a633_glacierInitialStatusFailure";
BA_ "SystemSignalLongSymbol" SG_ 882 TRCM_a634_glacierTraceabilityRea "TRCM_a634_glacierTraceabilityReadoutA0A0Failure";
BA_ "SystemSignalLongSymbol" SG_ 882 TRCM_a635_glacierTraceabilityRea "TRCM_a635_glacierTraceabilityReadoutB0B0Failure";
BA_ "SystemSignalLongSymbol" SG_ 882 TRCM_a636_glacierRegisterPattern "TRCM_a636_glacierRegisterPatternWriteFailure";
BA_ "SystemSignalLongSymbol" SG_ 882 TRCM_a637_glacierFixedPatternSel "TRCM_a637_glacierFixedPatternSelfTestFailure";
BA_ "SystemSignalLongSymbol" SG_ 882 TRCM_a638_glacierSelfTestEFailur "TRCM_a638_glacierSelfTestEFailure";
BA_ "SystemSignalLongSymbol" SG_ 882 TRCM_a639_glacierSelfTestFFailur "TRCM_a639_glacierSelfTestFFailure";
BA_ "SystemSignalLongSymbol" SG_ 882 TRCM_a640_glacierAnalogSelfTestF "TRCM_a640_glacierAnalogSelfTestFailure";
BA_ "SystemSignalLongSymbol" SG_ 882 TRCM_a641_glacierOscillatorVerif "TRCM_a641_glacierOscillatorVerificationFailure";
BA_ "SystemSignalLongSymbol" SG_ 882 TRCM_a642_glacierFinalStatusFail "TRCM_a642_glacierFinalStatusFailure";
BA_ "SystemSignalLongSymbol" SG_ 882 TRCM_a643_glacierOffsetVerificat "TRCM_a643_glacierOffsetVerificationFailure";
BA_ "SystemSignalLongSymbol" SG_ 882 TRCM_a644_glacierNormalOperation "TRCM_a644_glacierNormalOperationFailure";
BA_ "Confidence" SG_ 850 TRCM_infoIndex 1;
BA_ "Confidence" SG_ 850 TRCM_infoBuildType 0;
BA_ "Confidence" SG_ 850 TRCM_infoBuildConfigId 0;
BA_ "Confidence" SG_ 850 TRCM_infoHardwareId 0;
BA_ "Confidence" SG_ 850 TRCM_infoComponentId 0;
BA_ "Confidence" SG_ 850 TRCM_infoPcbaId 0;
BA_ "Confidence" SG_ 850 TRCM_infoAssemblyId 0;
BA_ "GenSigSNA" SG_ 850 TRCM_infoAssemblyId "255";
BA_ "Confidence" SG_ 850 TRCM_infoUsageId 0;
BA_ "Confidence" SG_ 850 TRCM_infoSubUsageId 0;
BA_ "Confidence" SG_ 850 TRCM_infoAppCrc 0;
BA_ "Confidence" SG_ 850 TRCM_infoAppGitHash 0;
BA_ "Confidence" SG_ 850 TRCM_infoBootGitHash 0;
BA_ "Confidence" SG_ 850 TRCM_infoBootUdsProtoVersion 0;
BA_ "Confidence" SG_ 850 TRCM_infoBootCrc 0;
BA_ "Confidence" SG_ 1021 UI_autopilotControlIndex 1;
BA_ "Confidence" SG_ 1021 UI_hovEnabled 0;
BA_ "Confidence" SG_ 1021 UI_donDisableAutoWiperDuration 1;
BA_ "Confidence" SG_ 1021 UI_donDisableOnAutoWiperSpeed 1;
BA_ "Confidence" SG_ 1021 UI_blindspotMinSpeed 1;
BA_ "Confidence" SG_ 1021 UI_blindspotDistance 1;
BA_ "Confidence" SG_ 1021 UI_blindspotTTC 1;
BA_ "Confidence" SG_ 1021 UI_donStopEndOfRampBuffer 1;
BA_ "Confidence" SG_ 1021 UI_donDisableCutin 1;
BA_ "Confidence" SG_ 1021 UI_smartSetSpeedOffset 0;
BA_ "Confidence" SG_ 1021 UI_smartSetSpeedOffsetType 0;
BA_ "Confidence" SG_ 1021 UI_fsdStopsControlEnabled 0;
BA_ "Confidence" SG_ 1021 UI_smartSetSpeed 0;
BA_ "Confidence" SG_ 1021 UI_automaticSetSpeedOffset 0;
BA_ "Confidence" SG_ 1021 UI_homelinkNearby 1;
BA_ "Confidence" SG_ 1021 UI_enableFullSelfDriving 0;
BA_ "Confidence" SG_ 1021 UI_hasFullSelfDriving 0;
BA_ "Confidence" SG_ 1021 UI_autosteerActivation 0;
BA_ "Confidence" SG_ 1021 UI_fsdBetaRequest 0;
BA_ "Confidence" SG_ 1021 UI_fullSelfDrivingSuspended 0;
BA_ "Confidence" SG_ 1021 UI_disableOptionalLaneChanges 0;
BA_ "Confidence" SG_ 1021 UI_applyADDWWarnings 0;
BA_ "Confidence" SG_ 1021 UI_selectableCameraRequest 0;
BA_ "GenSigSNA" SG_ 1021 UI_selectableCameraRequest "15";
BA_ "Confidence" SG_ 1021 UI_overrideSleepWithSuspend 1;
BA_ "Confidence" SG_ 1021 UI_driverMonitorConfirmation 0;
BA_ "Confidence" SG_ 1021 UI_parkAssistUseVision 0;
BA_ "Confidence" SG_ 1021 UI_noStalkConfirmAlertHaptic 0;
BA_ "Confidence" SG_ 1021 UI_regulatoryLaneAssistLevel 1;
BA_ "Confidence" SG_ 1021 UI_noStalkConfirmAlertChime 0;
BA_ "Confidence" SG_ 1021 UI_factorySummonEnable 0;
BA_ "Confidence" SG_ 1021 UI_apmv3Branch 1;
BA_ "Confidence" SG_ 1021 UI_enableCabinCamera 0;
BA_ "Confidence" SG_ 1021 UI_enableAutopilotStopWarning 0;
BA_ "Confidence" SG_ 1021 UI_enableVisionSpeedControl 0;
BA_ "Confidence" SG_ 1021 UI_enableTeslaAutopark 0;
BA_ "Confidence" SG_ 1021 UI_autoTurnSignalMode 0;
BA_ "Confidence" SG_ 1021 UI_enableCabinAudioRecording 0;
BA_ "SystemSignalLongSymbol" SG_ 1021 UI_enableApproachingEmergencyVeh "UI_enableApproachingEmergencyVehicleDetection";
BA_ "SystemSignalLongSymbol" SG_ 1021 UI_enableStartFsdFromParkBrakeCo "UI_enableStartFsdFromParkBrakeConfirmation";
BA_ "Confidence" SG_ 1021 UI_fsdMaxSpeedOffsetPercentage 1;
BA_ "Confidence" SG_ 1021 UI_navMinutesToArrival 1;
BA_ "Confidence" SG_ 1021 UI_autopilotDrivingProfile 0;
BA_ "Confidence" SG_ 659 UI_steeringTuneRequest 0;
BA_ "Confidence" SG_ 659 UI_tractionControlMode 0;
BA_ "Confidence" SG_ 659 UI_parkBrakeRequest 0;
BA_ "GenSigSNA" SG_ 659 UI_parkBrakeRequest "3";
BA_ "Confidence" SG_ 659 UI_winchModeRequest 0;
BA_ "Confidence" SG_ 659 UI_zeroSpeedConfirmed 1;
BA_ "GenSigSNA" SG_ 659 UI_zeroSpeedConfirmed "3";
BA_ "Confidence" SG_ 659 UI_trailerMode 0;
BA_ "Confidence" SG_ 659 UI_distanceUnits 1;
BA_ "Confidence" SG_ 659 UI_accOvertakeEnable 0;
BA_ "GenSigSNA" SG_ 659 UI_accOvertakeEnable "3";
BA_ "Confidence" SG_ 659 UI_aebEnable 0;
BA_ "GenSigSNA" SG_ 659 UI_aebEnable "3";
BA_ "Confidence" SG_ 659 UI_aesEnable 0;
BA_ "GenSigSNA" SG_ 659 UI_aesEnable "3";
BA_ "Confidence" SG_ 659 UI_ahlbEnable 0;
BA_ "GenSigSNA" SG_ 659 UI_ahlbEnable "3";
BA_ "Confidence" SG_ 659 UI_autoLaneChangeEnable 0;
BA_ "GenSigSNA" SG_ 659 UI_autoLaneChangeEnable "3";
BA_ "Confidence" SG_ 659 UI_winchProxUserOverride 0;
BA_ "Confidence" SG_ 659 UI_autoParkRequest 0;
BA_ "GenSigSNA" SG_ 659 UI_autoParkRequest "15";
BA_ "Confidence" SG_ 659 UI_bsdEnable 0;
BA_ "GenSigSNA" SG_ 659 UI_bsdEnable "3";
BA_ "Confidence" SG_ 659 UI_fcwEnable 0;
BA_ "GenSigSNA" SG_ 659 UI_fcwEnable "3";
BA_ "Confidence" SG_ 659 UI_fcwSensitivity 0;
BA_ "GenSigSNA" SG_ 659 UI_fcwSensitivity "3";
BA_ "Confidence" SG_ 659 UI_latControlEnable 0;
BA_ "GenSigSNA" SG_ 659 UI_latControlEnable "3";
BA_ "Confidence" SG_ 659 UI_ldwEnable 0;
BA_ "GenSigSNA" SG_ 659 UI_ldwEnable "3";
BA_ "Confidence" SG_ 659 UI_pedalSafetyEnable 1;
BA_ "GenSigSNA" SG_ 659 UI_pedalSafetyEnable "3";
BA_ "Confidence" SG_ 659 UI_pedalMap_epas 1;
BA_ "Confidence" SG_ 659 UI_redLightStopSignEnable 1;
BA_ "GenSigSNA" SG_ 659 UI_redLightStopSignEnable "3";
BA_ "Confidence" SG_ 659 UI_selfParkTune 1;
BA_ "GenSigSNA" SG_ 659 UI_selfParkTune "15";
BA_ "Confidence" SG_ 664 UI_csaOfframpCurvC2 1;
BA_ "Confidence" SG_ 664 UI_csaOfframpCurvC3 1;
BA_ "Confidence" SG_ 664 UI_csaOfframpCurvRange 1;
BA_ "Confidence" SG_ 679 UI_csaRoadCurvC2 1;
BA_ "Confidence" SG_ 679 UI_csaRoadCurvC3 1;
BA_ "Confidence" SG_ 679 UI_csaRoadCurvRange 1;
BA_ "Confidence" SG_ 1096 UI_anonDebugFlag1 1;
BA_ "Confidence" SG_ 1096 UI_anonDebugFlag2 1;
BA_ "Confidence" SG_ 1096 UI_anonDebugFlag3 1;
BA_ "Confidence" SG_ 1096 UI_anonDebugFlag4 1;
BA_ "Confidence" SG_ 1016 UI_autopilotControlRequest 1;
BA_ "Confidence" SG_ 1016 UI_ulcStalkConfirm 0;
BA_ "Confidence" SG_ 1016 UI_curvSpeedAdaptDisable 1;
BA_ "Confidence" SG_ 1016 UI_lssLkaEnabled 0;
BA_ "Confidence" SG_ 1016 UI_lssLdwEnabled 0;
BA_ "Confidence" SG_ 1016 UI_exceptionListEnable 1;
BA_ "Confidence" SG_ 1016 UI_roadCheckDisable 1;
BA_ "Confidence" SG_ 1016 UI_driveOnMapsEnable 0;
BA_ "Confidence" SG_ 1016 UI_handsOnRequirementDisable 1;
BA_ "Confidence" SG_ 1016 UI_fuseLanesDisable 1;
BA_ "Confidence" SG_ 1016 UI_fuseHPPDisable 1;
BA_ "Confidence" SG_ 1016 UI_fuseVehiclesDisable 1;
BA_ "Confidence" SG_ 1016 UI_visionSpeedType 1;
BA_ "Confidence" SG_ 1016 UI_curvatureDatabaseOnly 1;
BA_ "Confidence" SG_ 1016 UI_lssElkEnabled 0;
BA_ "Confidence" SG_ 1016 UI_summonExitType 1;
BA_ "GenSigSNA" SG_ 1016 UI_summonExitType "3";
BA_ "Confidence" SG_ 1016 UI_summonEntryType 1;
BA_ "GenSigSNA" SG_ 1016 UI_summonEntryType "3";
BA_ "Confidence" SG_ 1016 UI_selfParkRequest 0;
BA_ "GenSigSNA" SG_ 1016 UI_selfParkRequest "15";
BA_ "Confidence" SG_ 1016 UI_summonReverseDist 1;
BA_ "GenSigSNA" SG_ 1016 UI_summonReverseDist "63";
BA_ "Confidence" SG_ 1016 UI_drivingSide 1;
BA_ "Confidence" SG_ 1016 UI_accFollowDistanceSetting 1;
BA_ "GenSigSNA" SG_ 1016 UI_accFollowDistanceSetting "7";
BA_ "Confidence" SG_ 1016 UI_followNavRouteEnable 0;
BA_ "Confidence" SG_ 1016 UI_ulcSpeedConfig 0;
BA_ "Confidence" SG_ 1016 UI_ulcBlindSpotConfig 1;
BA_ "Confidence" SG_ 1016 UI_suppressExitPassingLane 0;
BA_ "Confidence" SG_ 1016 UI_smartSummonType 0;
BA_ "Confidence" SG_ 1016 UI_source3D 1;
BA_ "Confidence" SG_ 1016 UI_isaSpeedingChimeMuted 0;
BA_ "Confidence" SG_ 568 UI_mapSpeedLimitDependency 1;
BA_ "GenSigSNA" SG_ 568 UI_mapSpeedLimitDependency "7";
BA_ "Confidence" SG_ 568 UI_roadClass 0;
BA_ "GenSigSNA" SG_ 568 UI_roadClass "0";
BA_ "Confidence" SG_ 568 UI_mapSpeedUnits 1;
BA_ "Confidence" SG_ 568 UI_mapSpeedLimit 1;
BA_ "GenSigSNA" SG_ 568 UI_mapSpeedLimit "31";
BA_ "Confidence" SG_ 568 UI_mapSpeedLimitType 1;
BA_ "GenSigSNA" SG_ 568 UI_mapSpeedLimitType "7";
BA_ "Confidence" SG_ 568 UI_countryCode 1;
BA_ "GenSigSNA" SG_ 568 UI_countryCode "1023";
BA_ "Confidence" SG_ 568 UI_navRouteActive 0;
BA_ "Confidence" SG_ 568 UI_parallelAutoparkEnabled 0;
BA_ "Confidence" SG_ 568 UI_perpendicularAutoparkEnabled 0;
BA_ "Confidence" SG_ 568 UI_nextBranchDist 1;
BA_ "GenSigSNA" SG_ 568 UI_nextBranchDist "31";
BA_ "Confidence" SG_ 568 UI_controlledAccess 0;
BA_ "Confidence" SG_ 568 UI_autosteerRestricted 0;
BA_ "Confidence" SG_ 536 UI_roadSign 1;
BA_ "GenSigSNA" SG_ 536 UI_roadSign "255";
BA_ "Confidence" SG_ 536 UI_splineLocConfidence 1;
BA_ "GenSigSNA" SG_ 536 UI_splineLocConfidence "0";
BA_ "Confidence" SG_ 536 UI_stopSignStopLineDist 1;
BA_ "GenSigSNA" SG_ 536 UI_stopSignStopLineDist "1023";
BA_ "Confidence" SG_ 536 UI_stopSignStopLineConf 1;
BA_ "GenSigSNA" SG_ 536 UI_stopSignStopLineConf "0";
BA_ "Confidence" SG_ 536 UI_trafficLightStopLineDist 1;
BA_ "GenSigSNA" SG_ 536 UI_trafficLightStopLineDist "1023";
BA_ "Confidence" SG_ 536 UI_trafficLightStopLineConf 1;
BA_ "GenSigSNA" SG_ 536 UI_trafficLightStopLineConf "0";
BA_ "Confidence" SG_ 536 UI_baseMapSpeedLimitMPS 1;
BA_ "GenSigSNA" SG_ 536 UI_baseMapSpeedLimitMPS "255";
BA_ "Confidence" SG_ 536 UI_bottomQrtlFleetSpeedMPS 1;
BA_ "GenSigSNA" SG_ 536 UI_bottomQrtlFleetSpeedMPS "255";
BA_ "Confidence" SG_ 536 UI_topQrtlFleetSpeedMPS 1;
BA_ "GenSigSNA" SG_ 536 UI_topQrtlFleetSpeedMPS "255";
BA_ "Confidence" SG_ 536 UI_meanFleetSplineSpeedMPS 1;
BA_ "GenSigSNA" SG_ 536 UI_meanFleetSplineSpeedMPS "255";
BA_ "Confidence" SG_ 536 UI_medianFleetSpeedMPS 1;
BA_ "GenSigSNA" SG_ 536 UI_medianFleetSpeedMPS "255";
BA_ "Confidence" SG_ 536 UI_meanFleetSplineAccelMPS2 1;
BA_ "GenSigSNA" SG_ 536 UI_meanFleetSplineAccelMPS2 "255";
BA_ "Confidence" SG_ 536 UI_rampType 1;
BA_ "GenSigSNA" SG_ 536 UI_rampType "0";
BA_ "Confidence" SG_ 536 UI_valhallaRamp 1;
BA_ "GenSigSNA" SG_ 536 UI_valhallaRamp "0";
BA_ "Confidence" SG_ 536 UI_currSplineIdFull 1;
BA_ "GenSigSNA" SG_ 536 UI_currSplineIdFull "0";
BA_ "Confidence" SG_ 760 UI_gpsHDOP 1;
BA_ "Confidence" SG_ 760 UI_gpsVehicleHeading 1;
BA_ "Confidence" SG_ 760 UI_gpsVehicleSpeed 1;
BA_ "Confidence" SG_ 760 UI_userSpeedOffset 1;
BA_ "Confidence" SG_ 760 UI_mapSpeedLimitUnits 0;
BA_ "Confidence" SG_ 760 UI_userSpeedOffsetUnits 1;
BA_ "Confidence" SG_ 760 UI_mppSpeedLimit 0;
BA_ "Confidence" SG_ 760 UI_gpsNmeaMIA 0;
BA_ "Confidence" SG_ 760 UI_gpsAntennaDisconnected 0;
BA_ "Confidence" SG_ 760 UI_conditionalLimitActive 0;
BA_ "Confidence" SG_ 760 UI_conditionalSpeedLimit 0;
BA_ "GenSigSNA" SG_ 760 UI_conditionalSpeedLimit "31";
BA_ "Confidence" SG_ 985 UI_latitudeOffset 1;
BA_ "Confidence" SG_ 985 UI_longitudeOffset 1;
BA_ "Confidence" SG_ 777 UI_latitude 1;
BA_ "Confidence" SG_ 777 UI_longitude 1;
BA_ "Confidence" SG_ 777 UI_gpsAccuracy 1;
BA_ "GenSigSNA" SG_ 777 UI_gpsAccuracy "127";
BA_ "Confidence" SG_ 1011 UI_odometer 0;
BA_ "GenSigSNA" SG_ 1011 UI_odometer "16777215";
BA_ "Confidence" SG_ 987 UI_phoneLatitude 1;
BA_ "Confidence" SG_ 987 UI_phoneLongitude 1;
BA_ "Confidence" SG_ 987 UI_phoneGpsAccuracy 1;
BA_ "GenSigSNA" SG_ 987 UI_phoneGpsAccuracy "127";
BA_ "Confidence" SG_ 820 UI_systemPowerLimit 1;
BA_ "GenSigSNA" SG_ 820 UI_systemPowerLimit "31";
BA_ "Confidence" SG_ 820 UI_pedalMap 0;
BA_ "Confidence" SG_ 820 UI_enableRegenBackfill 0;
BA_ "Confidence" SG_ 820 UI_systemTorqueLimit 1;
BA_ "GenSigSNA" SG_ 820 UI_systemTorqueLimit "63";
BA_ "Confidence" SG_ 820 UI_closureConfirmed 1;
BA_ "Confidence" SG_ 820 UI_regenTorqueMax 0;
BA_ "Confidence" SG_ 820 UI_limitMode 0;
BA_ "SystemSignalLongSymbol" SG_ 820 UI_factoryCustomerDrivingModeReq "UI_factoryCustomerDrivingModeRequest";
BA_ "Confidence" SG_ 820 UI_motorOnMode 0;
BA_ "Confidence" SG_ 820 UI_stoppingMode 0;
BA_ "Confidence" SG_ 820 UI_speedLimit 0;
BA_ "GenSigSNA" SG_ 820 UI_speedLimit "511";
BA_ "Confidence" SG_ 820 UI_enableSmartShift 0;
BA_ "Confidence" SG_ 820 UI_navVehParallelToRdCanContinue 0;
BA_ "GenSigSNA" SG_ 820 UI_navVehParallelToRdCanContinue "0";
BA_ "Confidence" SG_ 698 UI_radarTargetDx 1;
BA_ "Confidence" SG_ 698 UI_radarTargetDxEnd 1;
BA_ "Confidence" SG_ 632 UI_roadCurvC0 1;
BA_ "Confidence" SG_ 632 UI_roadCurvC1 1;
BA_ "Confidence" SG_ 632 UI_roadCurvC2 1;
BA_ "Confidence" SG_ 632 UI_roadCurvC3 1;
BA_ "Confidence" SG_ 632 UI_roadCurvRange 1;
BA_ "Confidence" SG_ 632 UI_roadCurvHealth 1;
BA_ "Confidence" SG_ 723 UI_solarAzimuthAngle 1;
BA_ "GenSigSNA" SG_ 723 UI_solarAzimuthAngle "32768";
BA_ "Confidence" SG_ 723 UI_solarAzimuthAngleCarRef 1;
BA_ "GenSigSNA" SG_ 723 UI_solarAzimuthAngleCarRef "255";
BA_ "Confidence" SG_ 723 UI_isSunUp 0;
BA_ "GenSigSNA" SG_ 723 UI_isSunUp "3";
BA_ "Confidence" SG_ 723 UI_solarElevationAngle 0;
BA_ "GenSigSNA" SG_ 723 UI_solarElevationAngle "127";
BA_ "Confidence" SG_ 723 UI_screenPCBTemperature 0;
BA_ "Confidence" SG_ 723 UI_minsToSunset 0;
BA_ "Confidence" SG_ 723 UI_minsToSunrise 0;
BA_ "Confidence" SG_ 851 UI_touchActive 0;
BA_ "Confidence" SG_ 851 UI_audioActive 0;
BA_ "Confidence" SG_ 851 UI_cellActive 0;
BA_ "Confidence" SG_ 851 UI_displayReady 0;
BA_ "Confidence" SG_ 851 UI_displayOn 0;
BA_ "Confidence" SG_ 851 UI_wifiActive 0;
BA_ "Confidence" SG_ 851 UI_wifiConnected 0;
BA_ "Confidence" SG_ 851 UI_readyForDrive 0;
BA_ "Confidence" SG_ 851 UI_cellConnected 0;
BA_ "Confidence" SG_ 851 UI_vpnActive 0;
BA_ "Confidence" SG_ 851 UI_autopilotTrial 1;
BA_ "Confidence" SG_ 851 UI_factoryReset 0;
BA_ "GenSigSNA" SG_ 851 UI_factoryReset "0";
BA_ "Confidence" SG_ 851 UI_gpsActive 0;
BA_ "Confidence" SG_ 851 UI_cellNetworkTechnology 0;
BA_ "GenSigSNA" SG_ 851 UI_cellNetworkTechnology "15";
BA_ "Confidence" SG_ 851 UI_cellReceiverPower 1;
BA_ "Confidence" SG_ 851 UI_falseTouchCounter 0;
BA_ "Confidence" SG_ 851 UI_cellSignalBars 0;
BA_ "GenSigSNA" SG_ 851 UI_cellSignalBars "7";
BA_ "Confidence" SG_ 851 UI_trailerModeTelltale 0;
BA_ "Confidence" SG_ 851 UI_pcbTemperature 0;
BA_ "Confidence" SG_ 851 UI_cpuTemperature 0;
BA_ "Confidence" SG_ 991 UI_userActivity 0;
BA_ "Confidence" SG_ 991 UI_activeTouchPoints 0;
BA_ "Confidence" SG_ 991 UI_linkState 0;
BA_ "Confidence" SG_ 991 UI_sentryModeState 1;
BA_ "GenSigSNA" SG_ 991 UI_sentryModeState "6";
BA_ "Confidence" SG_ 991 UI_autopilotSentryRequest 0;
BA_ "Confidence" SG_ 991 UI_mobileAppConnected 0;
BA_ "Confidence" SG_ 991 UI_phoneLeftInCabin 0;
BA_ "Confidence" SG_ 991 UI_autoshiftDRState 0;
BA_ "Confidence" SG_ 991 UI_wifiBtModuleType 0;
BA_ "Confidence" SG_ 991 UI_sohHealthStatus 1;
BA_ "Confidence" SG_ 991 UI_selfParkState 0;
BA_ "GenSigSNA" SG_ 991 UI_selfParkState "255";
BA_ "Confidence" SG_ 991 UI_summonDeviceIndex 0;
BA_ "Confidence" SG_ 991 UI_fullScreenMode 0;
BA_ "Confidence" SG_ 988 UI_goalLatitude 1;
BA_ "Confidence" SG_ 988 UI_goalLongitude 1;
BA_ "Confidence" SG_ 988 UI_goalOrientation 1;
BA_ "Confidence" SG_ 1064 UI_TCR_minRCS 1;
BA_ "Confidence" SG_ 1064 UI_TCR_maxDy 1;
BA_ "Confidence" SG_ 856 UI_TPMSMode 1;
BA_ "Confidence" SG_ 856 UI_TPMSLearnIDMode 1;
BA_ "Confidence" SG_ 856 UI_sizeOfWheelSelect 1;
BA_ "Confidence" SG_ 952 UI_sendCalibrateTireRequest 0;
BA_ "Confidence" SG_ 952 UI_setRCPFront 1;
BA_ "Confidence" SG_ 952 UI_setRCPRear 1;
VAL_ 882 TRCM_matrixIndex 10 "AlertMatrix10" 9 "AlertMatrix9" 7 "AlertMatrix7" 6 "AlertMatrix6" 5 "AlertMatrix5" 4 "AlertMatrix4" 3 "AlertMatrix3" 2 "AlertMatrix2" 1 "AlertMatrix1" 0 "AlertMatrix0" ;
VAL_ 850 TRCM_infoIndex 255 "END" 41 "SUBCOMPONENT14" 40 "SUBCOMPONENT13" 39 "SUBCOMPONENT12" 38 "SUBCOMPONENT11" 37 "SUBCOMPONENT10" 36 "SUBCOMPONENT9" 35 "SUBCOMPONENT8" 34 "SUBCOMPONENT7" 33 "SUBCOMPONENT6" 32 "SUBCOMPONENT5" 31 "SUBCOMPONENT4" 24 "SUBCOMPONENT3" 23 "SUBCOMPONENT2" 20 "UDS_PROTOCOL_BOOTCRC" 19 "VERSION_DEPRECATED" 18 "BOOTLOADER_GITHASH" 17 "APP_GITHASH" 16 "SUBCOMPONENT1" 15 "BOOTLOADER_CRC" 14 "BOOTLOADER_SVN" 13 "APP_CRC" 11 "PCBAID_ASSYID_USAGEID" 10 "BUILD_HWID_COMPONENTID" 9 "DEPRECATED_9" 8 "DEPRECATED_8" 7 "DEPRECATED_7" 6 "DEPRECATED_6" 5 "DEPRECATED_5" 4 "DEPRECATED_4" 3 "DEPRECATED_3" 2 "DEPRECATED_2" 1 "DEPRECATED_1" 0 "DEPRECATED_0" ;
VAL_ 850 TRCM_infoBuildType 4 "INFO_MFG_BUILD" 3 "INFO_TRACEABLE_CI_BUILD" 2 "INFO_LOCAL_BUILD" 1 "INFO_PLATFORM_BUILD" 0 "INFO_UNKNOWN_BUILD" ;
VAL_ 850 TRCM_infoAssemblyId 255 "ASSEMBLY_SNA" 1 "ASSEMBLY1" ;
VAL_ 1021 UI_autopilotControlIndex 7 "7" 6 "6" 5 "5" 4 "4" 3 "3" 2 "2" 1 "1" 0 "0" ;
VAL_ 1021 UI_hovEnabled 1 "HOV_ON" 0 "HOV_OFF" ;
VAL_ 1021 UI_donDisableAutoWiperDuration 6 "OFF" 5 "120_S" 4 "60_S" 3 "30_S" 2 "15_S" 1 "5_S" 0 "DEFAULT" ;
VAL_ 1021 UI_donDisableOnAutoWiperSpeed 15 "INVALID" 14 "14" 13 "13" 12 "12" 11 "11" 10 "10" 9 "9" 8 "8" 7 "7" 6 "6" 5 "5" 4 "4" 3 "3" 2 "2" 1 "1" 0 "OFF" ;
VAL_ 1021 UI_blindspotMinSpeed 10 "OFF" 9 "45_KPH" 8 "40_KPH" 7 "35_KPH" 6 "30_KPH" 5 "25_KPH" 4 "20_KPH" 3 "15_KPH" 2 "10_KPH" 1 "5_KPH" 0 "DEFAULT" ;
VAL_ 1021 UI_blindspotDistance 5 "OFF" 4 "4_M" 3 "2_M" 2 "1_M" 1 "0P5_M" 0 "DEFAULT" ;
VAL_ 1021 UI_blindspotTTC 7 "OFF" 6 "5_S" 5 "3_S" 4 "4_S" 3 "2_S" 2 "1_S" 1 "0P5_S" 0 "DEFAULT" ;
VAL_ 1021 UI_donStopEndOfRampBuffer 4 "OFF" 3 "45_M" 2 "30_M" 1 "15_M" 0 "DEFAULT" ;
VAL_ 1021 UI_donDisableCutin 1 "ON" 0 "OFF" ;
VAL_ 1021 UI_smartSetSpeedOffsetType 1 "PERCENTAGE_OFFSET" 0 "FIXED_OFFSET" ;
VAL_ 1021 UI_homelinkNearby 1 "NEARBY" 0 "NOT_NEARBY" ;
VAL_ 1021 UI_autosteerActivation 1 "DOUBLE_CLICK" 0 "SINGLE_CLICK" ;
VAL_ 1021 UI_fsdBetaRequest 1 "FSD_REQUEST_ACTIVE" 0 "FSD_REQUEST_NOT_ACTIVE" ;
VAL_ 1021 UI_selectableCameraRequest 15 "SNA" 13 "REPEATERS_BACKUP" 12 "FASCIA" 11 "GRID_VIEW" 10 "OCTA" 9 "BACKUP" 8 "RIGHT_REPEATER" 7 "RIGHT_PILLAR" 6 "LEFT_REPEATER" 5 "LEFT_PILLAR" 4 "FRONT_NARROW" 3 "FRONT_FISHEYE" 2 "FRONT_MAIN" 1 "SELFIE" 0 "NONE" ;
VAL_ 1021 UI_overrideSleepWithSuspend 1 "ENABLED" 0 "DISABLED" ;
VAL_ 1021 UI_regulatoryLaneAssistLevel 1 "ASSIST" 0 "WARNING" ;
VAL_ 1021 UI_apmv3Branch 5 "DEMO" 4 "EAP" 3 "STAGE2" 2 "DEV" 1 "STAGE" 0 "LIVE" ;
VAL_ 1021 UI_autoTurnSignalMode 1 "UI_AUTO_TURN_SIGNAL_MODE_AUTO_CANCEL" 0 "UI_AUTO_TURN_SIGNAL_MODE_OFF" ;
VAL_ 1021 UI_autopilotDrivingProfile 4 "CONSERVATIVE" 3 "MAD_MAX" 2 "ASSERTIVE" 1 "NORMAL" 0 "CHILL" ;
VAL_ 659 UI_steeringTuneRequest 2 "STEERING_TUNE_SPORT" 1 "STEERING_TUNE_STANDARD" 0 "STEERING_TUNE_COMFORT" ;
VAL_ 659 UI_tractionControlMode 7 "TC_SLIPPERY_SURFACE_SELECTED" 6 "TC_OFFROAD_ASSIST_SELECTED" 5 "TC_DYNO_MODE_SELECTED" 4 "TC_ROLLS_MODE_SELECTED" 3 "TC_DEV_MODE_2_SELECTED" 2 "TC_DEV_MODE_1_SELECTED" 1 "TC_SLIP_START_SELECTED" 0 "TC_NORMAL_SELECTED" ;
VAL_ 659 UI_parkBrakeRequest 3 "PARK_BRAKE_REQUEST_SNA" 1 "PARK_BRAKE_REQUEST_PRESSED" 0 "PARK_BRAKE_REQUEST_IDLE" ;
VAL_ 659 UI_winchModeRequest 3 "WINCH_MODE_DIALOGUE_OPEN" 2 "WINCH_MODE_EXIT" 1 "WINCH_MODE_ENTER" 0 "WINCH_MODE_IDLE" ;
VAL_ 659 UI_zeroSpeedConfirmed 3 "SNA" 2 "UNUSED" 1 "CONFIRMED" 0 "CANCELED" ;
VAL_ 659 UI_trailerMode 1 "TRAILER_MODE_ON" 0 "TRAILER_MODE_OFF" ;
VAL_ 659 UI_distanceUnits 1 "MILES" 0 "KM" ;
VAL_ 659 UI_accOvertakeEnable 3 "SNA" 1 "ACC_OVERTAKE_ON" 0 "ACC_OVERTAKE_OFF" ;
VAL_ 659 UI_aebEnable 3 "SNA" 1 "AEB_ON" 0 "AEB_OFF" ;
VAL_ 659 UI_aesEnable 3 "SNA" 1 "AES_ON" 0 "AES_OFF" ;
VAL_ 659 UI_ahlbEnable 3 "SNA" 1 "AHLB_ON" 0 "AHLB_OFF" ;
VAL_ 659 UI_autoLaneChangeEnable 3 "SNA" 1 "ON" 0 "OFF" ;
VAL_ 659 UI_autoParkRequest 15 "SNA" 12 "BEGIN_PARKING" 11 "RESUME" 10 "PAUSE" 9 "SEARCH" 8 "COMPLETE" 7 "ABORT" 6 "PARALLEL_PULL_OUT_TO_RIGHT" 5 "PARALLEL_PULL_OUT_TO_LEFT" 4 "PARK_RIGHT_CROSS" 3 "PARK_RIGHT_PARALLEL" 2 "PARK_LEFT_CROSS" 1 "PARK_LEFT_PARALLEL" 0 "NONE" ;
VAL_ 659 UI_bsdEnable 3 "SNA" 1 "BSD_ON" 0 "BSD_OFF" ;
VAL_ 659 UI_fcwEnable 3 "SNA" 1 "FCW_ON" 0 "FCW_OFF" ;
VAL_ 659 UI_fcwSensitivity 3 "SNA" 2 "AEB_SENSITIVITY_LATE" 1 "AEB_SENSITIVITY_AVERAGE" 0 "AEB_SENSITIVITY_EARLY" ;
VAL_ 659 UI_latControlEnable 3 "LATERAL_CONTROL_SNA" 2 "LATERAL_CONTROL_UNAVAILABLE" 1 "LATERAL_CONTROL_ON" 0 "LATERAL_CONTROL_OFF" ;
VAL_ 659 UI_ldwEnable 3 "SNA" 1 "LDW_TRIGGERS_HAPTIC" 0 "NO_HAPTIC" ;
VAL_ 659 UI_pedalSafetyEnable 3 "SNA" 1 "PEDAL_SAFETY_ON" 0 "PEDAL_SAFETY_OFF" ;
VAL_ 659 UI_pedalMap_epas 2 "PERFORMANCE" 1 "SPORT" 0 "CHILL" ;
VAL_ 659 UI_redLightStopSignEnable 3 "SNA" 1 "RLSSW_ON" 0 "RLSSW_OFF" ;
VAL_ 659 UI_selfParkTune 15 "SNA" ;
VAL_ 1096 UI_anonDebugFlag1 1 "ON" 0 "OFF" ;
VAL_ 1096 UI_anonDebugFlag2 1 "ON" 0 "OFF" ;
VAL_ 1096 UI_anonDebugFlag3 1 "ON" 0 "OFF" ;
VAL_ 1096 UI_anonDebugFlag4 1 "ON" 0 "OFF" ;
VAL_ 1016 UI_autopilotControlRequest 1 "NEXT_GEN_CTRL" 0 "LEGACY_LAT_CTRL" ;
VAL_ 1016 UI_curvSpeedAdaptDisable 1 "OFF" 0 "ON" ;
VAL_ 1016 UI_lssLkaEnabled 1 "LKA_ON" 0 "LKA_OFF" ;
VAL_ 1016 UI_lssLdwEnabled 1 "LDW_ON" 0 "LDW_OFF" ;
VAL_ 1016 UI_exceptionListEnable 1 "ON" 0 "OFF" ;
VAL_ 1016 UI_roadCheckDisable 1 "OFF" 0 "ON" ;
VAL_ 1016 UI_driveOnMapsEnable 1 "DOM_ON" 0 "DOM_OFF" ;
VAL_ 1016 UI_handsOnRequirementDisable 1 "OFF" 0 "ON" ;
VAL_ 1016 UI_fuseLanesDisable 1 "OFF" 0 "ON" ;
VAL_ 1016 UI_fuseHPPDisable 1 "OFF" 0 "ON" ;
VAL_ 1016 UI_fuseVehiclesDisable 1 "OFF" 0 "ON" ;
VAL_ 1016 UI_visionSpeedType 3 "OPTIMIZED" 2 "TWO_SECOND" 1 "ONE_SECOND" 0 "DISABLED" ;
VAL_ 1016 UI_curvatureDatabaseOnly 1 "ON" 0 "OFF" ;
VAL_ 1016 UI_lssElkEnabled 1 "ELK_ON" 0 "ELK_OFF" ;
VAL_ 1016 UI_summonExitType 3 "SNA" 2 "TURN_LEFT" 1 "TURN_RIGHT" 0 "STRAIGHT" ;
VAL_ 1016 UI_summonEntryType 3 "SNA" 2 "TURN_LEFT" 1 "TURN_RIGHT" 0 "STRAIGHT" ;
VAL_ 1016 UI_selfParkRequest 15 "SNA" 12 "SMART_SUMMON_NO_OP" 11 "SMART_SUMMON" 10 "AUTO_SUMMON_PRIMED" 9 "AUTO_SUMMON_CANCEL" 8 "AUTO_SUMMON_REVERSE" 7 "AUTO_SUMMON_FORWARD" 6 "RESUME" 5 "PAUSE" 4 "PRIME" 3 "ABORT" 2 "SELF_PARK_REVERSE" 1 "SELF_PARK_FORWARD" 0 "NONE" ;
VAL_ 1016 UI_summonReverseDist 63 "SNA" ;
VAL_ 1016 UI_drivingSide 2 "UNKNOWN" 1 "RIGHT" 0 "LEFT" ;
VAL_ 1016 UI_accFollowDistanceSetting 7 "SNA" 6 "7" 5 "6" 4 "5" 3 "4" 2 "3" 1 "2" 0 "1" ;
VAL_ 1016 UI_followNavRouteEnable 1 "NAV_ROUTE_ON" 0 "NAV_ROUTE_OFF" ;
VAL_ 1016 UI_ulcSpeedConfig 3 "SPEED_BASED_ULC_MAD_MAX" 2 "SPEED_BASED_ULC_AVERAGE" 1 "SPEED_BASED_ULC_MILD" 0 "SPEED_BASED_ULC_DISABLED" ;
VAL_ 1016 UI_ulcBlindSpotConfig 2 "MAD_MAX" 1 "AGGRESSIVE" 0 "STANDARD" ;
VAL_ 1016 UI_smartSummonType 2 "SMART_AUTOPARK" 1 "FIND_ME" 0 "PIN_DROP" ;
VAL_ 1016 UI_source3D 2 "XYZ_PREDICTION" 1 "Z_FROM_PATH_PREDICTION" 0 "Z_FROM_MAP" ;
VAL_ 568 UI_mapSpeedLimitDependency 7 "SNA" 6 "LANE" 5 "SEASON" 4 "TIME" 3 "SNOW" 2 "RAIN" 1 "SCHOOL" 0 "NONE" ;
VAL_ 568 UI_roadClass 6 "CLASS_6_MINOR" 5 "CLASS_5" 4 "CLASS_4" 3 "CLASS_3" 2 "CLASS_2" 1 "CLASS_1_MAJOR" 0 "UNKNOWN_INVALID_SNA" ;
VAL_ 568 UI_mapSpeedUnits 1 "KPH" 0 "MPH" ;
VAL_ 568 UI_mapSpeedLimit 31 "SNA" 30 "UNLIMITED" 29 "LESS_OR_EQ_160" 28 "LESS_OR_EQ_150" 27 "LESS_OR_EQ_140" 26 "LESS_OR_EQ_130" 25 "LESS_OR_EQ_120" 24 "LESS_OR_EQ_115" 23 "LESS_OR_EQ_110" 22 "LESS_OR_EQ_105" 21 "LESS_OR_EQ_100" 20 "LESS_OR_EQ_95" 19 "LESS_OR_EQ_90" 18 "LESS_OR_EQ_85" 17 "LESS_OR_EQ_80" 16 "LESS_OR_EQ_75" 15 "LESS_OR_EQ_70" 14 "LESS_OR_EQ_65" 13 "LESS_OR_EQ_60" 12 "LESS_OR_EQ_55" 11 "LESS_OR_EQ_50" 10 "LESS_OR_EQ_45" 9 "LESS_OR_EQ_40" 8 "LESS_OR_EQ_35" 7 "LESS_OR_EQ_30" 6 "LESS_OR_EQ_25" 5 "LESS_OR_EQ_20" 4 "LESS_OR_EQ_15" 3 "LESS_OR_EQ_10" 2 "LESS_OR_EQ_7" 1 "LESS_OR_EQ_5" 0 "UNKNOWN" ;
VAL_ 568 UI_mapSpeedLimitType 7 "UNKNOWN_SNA" 4 "BUMPS" 3 "DEPENDENT" 2 "ADVISORY" 1 "REGULAR" ;
VAL_ 568 UI_countryCode 1023 "SNA" 0 "UNKNOWN" ;
VAL_ 568 UI_nextBranchDist 31 "SNA" ;
VAL_ 536 UI_roadSign 255 "SNA" 5 "SPLINE_ID_FULL" 4 "SPEED_SPLINE" 3 "SPEED_LIMIT" 2 "TRAFFIC_LIGHT" 1 "STOP_SIGN" 0 "NONE" ;
VAL_ 536 UI_splineLocConfidence 0 "SNA" ;
VAL_ 536 UI_stopSignStopLineDist 1023 "SNA" ;
VAL_ 536 UI_stopSignStopLineConf 0 "SNA" ;
VAL_ 536 UI_trafficLightStopLineDist 1023 "SNA" ;
VAL_ 536 UI_trafficLightStopLineConf 0 "SNA" ;
VAL_ 536 UI_baseMapSpeedLimitMPS 255 "SNA" ;
VAL_ 536 UI_bottomQrtlFleetSpeedMPS 255 "SNA" ;
VAL_ 536 UI_topQrtlFleetSpeedMPS 255 "SNA" ;
VAL_ 536 UI_meanFleetSplineSpeedMPS 255 "SNA" ;
VAL_ 536 UI_medianFleetSpeedMPS 255 "SNA" ;
VAL_ 536 UI_meanFleetSplineAccelMPS2 255 "SNA" ;
VAL_ 536 UI_rampType 4 "INTERCHANGE_EXIT" 3 "INTERCHANGE_ENTRANCE" 2 "EXIT" 1 "ENTRANCE" 0 "NONE_SNA" ;
VAL_ 536 UI_valhallaRamp 2 "ON_RAMP" 1 "NOT_ON_RAMP" 0 "SNA" ;
VAL_ 536 UI_currSplineIdFull 0 "SNA" ;
VAL_ 760 UI_mapSpeedLimitUnits 1 "KPH" 0 "MPH" ;
VAL_ 760 UI_userSpeedOffsetUnits 1 "KPH" 0 "MPH" ;
VAL_ 760 UI_conditionalSpeedLimit 31 "SNA" ;
VAL_ 777 UI_gpsAccuracy 127 "SNA" ;
VAL_ 1011 UI_odometer 16777215 "SNA" ;
VAL_ 987 UI_phoneGpsAccuracy 127 "SNA" ;
VAL_ 820 UI_systemPowerLimit 31 "SNA" ;
VAL_ 820 UI_pedalMap 2 "PERFORMANCE" 1 "SPORT" 0 "CHILL" ;
VAL_ 820 UI_systemTorqueLimit 63 "SNA" ;
VAL_ 820 UI_closureConfirmed 3 "TRUNK" 2 "PROX" 1 "FRUNK" 0 "NONE" ;
VAL_ 820 UI_limitMode 3 "LIMIT_SERVICE" 2 "LIMIT_FACTORY" 1 "LIMIT_VALET" 0 "LIMIT_NORMAL" ;
VAL_ 820 UI_motorOnMode 2 "MOTORONMODE_REAR_ONLY" 1 "MOTORONMODE_FRONT_ONLY" 0 "MOTORONMODE_NORMAL" ;
VAL_ 820 UI_stoppingMode 2 "HOLD" 1 "CREEP" 0 "STANDARD" ;
VAL_ 820 UI_speedLimit 511 "SNA" ;
VAL_ 820 UI_enableSmartShift 2 "ENABLED_P_R_D" 1 "ENABLED_P" 0 "OFF" ;
VAL_ 820 UI_navVehParallelToRdCanContinue 2 "TRUE" 1 "FALSE" 0 "SNA" ;
VAL_ 698 UI_radarTargetDx 255 "NO_OBJECT" ;
VAL_ 698 UI_radarTargetDxEnd 255 "NO_OBJECT" ;
VAL_ 632 UI_roadCurvHealth 3 "DATABASE" 2 "AVAILABLE" 1 "DEGRADED" 0 "UNAVAILABLE" ;
VAL_ 723 UI_solarAzimuthAngle -32768 "SNA" ;
VAL_ 723 UI_solarAzimuthAngleCarRef 255 "SNA" ;
VAL_ 723 UI_isSunUp 3 "SUN_SNA" 1 "SUN_UP" 0 "SUN_DOWN" ;
VAL_ 723 UI_solarElevationAngle 127 "SNA" ;
VAL_ 851 UI_autopilotTrial 3 "ACTIVE" 2 "STOP" 1 "START" 0 "NONE" ;
VAL_ 851 UI_factoryReset 3 "CUSTOMER" 2 "DIAGNOSTIC" 1 "DEVELOPER" 0 "NONE_SNA" ;
VAL_ 851 UI_cellNetworkTechnology 15 "CELL_NETWORK_SNA" 14 "CELL_NETWORK_NGRAN" 13 "CELL_NETWORK_5GSA" 12 "CELL_NETWORK_5GNSA" 11 "CELL_NETWORK_LTE5GCN" 10 "CELL_NETWORK_WCDMA" 9 "CELL_NETWORK_CDMA" 8 "CELL_NETWORK_GSM" 7 "CELL_NETWORK_LTE" 6 "CELL_NETWORK_HSPA" 5 "CELL_NETWORK_HSUPA" 4 "CELL_NETWORK_HSDPA" 3 "CELL_NETWORK_UMTS" 2 "CELL_NETWORK_EDGE" 1 "CELL_NETWORK_GPRS" 0 "CELL_NETWORK_NONE" ;
VAL_ 851 UI_cellSignalBars 7 "SNA" 5 "FIVE" 4 "FOUR" 3 "THREE" 2 "TWO" 1 "ONE" 0 "ZERO" ;
VAL_ 851 UI_trailerModeTelltale 3 "TRAILER_MODE_TELLTALE_RED" 2 "TRAILER_MODE_TELLTALE_YELLOW" 1 "TRAILER_MODE_TELLTALE_BLUE" 0 "TRAILER_MODE_TELLTALE_OFF" ;
VAL_ 991 UI_userActivity 1 "USER_ACTIVE" 0 "USER_IDLE" ;
VAL_ 991 UI_linkState 2 "LINK_STATE_WIFI" 1 "LINK_STATE_CELL" 0 "LINK_STATE_NONE" ;
VAL_ 991 UI_sentryModeState 6 "SNA" 5 "QUIET" 4 "PANIC" 3 "AWARE" 2 "ARMED" 1 "IDLE" 0 "OFF" ;
VAL_ 991 UI_mobileAppConnected 1 "CONNECTED" 0 "NOT_CONNECTED" ;
VAL_ 991 UI_autoshiftDRState 6 "AUTOSHIFT_DR_STATE_BRAKE_GEAR_SHIFT_CONFIRMED_D" 5 "AUTOSHIFT_DR_STATE_BRAKE_GEAR_SHIFT_CONFIRMED_R" 4 "AUTOSHIFT_DR_STATE_BRAKE_STEERING_AND_BRAKE_CONFIRMED" 3 "AUTOSHIFT_DR_STATE_ONLY_STEERING_CONFIRMED" 2 "AUTOSHIFT_DR_STATE_ONLY_BRAKE_CONFIRMED" 1 "AUTOSHIFT_DR_STATE_PROMPT_SHOWING_UNCONFIRMED" 0 "AUTOSHIFT_DR_STATE_INACTIVE" ;
VAL_ 991 UI_wifiBtModuleType 4 "ELEKTRA" 3 "TCU4G" 2 "BCM4359" 1 "QCA6595" 0 "UNKNOWN" ;
VAL_ 991 UI_sohHealthStatus 3 "OK" 2 "REDUCED" 1 "NO_INTERNET" 0 "UNKNOWN" ;
VAL_ 991 UI_selfParkState 255 "SNA" 52 "SELF_PARK_USER_PAUSED" 51 "SELF_PARK_REMOTE_PRE_ABORT" 50 "SELF_PARK_RESUME" 49 "SELF_PARK_PAUSE" 48 "SELF_PARK_DV_MISMATCH" 47 "SELF_PARK_DI_PANIC" 46 "SELF_PARK_POST_ACTIVE_FAILURE" 45 "SELF_PARK_POST_ACTIVE_SUCCESS" 44 "SELF_PARK_CANCEL_AUTO_SUMMON" 43 "SELF_PARK_REMOTE_ABORT" 42 "SELF_PARK_OBSTACLE_NOT_CLEARED" 41 "SELF_PARK_OBSTACLE_CLEARED" 40 "SELF_PARK_OPEN_GATE" 39 "SELF_PARK_ACTIVE" 38 "SELF_PARK_STARTED_REVERSE" 37 "SELF_PARK_STARTED_FORWARD" 36 "SELF_PARK_NOT_STARTED_TIMEOUT" 35 "SELF_PARK_PRIMED" 34 "SELF_PARK_PREPRIMED" 33 "SELF_PARK_TURN_ON_DRIVE_RAIL" 32 "SELF_PARK_DETECT_KEY_FOB" 31 "SELF_PARK_WAKE_UP_BUSES" 30 "SELF_PARK_CONNECTING_BLUETOOTH" 29 "SELF_PARK_UNAVAILABLE_CAR_WASH_MODE" 28 "SELF_PARK_UNAVAILABLE_CAR_ALARM" 27 "SELF_PARK_UNAVAILABLE_CRASH_STATE" 26 "SELF_PARK_UNAVAILABLE_DRAG_STRIP_MODE" 25 "SELF_PARK_UNAVAILABLE_TRACK_MODE" 24 "SELF_PARK_UNAVAILABLE_SERVICE_MODE" 23 "SELF_PARK_UNAVAILABLE_DOG_MODE" 22 "SELF_PARK_UNAVAILABLE_GAME_MODE" 21 "SELF_PARK_UNAVAILABLE_BLUETOOTH_CONNECT_TIMEOUT" 20 "SELF_PARK_UNAVAILABLE_WAKEUP_TIMEOUT" 19 "SELF_PARK_UNAVAILABLE_NO_BLUETOOTH_DEVICES_PAIRED" 18 "SELF_PARK_UNAVAILABLE_BRAKE_PRESSED" 17 "SELF_PARK_UNAVAILABLE_ROAD_GRADE" 16 "SELF_PARK_UNAVAILABLE_TRAILER_MODE" 15 "SELF_PARK_UNAVAILABLE_KEY_FOB_BATTERY_LOW" 14 "SELF_PARK_UNAVAILABLE_KEY_FOB_NOT_DETECTED" 13 "SELF_PARK_UNAVAILABLE_PARK_SENSOR_ISSUE" 12 "SELF_PARK_UNAVAILABLE_AUTOSTEER_NOT_ENABLED" 11 "SELF_PARK_UNAVAILABLE_LV_BUS_SUPPORT_ISSUE" 10 "SELF_PARK_UNAVAILABLE_ON_PUBLIC_ROAD" 9 "SELF_PARK_UNAVAILABLE_PARKED_TOO_LONG" 8 "SELF_PARK_UNAVAILABLE_DOOR_OPEN" 7 "SELF_PARK_UNAVAILABLE_TRUNK_OPEN" 6 "SELF_PARK_UNAVAILABLE_FRUNK_OPEN" 5 "SELF_PARK_UNAVAILABLE_PLUGGED_IN" 4 "SELF_PARK_UNAVAILABLE_NOT_PARKED" 3 "SELF_PARK_UNAVAILABLE" 2 "SELF_PARK_IDLE" 1 "SELF_PARK_DRIVING" 0 "SELF_PARK_DISABLED" ;
VAL_ 991 UI_summonDeviceIndex 3 "UNKNOWN" 2 "DEVICE_2" 1 "DEVICE_1" 0 "DEVICE_0" ;
VAL_ 856 UI_TPMSMode 2 "PERFORMANCE_MODE" 1 "NORMAL_MODE" 0 "UNUSED_MODE" ;
VAL_ 856 UI_TPMSLearnIDMode 4 "AUTO_LOCATION_ACTIVE_AFTER_PWR" 3 "AUTO_LEARN_ACTIVE_AFTER_PWR" 2 "AUTO_LOCATION_ACTIVE_BY_MANUAL" 1 "AUTO_LEARN_ACTIVE_BY_MANUAL" 0 "NO_ID_LEARN_FUNCTION" ;
VAL_ 856 UI_sizeOfWheelSelect 2 "19_INCH_WHEEL" 1 "18_INCH_WHEEL" 0 "UNUSED" ;
